[part 5 of 12: package /E40_Platform_System_SystemPackage/Components]
AUTOSAR XML (schema 4-2-1)
package /E40_Platform_System_SystemPackage/Components  (continued)
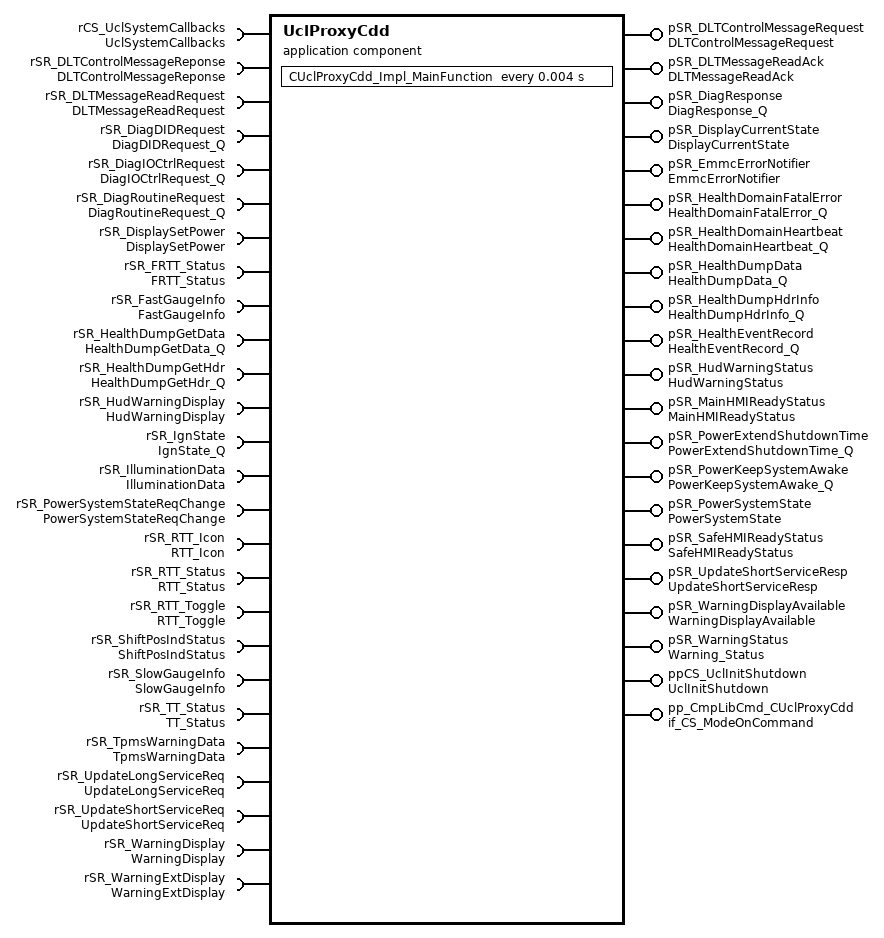
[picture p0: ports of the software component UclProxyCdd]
  application sw component type UclProxyCdd
    21 x provide port:
      pSR_DLTControlMessageRequest: nonqueued-sender-com-spec{data-element=DLTControlMessageRequestData, init-value=constant-reference=UclProxyCddDLTControlMessageRequestDataValue0}, provided-interface=DLTControlMessageRequest
      pSR_DLTMessageReadAck: nonqueued-sender-com-spec{data-element=DLTMessageReadAckData, init-value=constant-reference=UclProxyCddDLTMessageReadAckDataValue0}, provided-interface=DLTMessageReadAck
      pSR_DiagResponse: queued-sender-com-spec=DiagResponseData, provided-interface=DiagResponse_Q
      pSR_DisplayCurrentState: nonqueued-sender-com-spec{data-element=DisplayCurrentStateData, init-value=constant-reference=UclProxyCddDisplayCurrentStateDataValue0}, provided-interface=DisplayCurrentState
      pSR_EmmcErrorNotifier: nonqueued-sender-com-spec{data-element=EmmcErrorNotifierData, init-value=constant-reference=UclProxyCddEmmcErrorNotifierDataValue0}, provided-interface=EmmcErrorNotifier
      pSR_HealthDomainFatalError: queued-sender-com-spec=HealthDomainFatalErrorData, provided-interface=HealthDomainFatalError_Q
      pSR_HealthDomainHeartbeat: queued-sender-com-spec=HealthDomainHeartbeatData, provided-interface=HealthDomainHeartbeat_Q
      pSR_HealthDumpData: queued-sender-com-spec=HealthDumpDataData, provided-interface=HealthDumpData_Q
      pSR_HealthDumpHdrInfo: queued-sender-com-spec=HealthDumpHdrInfoData, provided-interface=HealthDumpHdrInfo_Q
      pSR_HealthEventRecord: queued-sender-com-spec=HealthEventRecordData, provided-interface=HealthEventRecord_Q
      pSR_HudWarningStatus: nonqueued-sender-com-spec{data-element=HudWarningStatusData, init-value=constant-reference=UclProxyCddHudWarningStatusDataValue0}, provided-interface=HudWarningStatus
      pSR_MainHMIReadyStatus: queued-sender-com-spec=MainHMIReadyStatusData, provided-interface=MainHMIReadyStatus
      pSR_PowerExtendShutdownTime: queued-sender-com-spec=PowerExtendShutdownTimeData, provided-interface=PowerExtendShutdownTime_Q
      pSR_PowerKeepSystemAwake: queued-sender-com-spec=PowerKeepSystemAwakeData, provided-interface=PowerKeepSystemAwake_Q
      pSR_PowerSystemState: nonqueued-sender-com-spec{data-element=PowerSystemStateData, init-value=constant-reference=UclProxyCddPowerSystemStateDataValue0}, provided-interface=PowerSystemState
      pSR_SafeHMIReadyStatus: queued-sender-com-spec=SafeHMIReadyStatusData, provided-interface=SafeHMIReadyStatus
      pSR_UpdateShortServiceResp: queued-sender-com-spec=UpdateShortServiceRespData, provided-interface=UpdateShortServiceResp
      pSR_WarningDisplayAvailable: nonqueued-sender-com-spec{data-element=WarningDisplayAvailableData, init-value=constant-reference=UclProxyCddWarningDisplayAvailableDataValue0}, provided-interface=WarningDisplayAvailable
      pSR_WarningStatus: nonqueued-sender-com-spec{data-element=WarningStatusData, init-value=constant-reference=UclProxyCddWarningStatusDataValue0}, provided-interface=Warning_Status
      ppCS_UclInitShutdown: provided-com-specs=[{operation=Impl_Initialize, queue-length=1}, {operation=Impl_Shutdown, queue-length=1}], provided-interface=UclInitShutdown
      pp_CmpLibCmd_CUclProxyCdd: server-com-spec{operation=Impl_OnCommand, queue-length=1}, provided-interface=if_CS_ModeOnCommand
    26 x require port:
      rCS_UclSystemCallbacks: required-interface=UclSystemCallbacks
      rSR_DLTControlMessageReponse: nonqueued-receiver-com-spec{data-element=DLTControlMessageReponseData, init-value=constant-reference=UclProxyCddDLTControlMessageReponseDataValue0}, required-interface=DLTControlMessageReponse
      rSR_DLTMessageReadRequest: nonqueued-receiver-com-spec{data-element=DLTMessageReadRequestData, init-value=constant-reference=UclProxyCddDLTMessageReadRequestDataValue0}, required-interface=DLTMessageReadRequest
      rSR_DiagDIDRequest: queued-receiver-com-spec{data-element=DiagDIDRequestData, queue-length=2}, required-interface=DiagDIDRequest_Q
      rSR_DiagIOCtrlRequest: queued-receiver-com-spec{data-element=DiagIOCtrlRequestData, queue-length=2}, required-interface=DiagIOCtrlRequest_Q
      rSR_DiagRoutineRequest: queued-receiver-com-spec{data-element=DiagRoutineRequestData, queue-length=2}, required-interface=DiagRoutineRequest_Q
      rSR_DisplaySetPower: nonqueued-receiver-com-spec{data-element=DisplaySetPower/DisplaySetPowerData, init-value=constant-reference=UclProxyCddDisplaySetPowerDataValue0}, required-interface=DisplaySetPower
      rSR_FRTT_Status: nonqueued-receiver-com-spec{data-element=FRTT_StatusData, init-value=constant-reference=UclProxyCddFRTT_StatusDataValue0}, required-interface=FRTT_Status
      rSR_FastGaugeInfo: nonqueued-receiver-com-spec{data-element=FastGaugeInfoData, init-value=constant-reference=UclProxyCddFastGaugeInfoDataValue0}, required-interface=FastGaugeInfo
      rSR_HealthDumpGetData: queued-receiver-com-spec{data-element=HealthDumpGetDataData, queue-length=1}, required-interface=HealthDumpGetData_Q
      rSR_HealthDumpGetHdr: queued-receiver-com-spec{data-element=HealthDumpGetHdrData, queue-length=1}, required-interface=HealthDumpGetHdr_Q
      rSR_HudWarningDisplay: nonqueued-receiver-com-spec{data-element=HudWarningDisplayData, init-value=constant-reference=UclProxyCddHudWarningDisplayDataValue0}, required-interface=HudWarningDisplay
      rSR_IgnState: queued-receiver-com-spec{data-element=IgnStateData, queue-length=5}, required-interface=IgnState_Q
      rSR_IlluminationData: nonqueued-receiver-com-spec{data-element=IlluminationDataData, init-value=constant-reference=UclProxyCddIlluminationDataDataValue0}, required-interface=IlluminationData
      rSR_PowerSystemStateReqChange: nonqueued-receiver-com-spec{data-element=PowerSystemStateReqChangeData, init-value=constant-reference=UclProxyCddPowerSystemStateReqChangeDataValue0}, required-interface=PowerSystemStateReqChange
      rSR_RTT_Icon: nonqueued-receiver-com-spec{data-element=RTT_IconData, init-value=constant-reference=UclProxyCddRTT_IconDataValue0}, required-interface=RTT_Icon
      rSR_RTT_Status: nonqueued-receiver-com-spec{data-element=RTT_StatusData, init-value=constant-reference=UclProxyCddRTT_StatusDataValue0}, required-interface=RTT_Status
      rSR_RTT_Toggle: nonqueued-receiver-com-spec{data-element=RTT_ToggleData, init-value=constant-reference=UclProxyCddRTT_ToggleDataValue0}, required-interface=RTT_Toggle
      rSR_ShiftPosIndStatus: nonqueued-receiver-com-spec{data-element=ShiftPosIndStatusData, init-value=constant-reference=UclProxyCddShiftPosIndStatusDataValue0}, required-interface=ShiftPosIndStatus
      rSR_SlowGaugeInfo: nonqueued-receiver-com-spec{data-element=SlowGaugeInfoData, init-value=constant-reference=UclProxyCddSlowGaugeInfoDataValue0}, required-interface=SlowGaugeInfo
      rSR_TT_Status: nonqueued-receiver-com-spec{data-element=TT_StatusData, init-value=constant-reference=UclProxyCddTT_StatusDataValue0}, required-interface=TT_Status
      rSR_TpmsWarningData: nonqueued-receiver-com-spec{data-element=TpmsWarningDataData, init-value=constant-reference=UclProxyCddTpmsWarningDataDataValue0}, required-interface=TpmsWarningData
      rSR_UpdateLongServiceReq: queued-receiver-com-spec{data-element=UpdateLongServiceReqData, queue-length=2}, required-interface=UpdateLongServiceReq
      rSR_UpdateShortServiceReq: queued-receiver-com-spec{data-element=UpdateShortServiceReqData, queue-length=2}, required-interface=UpdateShortServiceReq
      rSR_WarningDisplay: nonqueued-receiver-com-spec{data-element=WarningDisplayData, init-value=constant-reference=UclProxyCddWarningDisplayDataValue0}, required-interface=WarningDisplay
      rSR_WarningExtDisplay: nonqueued-receiver-com-spec{data-element=WarningExtDisplayData, init-value=constant-reference=UclProxyCddWarningExtDisplayDataValue0}, required-interface=WarningExtDisplay
    behavior IB_UclProxyCdd
      operation invoked event OIE_ppCS_UclInitShutdown_CUclProxyCdd_Impl_InitializeTrigByImpl_Initialize: start-on-event=CUclProxyCdd_Impl_Initialize, operation=ppCS_UclInitShutdown.Impl_Initialize
      timing event TECUclProxyCdd_Impl_MainFunction: start-on-event=CUclProxyCdd_Impl_MainFunction, period=0.004
      operation invoked event OIE_pp_CmpLibCmd_CUclProxyCdd_CUclProxyCdd_Impl_OnCommandTrigByImpl_OnCommand: start-on-event=CUclProxyCdd_Impl_OnCommand, operation=pp_CmpLibCmd_CUclProxyCdd.Impl_OnCommand
      operation invoked event OIE_ppCS_UclInitShutdown_CUclProxyCdd_Impl_ShutdownTrigByImpl_Shutdown: start-on-event=CUclProxyCdd_Impl_Shutdown, operation=ppCS_UclInitShutdown.Impl_Shutdown
      22 x data received event:
        DREOnDre_DLTControlMessageReponseTrigByDLTControlMessageReponseData: start-on-event=OnDre_DLTControlMessageReponse, data=rSR_DLTControlMessageReponse.DLTControlMessageReponseData
        DREOnDre_DLTMessageReadRequestTrigByDLTMessageReadRequestData: start-on-event=OnDre_DLTMessageReadRequest, data=rSR_DLTMessageReadRequest.DLTMessageReadRequestData
        DREOnDre_DiagDIDRequestTrigByDiagDIDRequestData: start-on-event=OnDre_DiagDIDRequest, data=rSR_DiagDIDRequest.DiagDIDRequestData
        DREOnDre_DiagIOCtrlRequestTrigByDiagIOCtrlRequestData: start-on-event=OnDre_DiagIOCtrlRequest, data=rSR_DiagIOCtrlRequest.DiagIOCtrlRequestData
        DREOnDre_DiagRoutineRequestTrigByDiagRoutineRequestData: start-on-event=OnDre_DiagRoutineRequest, data=rSR_DiagRoutineRequest.DiagRoutineRequestData
        DREOnDre_DisplaySetPowerTrigByDisplaySetPowerData: start-on-event=OnDre_DisplaySetPower, data=rSR_DisplaySetPower.DisplaySetPowerData
        DREOnDre_FRTT_StatusTrigByFRTT_StatusData: start-on-event=OnDre_FRTT_Status, data=rSR_FRTT_Status.FRTT_StatusData
        DREOnDre_FastGaugeInfoTrigByFastGaugeInfoData: start-on-event=OnDre_FastGaugeInfo, data=rSR_FastGaugeInfo.FastGaugeInfoData
        DREOnDre_HealthDumpGetDataTrigByHealthDumpGetDataData: start-on-event=OnDre_HealthDumpGetData, data=rSR_HealthDumpGetData.HealthDumpGetDataData
        DREOnDre_HealthDumpGetHdrTrigByHealthDumpGetHdrData: start-on-event=OnDre_HealthDumpGetHdr, data=rSR_HealthDumpGetHdr.HealthDumpGetHdrData
        DREOnDre_IlluminationDataTrigByIlluminationDataData: start-on-event=OnDre_IlluminationData, data=rSR_IlluminationData.IlluminationDataData
        DREOnDre_PowerSystemStateReqChangeTrigByPowerSystemStateReqChangeData: start-on-event=OnDre_PowerSystemStateReqChange, data=rSR_PowerSystemStateReqChange.PowerSystemStateReqChangeData
        DREOnDre_RTT_IconTrigByRTT_IconData: start-on-event=OnDre_RTT_Icon, data=rSR_RTT_Icon.RTT_IconData
        DREOnDre_RTT_StatusTrigByRTT_StatusData: start-on-event=OnDre_RTT_Status, data=rSR_RTT_Status.RTT_StatusData
        DREOnDre_RTT_ToggleTrigByRTT_ToggleData: start-on-event=OnDre_RTT_Toggle, data=rSR_RTT_Toggle.RTT_ToggleData
        DREOnDre_ShiftPosIndStatusTrigByShiftPosIndStatusData: start-on-event=OnDre_ShiftPosIndStatus, data=rSR_ShiftPosIndStatus.ShiftPosIndStatusData
        DREOnDre_SlowGaugeInfoTrigBySlowGaugeInfoData: start-on-event=OnDre_SlowGaugeInfo, data=rSR_SlowGaugeInfo.SlowGaugeInfoData
        DREOnDre_TT_StatusTrigByTT_StatusData: start-on-event=OnDre_TT_Status, data=rSR_TT_Status.TT_StatusData
        DREOnDre_UpdateLongServiceReqTrigByUpdateLongServiceReqData: start-on-event=OnDre_UpdateLongServiceReq, data=rSR_UpdateLongServiceReq.UpdateLongServiceReqData
        DREOnDre_UpdateShortServiceReqTrigByUpdateShortServiceReqData: start-on-event=OnDre_UpdateShortServiceReq, data=rSR_UpdateShortServiceReq.UpdateShortServiceReqData
        DREOnDre_WarningDisplayTrigByWarningDisplayData: start-on-event=OnDre_WarningDisplay, data=rSR_WarningDisplay.WarningDisplayData
        DREOnDre_WarningExtDisplayTrigByWarningExtDisplayData: start-on-event=OnDre_WarningExtDisplay, data=rSR_WarningExtDisplay.WarningExtDisplayData
      port-api-options:
        enable-take-address=false, indirect-api=false, port=pSR_DLTControlMessageRequest
        enable-take-address=false, indirect-api=false, port=pSR_DLTMessageReadAck
        enable-take-address=false, indirect-api=false, port=pSR_DiagResponse
        enable-take-address=false, indirect-api=false, port=pSR_DisplayCurrentState
        enable-take-address=false, indirect-api=false, port=pSR_EmmcErrorNotifier
        enable-take-address=false, indirect-api=false, port=pSR_HealthDomainFatalError
        enable-take-address=false, indirect-api=false, port=pSR_HealthDomainHeartbeat
        enable-take-address=false, indirect-api=false, port=pSR_HealthDumpData
        enable-take-address=false, indirect-api=false, port=pSR_HealthDumpHdrInfo
        enable-take-address=false, indirect-api=false, port=pSR_HealthEventRecord
        enable-take-address=false, indirect-api=false, port=pSR_HudWarningStatus
        enable-take-address=false, indirect-api=false, port=pSR_MainHMIReadyStatus
        enable-take-address=false, indirect-api=false, port=pSR_PowerExtendShutdownTime
        enable-take-address=false, indirect-api=false, port=pSR_PowerKeepSystemAwake
        enable-take-address=false, indirect-api=false, port=pSR_PowerSystemState
        enable-take-address=false, indirect-api=false, port=pSR_SafeHMIReadyStatus
        enable-take-address=false, indirect-api=false, port=pSR_UpdateShortServiceResp
        enable-take-address=false, indirect-api=false, port=pSR_WarningDisplayAvailable
        enable-take-address=false, indirect-api=false, port=pSR_WarningStatus
        enable-take-address=false, indirect-api=false, port=ppCS_UclInitShutdown
        enable-take-address=false, indirect-api=false, port=pp_CmpLibCmd_CUclProxyCdd
        enable-take-address=false, indirect-api=false, port=rCS_UclSystemCallbacks
        enable-take-address=false, indirect-api=false, port=rSR_DLTControlMessageReponse
        enable-take-address=false, indirect-api=false, port=rSR_DLTMessageReadRequest
        enable-take-address=false, indirect-api=false, port=rSR_DiagDIDRequest
        enable-take-address=false, indirect-api=false, port=rSR_DiagIOCtrlRequest
        enable-take-address=false, indirect-api=false, port=rSR_DiagRoutineRequest
        enable-take-address=false, indirect-api=false, port=rSR_DisplaySetPower
        enable-take-address=false, indirect-api=false, port=rSR_FRTT_Status
        enable-take-address=false, indirect-api=false, port=rSR_FastGaugeInfo
        enable-take-address=false, indirect-api=false, port=rSR_HealthDumpGetData
        enable-take-address=false, indirect-api=false, port=rSR_HealthDumpGetHdr
        enable-take-address=false, indirect-api=false, port=rSR_HudWarningDisplay
        enable-take-address=false, indirect-api=false, port=rSR_IgnState
        enable-take-address=false, indirect-api=false, port=rSR_IlluminationData
        enable-take-address=false, indirect-api=false, port=rSR_PowerSystemStateReqChange
        enable-take-address=false, indirect-api=false, port=rSR_RTT_Icon
        enable-take-address=false, indirect-api=false, port=rSR_RTT_Status
        enable-take-address=false, indirect-api=false, port=rSR_RTT_Toggle
        enable-take-address=false, indirect-api=false, port=rSR_ShiftPosIndStatus
        enable-take-address=false, indirect-api=false, port=rSR_SlowGaugeInfo
        enable-take-address=false, indirect-api=false, port=rSR_TT_Status
        enable-take-address=false, indirect-api=false, port=rSR_TpmsWarningData
        enable-take-address=false, indirect-api=false, port=rSR_UpdateLongServiceReq
        enable-take-address=false, indirect-api=false, port=rSR_UpdateShortServiceReq
        enable-take-address=false, indirect-api=false, port=rSR_WarningDisplay
        enable-take-address=false, indirect-api=false, port=rSR_WarningExtDisplay
      26 x runnable, all with can-be-invoked-concurrently=true:
        CUclProxyCdd_Impl_Initialize
        CUclProxyCdd_Impl_MainFunction
          data-receive-point-by-arguments:
            25 x access:
              DRA_rSR_DLTControlMessageReponse_DLTControlMessageReponseData: accessed-variable=rSR_DLTControlMessageReponse.DLTControlMessageReponseData
              DRA_rSR_DLTMessageReadRequest_DLTMessageReadRequestData: accessed-variable=rSR_DLTMessageReadRequest.DLTMessageReadRequestData
              DRP_rSR_DiagDIDRequest_DiagDIDRequestData: accessed-variable=rSR_DiagDIDRequest.DiagDIDRequestData
              DRP_rSR_DiagIOCtrlRequest_DiagIOCtrlRequestData: accessed-variable=rSR_DiagIOCtrlRequest.DiagIOCtrlRequestData
              DRP_rSR_DiagRoutineRequest_DiagRoutineRequestData: accessed-variable=rSR_DiagRoutineRequest.DiagRoutineRequestData
              DRA_rSR_DisplaySetPower_DisplaySetPowerData: accessed-variable=rSR_DisplaySetPower.DisplaySetPowerData
              DRA_rSR_FRTT_Status_FRTT_StatusData: accessed-variable=rSR_FRTT_Status.FRTT_StatusData
              DRA_rSR_FastGaugeInfo_FastGaugeInfoData: accessed-variable=rSR_FastGaugeInfo.FastGaugeInfoData
              DRP_rSR_HealthDumpGetData_HealthDumpGetDataData: accessed-variable=rSR_HealthDumpGetData.HealthDumpGetDataData
              DRP_rSR_HealthDumpGetHdr_HealthDumpGetHdrData: accessed-variable=rSR_HealthDumpGetHdr.HealthDumpGetHdrData
              DRA_rSR_HudWarningDisplay_HudWarningDisplayData: accessed-variable=rSR_HudWarningDisplay.HudWarningDisplayData
              DRP_rSR_IgnState_IgnStateData: accessed-variable=rSR_IgnState.IgnStateData
              DRA_rSR_IlluminationData_IlluminationDataData: accessed-variable=rSR_IlluminationData.IlluminationDataData
              DRA_rSR_PowerSystemStateReqChange_PowerSystemStateReqChangeData: accessed-variable=rSR_PowerSystemStateReqChange.PowerSystemStateReqChangeData
              DRA_rSR_RTT_Icon_RTT_IconData: accessed-variable=rSR_RTT_Icon.RTT_IconData
              DRA_rSR_RTT_Status_RTT_StatusData: accessed-variable=rSR_RTT_Status.RTT_StatusData
              DRA_rSR_RTT_Toggle_RTT_ToggleData: accessed-variable=rSR_RTT_Toggle.RTT_ToggleData
              DRA_rSR_ShiftPosIndStatus_ShiftPosIndStatusData: accessed-variable=rSR_ShiftPosIndStatus.ShiftPosIndStatusData
              DRA_rSR_SlowGaugeInfo_SlowGaugeInfoData: accessed-variable=rSR_SlowGaugeInfo.SlowGaugeInfoData
              DRA_rSR_TT_Status_TT_StatusData: accessed-variable=rSR_TT_Status.TT_StatusData
              DRA_rSR_TpmsWarningData_TpmsWarningDataData: accessed-variable=rSR_TpmsWarningData.TpmsWarningDataData
              DRP_rSR_UpdateLongServiceReq_UpdateLongServiceReqData: accessed-variable=rSR_UpdateLongServiceReq.UpdateLongServiceReqData
              DRP_rSR_UpdateShortServiceReq_UpdateShortServiceReqData: accessed-variable=rSR_UpdateShortServiceReq.UpdateShortServiceReqData
              DRA_rSR_WarningDisplay_WarningDisplayData: accessed-variable=rSR_WarningDisplay.WarningDisplayData
              DRA_rSR_WarningExtDisplay_WarningExtDisplayData: accessed-variable=rSR_WarningExtDisplay.WarningExtDisplayData
          data-send-points:
            19 x access:
              DWA_pSR_DLTControlMessageRequest_DLTControlMessageRequestData: accessed-variable=pSR_DLTControlMessageRequest.DLTControlMessageRequestData
              DWA_pSR_DLTMessageReadAck_DLTMessageReadAckData: accessed-variable=pSR_DLTMessageReadAck.DLTMessageReadAckData
              DSP_pSR_DiagResponse_DiagResponseData: accessed-variable=pSR_DiagResponse.DiagResponseData
              DWA_pSR_DisplayCurrentState_DisplayCurrentStateData: accessed-variable=pSR_DisplayCurrentState.DisplayCurrentStateData
              DWA_pSR_EmmcErrorNotifier_EmmcErrorNotifierData: accessed-variable=pSR_EmmcErrorNotifier.EmmcErrorNotifierData
              DSP_pSR_HealthDomainFatalError_HealthDomainFatalErrorData: accessed-variable=pSR_HealthDomainFatalError.HealthDomainFatalErrorData
              DSP_pSR_HealthDomainHeartbeat_HealthDomainHeartbeatData: accessed-variable=pSR_HealthDomainHeartbeat.HealthDomainHeartbeatData
              DSP_pSR_HealthDumpData_HealthDumpDataData: accessed-variable=pSR_HealthDumpData.HealthDumpDataData
              DSP_pSR_HealthDumpHdrInfo_HealthDumpHdrInfoData: accessed-variable=pSR_HealthDumpHdrInfo.HealthDumpHdrInfoData
              DSP_pSR_HealthEventRecord_HealthEventRecordData: accessed-variable=pSR_HealthEventRecord.HealthEventRecordData
              DWA_pSR_HudWarningStatus_HudWarningStatusData: accessed-variable=pSR_HudWarningStatus.HudWarningStatusData
              DSP_pSR_MainHMIReadyStatus_MainHMIReadyStatusData: accessed-variable=pSR_MainHMIReadyStatus.MainHMIReadyStatusData
              DSP_pSR_PowerExtendShutdownTime_PowerExtendShutdownTimeData: accessed-variable=pSR_PowerExtendShutdownTime.PowerExtendShutdownTimeData
              DSP_pSR_PowerKeepSystemAwake_PowerKeepSystemAwakeData: accessed-variable=pSR_PowerKeepSystemAwake.PowerKeepSystemAwakeData
              DWA_pSR_PowerSystemState_PowerSystemStateData: accessed-variable=pSR_PowerSystemState.PowerSystemStateData
              DSP_pSR_SafeHMIReadyStatus_SafeHMIReadyStatusData: accessed-variable=pSR_SafeHMIReadyStatus.SafeHMIReadyStatusData
              DSP_pSR_UpdateShortServiceResp_UpdateShortServiceRespData: accessed-variable=pSR_UpdateShortServiceResp.UpdateShortServiceRespData
              DWA_pSR_WarningDisplayAvailable_WarningDisplayAvailableData: accessed-variable=pSR_WarningDisplayAvailable.WarningDisplayAvailableData
              DWA_pSR_WarningStatus_WarningStatusData: accessed-variable=pSR_WarningStatus.WarningStatusData
          sync call OA_rCS_UclSystemCallbacks_ErrorNotification: operation=rCS_UclSystemCallbacks.ErrorNotification, timeout=0.0
          sync call OA_rCS_UclSystemCallbacks_LinkStatusChanged: operation=rCS_UclSystemCallbacks.LinkStatusChanged, timeout=0.0
        CUclProxyCdd_Impl_OnCommand
        CUclProxyCdd_Impl_Shutdown
        OnDre_DLTControlMessageReponse
          data-receive-point-by-arguments:
            25 x access:
              DRA_rSR_DLTControlMessageReponse_DLTControlMessageReponseData: accessed-variable=rSR_DLTControlMessageReponse.DLTControlMessageReponseData
              DRA_rSR_DLTMessageReadRequest_DLTMessageReadRequestData: accessed-variable=rSR_DLTMessageReadRequest.DLTMessageReadRequestData
              DRP_rSR_DiagDIDRequest_DiagDIDRequestData: accessed-variable=rSR_DiagDIDRequest.DiagDIDRequestData
              DRP_rSR_DiagIOCtrlRequest_DiagIOCtrlRequestData: accessed-variable=rSR_DiagIOCtrlRequest.DiagIOCtrlRequestData
              DRP_rSR_DiagRoutineRequest_DiagRoutineRequestData: accessed-variable=rSR_DiagRoutineRequest.DiagRoutineRequestData
              DRA_rSR_DisplaySetPower_DisplaySetPowerData: accessed-variable=rSR_DisplaySetPower.DisplaySetPowerData
              DRA_rSR_FRTT_Status_FRTT_StatusData: accessed-variable=rSR_FRTT_Status.FRTT_StatusData
              DRA_rSR_FastGaugeInfo_FastGaugeInfoData: accessed-variable=rSR_FastGaugeInfo.FastGaugeInfoData
              DRP_rSR_HealthDumpGetData_HealthDumpGetDataData: accessed-variable=rSR_HealthDumpGetData.HealthDumpGetDataData
              DRP_rSR_HealthDumpGetHdr_HealthDumpGetHdrData: accessed-variable=rSR_HealthDumpGetHdr.HealthDumpGetHdrData
              DRA_rSR_HudWarningDisplay_HudWarningDisplayData: accessed-variable=rSR_HudWarningDisplay.HudWarningDisplayData
              DRP_rSR_IgnState_IgnStateData: accessed-variable=rSR_IgnState.IgnStateData
              DRA_rSR_IlluminationData_IlluminationDataData: accessed-variable=rSR_IlluminationData.IlluminationDataData
              DRA_rSR_PowerSystemStateReqChange_PowerSystemStateReqChangeData: accessed-variable=rSR_PowerSystemStateReqChange.PowerSystemStateReqChangeData
              DRA_rSR_RTT_Icon_RTT_IconData: accessed-variable=rSR_RTT_Icon.RTT_IconData
              DRA_rSR_RTT_Status_RTT_StatusData: accessed-variable=rSR_RTT_Status.RTT_StatusData
              DRA_rSR_RTT_Toggle_RTT_ToggleData: accessed-variable=rSR_RTT_Toggle.RTT_ToggleData
              DRA_rSR_ShiftPosIndStatus_ShiftPosIndStatusData: accessed-variable=rSR_ShiftPosIndStatus.ShiftPosIndStatusData
              DRA_rSR_SlowGaugeInfo_SlowGaugeInfoData: accessed-variable=rSR_SlowGaugeInfo.SlowGaugeInfoData
              DRA_rSR_TT_Status_TT_StatusData: accessed-variable=rSR_TT_Status.TT_StatusData
              DRA_rSR_TpmsWarningData_TpmsWarningDataData: accessed-variable=rSR_TpmsWarningData.TpmsWarningDataData
              DRP_rSR_UpdateLongServiceReq_UpdateLongServiceReqData: accessed-variable=rSR_UpdateLongServiceReq.UpdateLongServiceReqData
              DRP_rSR_UpdateShortServiceReq_UpdateShortServiceReqData: accessed-variable=rSR_UpdateShortServiceReq.UpdateShortServiceReqData
              DRA_rSR_WarningDisplay_WarningDisplayData: accessed-variable=rSR_WarningDisplay.WarningDisplayData
              DRA_rSR_WarningExtDisplay_WarningExtDisplayData: accessed-variable=rSR_WarningExtDisplay.WarningExtDisplayData
          data-send-points:
            19 x access:
              DWA_pSR_DLTControlMessageRequest_DLTControlMessageRequestData: accessed-variable=pSR_DLTControlMessageRequest.DLTControlMessageRequestData
              DWA_pSR_DLTMessageReadAck_DLTMessageReadAckData: accessed-variable=pSR_DLTMessageReadAck.DLTMessageReadAckData
              DSP_pSR_DiagResponse_DiagResponseData: accessed-variable=pSR_DiagResponse.DiagResponseData
              DWA_pSR_DisplayCurrentState_DisplayCurrentStateData: accessed-variable=pSR_DisplayCurrentState.DisplayCurrentStateData
              DWA_pSR_EmmcErrorNotifier_EmmcErrorNotifierData: accessed-variable=pSR_EmmcErrorNotifier.EmmcErrorNotifierData
              DSP_pSR_HealthDomainFatalError_HealthDomainFatalErrorData: accessed-variable=pSR_HealthDomainFatalError.HealthDomainFatalErrorData
              DSP_pSR_HealthDomainHeartbeat_HealthDomainHeartbeatData: accessed-variable=pSR_HealthDomainHeartbeat.HealthDomainHeartbeatData
              DSP_pSR_HealthDumpData_HealthDumpDataData: accessed-variable=pSR_HealthDumpData.HealthDumpDataData
              DSP_pSR_HealthDumpHdrInfo_HealthDumpHdrInfoData: accessed-variable=pSR_HealthDumpHdrInfo.HealthDumpHdrInfoData
              DSP_pSR_HealthEventRecord_HealthEventRecordData: accessed-variable=pSR_HealthEventRecord.HealthEventRecordData
              DWA_pSR_HudWarningStatus_HudWarningStatusData: accessed-variable=pSR_HudWarningStatus.HudWarningStatusData
              DSP_pSR_MainHMIReadyStatus_MainHMIReadyStatusData: accessed-variable=pSR_MainHMIReadyStatus.MainHMIReadyStatusData
              DSP_pSR_PowerExtendShutdownTime_PowerExtendShutdownTimeData: accessed-variable=pSR_PowerExtendShutdownTime.PowerExtendShutdownTimeData
              DSP_pSR_PowerKeepSystemAwake_PowerKeepSystemAwakeData: accessed-variable=pSR_PowerKeepSystemAwake.PowerKeepSystemAwakeData
              DWA_pSR_PowerSystemState_PowerSystemStateData: accessed-variable=pSR_PowerSystemState.PowerSystemStateData
              DSP_pSR_SafeHMIReadyStatus_SafeHMIReadyStatusData: accessed-variable=pSR_SafeHMIReadyStatus.SafeHMIReadyStatusData
              DSP_pSR_UpdateShortServiceResp_UpdateShortServiceRespData: accessed-variable=pSR_UpdateShortServiceResp.UpdateShortServiceRespData
              DWA_pSR_WarningDisplayAvailable_WarningDisplayAvailableData: accessed-variable=pSR_WarningDisplayAvailable.WarningDisplayAvailableData
              DWA_pSR_WarningStatus_WarningStatusData: accessed-variable=pSR_WarningStatus.WarningStatusData
          sync call OA_rCS_UclSystemCallbacks_ErrorNotification: operation=rCS_UclSystemCallbacks.ErrorNotification, timeout=0.0
          sync call OA_rCS_UclSystemCallbacks_LinkStatusChanged: operation=rCS_UclSystemCallbacks.LinkStatusChanged, timeout=0.0
        OnDre_DLTMessageReadRequest
          data-receive-point-by-arguments:
            25 x access:
              DRA_rSR_DLTControlMessageReponse_DLTControlMessageReponseData: accessed-variable=rSR_DLTControlMessageReponse.DLTControlMessageReponseData
              DRA_rSR_DLTMessageReadRequest_DLTMessageReadRequestData: accessed-variable=rSR_DLTMessageReadRequest.DLTMessageReadRequestData
              DRP_rSR_DiagDIDRequest_DiagDIDRequestData: accessed-variable=rSR_DiagDIDRequest.DiagDIDRequestData
              DRP_rSR_DiagIOCtrlRequest_DiagIOCtrlRequestData: accessed-variable=rSR_DiagIOCtrlRequest.DiagIOCtrlRequestData
              DRP_rSR_DiagRoutineRequest_DiagRoutineRequestData: accessed-variable=rSR_DiagRoutineRequest.DiagRoutineRequestData
              DRA_rSR_DisplaySetPower_DisplaySetPowerData: accessed-variable=rSR_DisplaySetPower.DisplaySetPowerData
              DRA_rSR_FRTT_Status_FRTT_StatusData: accessed-variable=rSR_FRTT_Status.FRTT_StatusData
              DRA_rSR_FastGaugeInfo_FastGaugeInfoData: accessed-variable=rSR_FastGaugeInfo.FastGaugeInfoData
              DRP_rSR_HealthDumpGetData_HealthDumpGetDataData: accessed-variable=rSR_HealthDumpGetData.HealthDumpGetDataData
              DRP_rSR_HealthDumpGetHdr_HealthDumpGetHdrData: accessed-variable=rSR_HealthDumpGetHdr.HealthDumpGetHdrData
              DRA_rSR_HudWarningDisplay_HudWarningDisplayData: accessed-variable=rSR_HudWarningDisplay.HudWarningDisplayData
              DRP_rSR_IgnState_IgnStateData: accessed-variable=rSR_IgnState.IgnStateData
              DRA_rSR_IlluminationData_IlluminationDataData: accessed-variable=rSR_IlluminationData.IlluminationDataData
              DRA_rSR_PowerSystemStateReqChange_PowerSystemStateReqChangeData: accessed-variable=rSR_PowerSystemStateReqChange.PowerSystemStateReqChangeData
              DRA_rSR_RTT_Icon_RTT_IconData: accessed-variable=rSR_RTT_Icon.RTT_IconData
              DRA_rSR_RTT_Status_RTT_StatusData: accessed-variable=rSR_RTT_Status.RTT_StatusData
              DRA_rSR_RTT_Toggle_RTT_ToggleData: accessed-variable=rSR_RTT_Toggle.RTT_ToggleData
              DRA_rSR_ShiftPosIndStatus_ShiftPosIndStatusData: accessed-variable=rSR_ShiftPosIndStatus.ShiftPosIndStatusData
              DRA_rSR_SlowGaugeInfo_SlowGaugeInfoData: accessed-variable=rSR_SlowGaugeInfo.SlowGaugeInfoData
              DRA_rSR_TT_Status_TT_StatusData: accessed-variable=rSR_TT_Status.TT_StatusData
              DRA_rSR_TpmsWarningData_TpmsWarningDataData: accessed-variable=rSR_TpmsWarningData.TpmsWarningDataData
              DRP_rSR_UpdateLongServiceReq_UpdateLongServiceReqData: accessed-variable=rSR_UpdateLongServiceReq.UpdateLongServiceReqData
              DRP_rSR_UpdateShortServiceReq_UpdateShortServiceReqData: accessed-variable=rSR_UpdateShortServiceReq.UpdateShortServiceReqData
              DRA_rSR_WarningDisplay_WarningDisplayData: accessed-variable=rSR_WarningDisplay.WarningDisplayData
              DRA_rSR_WarningExtDisplay_WarningExtDisplayData: accessed-variable=rSR_WarningExtDisplay.WarningExtDisplayData
          data-send-points:
            19 x access:
              DWA_pSR_DLTControlMessageRequest_DLTControlMessageRequestData: accessed-variable=pSR_DLTControlMessageRequest.DLTControlMessageRequestData
              DWA_pSR_DLTMessageReadAck_DLTMessageReadAckData: accessed-variable=pSR_DLTMessageReadAck.DLTMessageReadAckData
              DSP_pSR_DiagResponse_DiagResponseData: accessed-variable=pSR_DiagResponse.DiagResponseData
              DWA_pSR_DisplayCurrentState_DisplayCurrentStateData: accessed-variable=pSR_DisplayCurrentState.DisplayCurrentStateData
              DWA_pSR_EmmcErrorNotifier_EmmcErrorNotifierData: accessed-variable=pSR_EmmcErrorNotifier.EmmcErrorNotifierData
              DSP_pSR_HealthDomainFatalError_HealthDomainFatalErrorData: accessed-variable=pSR_HealthDomainFatalError.HealthDomainFatalErrorData
              DSP_pSR_HealthDomainHeartbeat_HealthDomainHeartbeatData: accessed-variable=pSR_HealthDomainHeartbeat.HealthDomainHeartbeatData
              DSP_pSR_HealthDumpData_HealthDumpDataData: accessed-variable=pSR_HealthDumpData.HealthDumpDataData
              DSP_pSR_HealthDumpHdrInfo_HealthDumpHdrInfoData: accessed-variable=pSR_HealthDumpHdrInfo.HealthDumpHdrInfoData
              DSP_pSR_HealthEventRecord_HealthEventRecordData: accessed-variable=pSR_HealthEventRecord.HealthEventRecordData
              DWA_pSR_HudWarningStatus_HudWarningStatusData: accessed-variable=pSR_HudWarningStatus.HudWarningStatusData
              DSP_pSR_MainHMIReadyStatus_MainHMIReadyStatusData: accessed-variable=pSR_MainHMIReadyStatus.MainHMIReadyStatusData
              DSP_pSR_PowerExtendShutdownTime_PowerExtendShutdownTimeData: accessed-variable=pSR_PowerExtendShutdownTime.PowerExtendShutdownTimeData
              DSP_pSR_PowerKeepSystemAwake_PowerKeepSystemAwakeData: accessed-variable=pSR_PowerKeepSystemAwake.PowerKeepSystemAwakeData
              DWA_pSR_PowerSystemState_PowerSystemStateData: accessed-variable=pSR_PowerSystemState.PowerSystemStateData
              DSP_pSR_SafeHMIReadyStatus_SafeHMIReadyStatusData: accessed-variable=pSR_SafeHMIReadyStatus.SafeHMIReadyStatusData
              DSP_pSR_UpdateShortServiceResp_UpdateShortServiceRespData: accessed-variable=pSR_UpdateShortServiceResp.UpdateShortServiceRespData
              DWA_pSR_WarningDisplayAvailable_WarningDisplayAvailableData: accessed-variable=pSR_WarningDisplayAvailable.WarningDisplayAvailableData
              DWA_pSR_WarningStatus_WarningStatusData: accessed-variable=pSR_WarningStatus.WarningStatusData
          sync call OA_rCS_UclSystemCallbacks_ErrorNotification: operation=rCS_UclSystemCallbacks.ErrorNotification, timeout=0.0
          sync call OA_rCS_UclSystemCallbacks_LinkStatusChanged: operation=rCS_UclSystemCallbacks.LinkStatusChanged, timeout=0.0
        OnDre_DiagDIDRequest
          data-receive-point-by-arguments:
            25 x access:
              DRA_rSR_DLTControlMessageReponse_DLTControlMessageReponseData: accessed-variable=rSR_DLTControlMessageReponse.DLTControlMessageReponseData
              DRA_rSR_DLTMessageReadRequest_DLTMessageReadRequestData: accessed-variable=rSR_DLTMessageReadRequest.DLTMessageReadRequestData
              DRP_rSR_DiagDIDRequest_DiagDIDRequestData: accessed-variable=rSR_DiagDIDRequest.DiagDIDRequestData
              DRP_rSR_DiagIOCtrlRequest_DiagIOCtrlRequestData: accessed-variable=rSR_DiagIOCtrlRequest.DiagIOCtrlRequestData
              DRP_rSR_DiagRoutineRequest_DiagRoutineRequestData: accessed-variable=rSR_DiagRoutineRequest.DiagRoutineRequestData
              DRA_rSR_DisplaySetPower_DisplaySetPowerData: accessed-variable=rSR_DisplaySetPower.DisplaySetPowerData
              DRA_rSR_FRTT_Status_FRTT_StatusData: accessed-variable=rSR_FRTT_Status.FRTT_StatusData
              DRA_rSR_FastGaugeInfo_FastGaugeInfoData: accessed-variable=rSR_FastGaugeInfo.FastGaugeInfoData
              DRP_rSR_HealthDumpGetData_HealthDumpGetDataData: accessed-variable=rSR_HealthDumpGetData.HealthDumpGetDataData
              DRP_rSR_HealthDumpGetHdr_HealthDumpGetHdrData: accessed-variable=rSR_HealthDumpGetHdr.HealthDumpGetHdrData
              DRA_rSR_HudWarningDisplay_HudWarningDisplayData: accessed-variable=rSR_HudWarningDisplay.HudWarningDisplayData
              DRP_rSR_IgnState_IgnStateData: accessed-variable=rSR_IgnState.IgnStateData
              DRA_rSR_IlluminationData_IlluminationDataData: accessed-variable=rSR_IlluminationData.IlluminationDataData
              DRA_rSR_PowerSystemStateReqChange_PowerSystemStateReqChangeData: accessed-variable=rSR_PowerSystemStateReqChange.PowerSystemStateReqChangeData
              DRA_rSR_RTT_Icon_RTT_IconData: accessed-variable=rSR_RTT_Icon.RTT_IconData
              DRA_rSR_RTT_Status_RTT_StatusData: accessed-variable=rSR_RTT_Status.RTT_StatusData
              DRA_rSR_RTT_Toggle_RTT_ToggleData: accessed-variable=rSR_RTT_Toggle.RTT_ToggleData
              DRA_rSR_ShiftPosIndStatus_ShiftPosIndStatusData: accessed-variable=rSR_ShiftPosIndStatus.ShiftPosIndStatusData
              DRA_rSR_SlowGaugeInfo_SlowGaugeInfoData: accessed-variable=rSR_SlowGaugeInfo.SlowGaugeInfoData
              DRA_rSR_TT_Status_TT_StatusData: accessed-variable=rSR_TT_Status.TT_StatusData
              DRA_rSR_TpmsWarningData_TpmsWarningDataData: accessed-variable=rSR_TpmsWarningData.TpmsWarningDataData
              DRP_rSR_UpdateLongServiceReq_UpdateLongServiceReqData: accessed-variable=rSR_UpdateLongServiceReq.UpdateLongServiceReqData
              DRP_rSR_UpdateShortServiceReq_UpdateShortServiceReqData: accessed-variable=rSR_UpdateShortServiceReq.UpdateShortServiceReqData
              DRA_rSR_WarningDisplay_WarningDisplayData: accessed-variable=rSR_WarningDisplay.WarningDisplayData
              DRA_rSR_WarningExtDisplay_WarningExtDisplayData: accessed-variable=rSR_WarningExtDisplay.WarningExtDisplayData
          data-send-points:
            19 x access:
              DWA_pSR_DLTControlMessageRequest_DLTControlMessageRequestData: accessed-variable=pSR_DLTControlMessageRequest.DLTControlMessageRequestData
              DWA_pSR_DLTMessageReadAck_DLTMessageReadAckData: accessed-variable=pSR_DLTMessageReadAck.DLTMessageReadAckData
              DSP_pSR_DiagResponse_DiagResponseData: accessed-variable=pSR_DiagResponse.DiagResponseData
              DWA_pSR_DisplayCurrentState_DisplayCurrentStateData: accessed-variable=pSR_DisplayCurrentState.DisplayCurrentStateData
              DWA_pSR_EmmcErrorNotifier_EmmcErrorNotifierData: accessed-variable=pSR_EmmcErrorNotifier.EmmcErrorNotifierData
              DSP_pSR_HealthDomainFatalError_HealthDomainFatalErrorData: accessed-variable=pSR_HealthDomainFatalError.HealthDomainFatalErrorData
              DSP_pSR_HealthDomainHeartbeat_HealthDomainHeartbeatData: accessed-variable=pSR_HealthDomainHeartbeat.HealthDomainHeartbeatData
              DSP_pSR_HealthDumpData_HealthDumpDataData: accessed-variable=pSR_HealthDumpData.HealthDumpDataData
              DSP_pSR_HealthDumpHdrInfo_HealthDumpHdrInfoData: accessed-variable=pSR_HealthDumpHdrInfo.HealthDumpHdrInfoData
              DSP_pSR_HealthEventRecord_HealthEventRecordData: accessed-variable=pSR_HealthEventRecord.HealthEventRecordData
              DWA_pSR_HudWarningStatus_HudWarningStatusData: accessed-variable=pSR_HudWarningStatus.HudWarningStatusData
              DSP_pSR_MainHMIReadyStatus_MainHMIReadyStatusData: accessed-variable=pSR_MainHMIReadyStatus.MainHMIReadyStatusData
              DSP_pSR_PowerExtendShutdownTime_PowerExtendShutdownTimeData: accessed-variable=pSR_PowerExtendShutdownTime.PowerExtendShutdownTimeData
              DSP_pSR_PowerKeepSystemAwake_PowerKeepSystemAwakeData: accessed-variable=pSR_PowerKeepSystemAwake.PowerKeepSystemAwakeData
              DWA_pSR_PowerSystemState_PowerSystemStateData: accessed-variable=pSR_PowerSystemState.PowerSystemStateData
              DSP_pSR_SafeHMIReadyStatus_SafeHMIReadyStatusData: accessed-variable=pSR_SafeHMIReadyStatus.SafeHMIReadyStatusData
              DSP_pSR_UpdateShortServiceResp_UpdateShortServiceRespData: accessed-variable=pSR_UpdateShortServiceResp.UpdateShortServiceRespData
              DWA_pSR_WarningDisplayAvailable_WarningDisplayAvailableData: accessed-variable=pSR_WarningDisplayAvailable.WarningDisplayAvailableData
              DWA_pSR_WarningStatus_WarningStatusData: accessed-variable=pSR_WarningStatus.WarningStatusData
          sync call OA_rCS_UclSystemCallbacks_ErrorNotification: operation=rCS_UclSystemCallbacks.ErrorNotification, timeout=0.0
          sync call OA_rCS_UclSystemCallbacks_LinkStatusChanged: operation=rCS_UclSystemCallbacks.LinkStatusChanged, timeout=0.0
        OnDre_DiagIOCtrlRequest
          data-receive-point-by-arguments:
            25 x access:
              DRA_rSR_DLTControlMessageReponse_DLTControlMessageReponseData: accessed-variable=rSR_DLTControlMessageReponse.DLTControlMessageReponseData
              DRA_rSR_DLTMessageReadRequest_DLTMessageReadRequestData: accessed-variable=rSR_DLTMessageReadRequest.DLTMessageReadRequestData
              DRP_rSR_DiagDIDRequest_DiagDIDRequestData: accessed-variable=rSR_DiagDIDRequest.DiagDIDRequestData
              DRP_rSR_DiagIOCtrlRequest_DiagIOCtrlRequestData: accessed-variable=rSR_DiagIOCtrlRequest.DiagIOCtrlRequestData
              DRP_rSR_DiagRoutineRequest_DiagRoutineRequestData: accessed-variable=rSR_DiagRoutineRequest.DiagRoutineRequestData
              DRA_rSR_DisplaySetPower_DisplaySetPowerData: accessed-variable=rSR_DisplaySetPower.DisplaySetPowerData
              DRA_rSR_FRTT_Status_FRTT_StatusData: accessed-variable=rSR_FRTT_Status.FRTT_StatusData
              DRA_rSR_FastGaugeInfo_FastGaugeInfoData: accessed-variable=rSR_FastGaugeInfo.FastGaugeInfoData
              DRP_rSR_HealthDumpGetData_HealthDumpGetDataData: accessed-variable=rSR_HealthDumpGetData.HealthDumpGetDataData
              DRP_rSR_HealthDumpGetHdr_HealthDumpGetHdrData: accessed-variable=rSR_HealthDumpGetHdr.HealthDumpGetHdrData
              DRA_rSR_HudWarningDisplay_HudWarningDisplayData: accessed-variable=rSR_HudWarningDisplay.HudWarningDisplayData
              DRP_rSR_IgnState_IgnStateData: accessed-variable=rSR_IgnState.IgnStateData
              DRA_rSR_IlluminationData_IlluminationDataData: accessed-variable=rSR_IlluminationData.IlluminationDataData
              DRA_rSR_PowerSystemStateReqChange_PowerSystemStateReqChangeData: accessed-variable=rSR_PowerSystemStateReqChange.PowerSystemStateReqChangeData
              DRA_rSR_RTT_Icon_RTT_IconData: accessed-variable=rSR_RTT_Icon.RTT_IconData
              DRA_rSR_RTT_Status_RTT_StatusData: accessed-variable=rSR_RTT_Status.RTT_StatusData
              DRA_rSR_RTT_Toggle_RTT_ToggleData: accessed-variable=rSR_RTT_Toggle.RTT_ToggleData
              DRA_rSR_ShiftPosIndStatus_ShiftPosIndStatusData: accessed-variable=rSR_ShiftPosIndStatus.ShiftPosIndStatusData
              DRA_rSR_SlowGaugeInfo_SlowGaugeInfoData: accessed-variable=rSR_SlowGaugeInfo.SlowGaugeInfoData
              DRA_rSR_TT_Status_TT_StatusData: accessed-variable=rSR_TT_Status.TT_StatusData
              DRA_rSR_TpmsWarningData_TpmsWarningDataData: accessed-variable=rSR_TpmsWarningData.TpmsWarningDataData
              DRP_rSR_UpdateLongServiceReq_UpdateLongServiceReqData: accessed-variable=rSR_UpdateLongServiceReq.UpdateLongServiceReqData
              DRP_rSR_UpdateShortServiceReq_UpdateShortServiceReqData: accessed-variable=rSR_UpdateShortServiceReq.UpdateShortServiceReqData
              DRA_rSR_WarningDisplay_WarningDisplayData: accessed-variable=rSR_WarningDisplay.WarningDisplayData
              DRA_rSR_WarningExtDisplay_WarningExtDisplayData: accessed-variable=rSR_WarningExtDisplay.WarningExtDisplayData
          data-send-points:
            19 x access:
              DWA_pSR_DLTControlMessageRequest_DLTControlMessageRequestData: accessed-variable=pSR_DLTControlMessageRequest.DLTControlMessageRequestData
              DWA_pSR_DLTMessageReadAck_DLTMessageReadAckData: accessed-variable=pSR_DLTMessageReadAck.DLTMessageReadAckData
              DSP_pSR_DiagResponse_DiagResponseData: accessed-variable=pSR_DiagResponse.DiagResponseData
              DWA_pSR_DisplayCurrentState_DisplayCurrentStateData: accessed-variable=pSR_DisplayCurrentState.DisplayCurrentStateData
              DWA_pSR_EmmcErrorNotifier_EmmcErrorNotifierData: accessed-variable=pSR_EmmcErrorNotifier.EmmcErrorNotifierData
              DSP_pSR_HealthDomainFatalError_HealthDomainFatalErrorData: accessed-variable=pSR_HealthDomainFatalError.HealthDomainFatalErrorData
              DSP_pSR_HealthDomainHeartbeat_HealthDomainHeartbeatData: accessed-variable=pSR_HealthDomainHeartbeat.HealthDomainHeartbeatData
              DSP_pSR_HealthDumpData_HealthDumpDataData: accessed-variable=pSR_HealthDumpData.HealthDumpDataData
              DSP_pSR_HealthDumpHdrInfo_HealthDumpHdrInfoData: accessed-variable=pSR_HealthDumpHdrInfo.HealthDumpHdrInfoData
              DSP_pSR_HealthEventRecord_HealthEventRecordData: accessed-variable=pSR_HealthEventRecord.HealthEventRecordData
              DWA_pSR_HudWarningStatus_HudWarningStatusData: accessed-variable=pSR_HudWarningStatus.HudWarningStatusData
              DSP_pSR_MainHMIReadyStatus_MainHMIReadyStatusData: accessed-variable=pSR_MainHMIReadyStatus.MainHMIReadyStatusData
              DSP_pSR_PowerExtendShutdownTime_PowerExtendShutdownTimeData: accessed-variable=pSR_PowerExtendShutdownTime.PowerExtendShutdownTimeData
              DSP_pSR_PowerKeepSystemAwake_PowerKeepSystemAwakeData: accessed-variable=pSR_PowerKeepSystemAwake.PowerKeepSystemAwakeData
              DWA_pSR_PowerSystemState_PowerSystemStateData: accessed-variable=pSR_PowerSystemState.PowerSystemStateData
              DSP_pSR_SafeHMIReadyStatus_SafeHMIReadyStatusData: accessed-variable=pSR_SafeHMIReadyStatus.SafeHMIReadyStatusData
              DSP_pSR_UpdateShortServiceResp_UpdateShortServiceRespData: accessed-variable=pSR_UpdateShortServiceResp.UpdateShortServiceRespData
              DWA_pSR_WarningDisplayAvailable_WarningDisplayAvailableData: accessed-variable=pSR_WarningDisplayAvailable.WarningDisplayAvailableData
              DWA_pSR_WarningStatus_WarningStatusData: accessed-variable=pSR_WarningStatus.WarningStatusData
          sync call OA_rCS_UclSystemCallbacks_ErrorNotification: operation=rCS_UclSystemCallbacks.ErrorNotification, timeout=0.0
          sync call OA_rCS_UclSystemCallbacks_LinkStatusChanged: operation=rCS_UclSystemCallbacks.LinkStatusChanged, timeout=0.0
        OnDre_DiagRoutineRequest
          data-receive-point-by-arguments:
            25 x access:
              DRA_rSR_DLTControlMessageReponse_DLTControlMessageReponseData: accessed-variable=rSR_DLTControlMessageReponse.DLTControlMessageReponseData
              DRA_rSR_DLTMessageReadRequest_DLTMessageReadRequestData: accessed-variable=rSR_DLTMessageReadRequest.DLTMessageReadRequestData
              DRP_rSR_DiagDIDRequest_DiagDIDRequestData: accessed-variable=rSR_DiagDIDRequest.DiagDIDRequestData
              DRP_rSR_DiagIOCtrlRequest_DiagIOCtrlRequestData: accessed-variable=rSR_DiagIOCtrlRequest.DiagIOCtrlRequestData
              DRP_rSR_DiagRoutineRequest_DiagRoutineRequestData: accessed-variable=rSR_DiagRoutineRequest.DiagRoutineRequestData
              DRA_rSR_DisplaySetPower_DisplaySetPowerData: accessed-variable=rSR_DisplaySetPower.DisplaySetPowerData
              DRA_rSR_FRTT_Status_FRTT_StatusData: accessed-variable=rSR_FRTT_Status.FRTT_StatusData
              DRA_rSR_FastGaugeInfo_FastGaugeInfoData: accessed-variable=rSR_FastGaugeInfo.FastGaugeInfoData
              DRP_rSR_HealthDumpGetData_HealthDumpGetDataData: accessed-variable=rSR_HealthDumpGetData.HealthDumpGetDataData
              DRP_rSR_HealthDumpGetHdr_HealthDumpGetHdrData: accessed-variable=rSR_HealthDumpGetHdr.HealthDumpGetHdrData
              DRA_rSR_HudWarningDisplay_HudWarningDisplayData: accessed-variable=rSR_HudWarningDisplay.HudWarningDisplayData
              DRP_rSR_IgnState_IgnStateData: accessed-variable=rSR_IgnState.IgnStateData
              DRA_rSR_IlluminationData_IlluminationDataData: accessed-variable=rSR_IlluminationData.IlluminationDataData
              DRA_rSR_PowerSystemStateReqChange_PowerSystemStateReqChangeData: accessed-variable=rSR_PowerSystemStateReqChange.PowerSystemStateReqChangeData
              DRA_rSR_RTT_Icon_RTT_IconData: accessed-variable=rSR_RTT_Icon.RTT_IconData
              DRA_rSR_RTT_Status_RTT_StatusData: accessed-variable=rSR_RTT_Status.RTT_StatusData
              DRA_rSR_RTT_Toggle_RTT_ToggleData: accessed-variable=rSR_RTT_Toggle.RTT_ToggleData
              DRA_rSR_ShiftPosIndStatus_ShiftPosIndStatusData: accessed-variable=rSR_ShiftPosIndStatus.ShiftPosIndStatusData
              DRA_rSR_SlowGaugeInfo_SlowGaugeInfoData: accessed-variable=rSR_SlowGaugeInfo.SlowGaugeInfoData
              DRA_rSR_TT_Status_TT_StatusData: accessed-variable=rSR_TT_Status.TT_StatusData
              DRA_rSR_TpmsWarningData_TpmsWarningDataData: accessed-variable=rSR_TpmsWarningData.TpmsWarningDataData
              DRP_rSR_UpdateLongServiceReq_UpdateLongServiceReqData: accessed-variable=rSR_UpdateLongServiceReq.UpdateLongServiceReqData
              DRP_rSR_UpdateShortServiceReq_UpdateShortServiceReqData: accessed-variable=rSR_UpdateShortServiceReq.UpdateShortServiceReqData
              DRA_rSR_WarningDisplay_WarningDisplayData: accessed-variable=rSR_WarningDisplay.WarningDisplayData
              DRA_rSR_WarningExtDisplay_WarningExtDisplayData: accessed-variable=rSR_WarningExtDisplay.WarningExtDisplayData
          data-send-points:
            19 x access:
              DWA_pSR_DLTControlMessageRequest_DLTControlMessageRequestData: accessed-variable=pSR_DLTControlMessageRequest.DLTControlMessageRequestData
              DWA_pSR_DLTMessageReadAck_DLTMessageReadAckData: accessed-variable=pSR_DLTMessageReadAck.DLTMessageReadAckData
              DSP_pSR_DiagResponse_DiagResponseData: accessed-variable=pSR_DiagResponse.DiagResponseData
              DWA_pSR_DisplayCurrentState_DisplayCurrentStateData: accessed-variable=pSR_DisplayCurrentState.DisplayCurrentStateData
              DWA_pSR_EmmcErrorNotifier_EmmcErrorNotifierData: accessed-variable=pSR_EmmcErrorNotifier.EmmcErrorNotifierData
              DSP_pSR_HealthDomainFatalError_HealthDomainFatalErrorData: accessed-variable=pSR_HealthDomainFatalError.HealthDomainFatalErrorData
              DSP_pSR_HealthDomainHeartbeat_HealthDomainHeartbeatData: accessed-variable=pSR_HealthDomainHeartbeat.HealthDomainHeartbeatData
              DSP_pSR_HealthDumpData_HealthDumpDataData: accessed-variable=pSR_HealthDumpData.HealthDumpDataData
              DSP_pSR_HealthDumpHdrInfo_HealthDumpHdrInfoData: accessed-variable=pSR_HealthDumpHdrInfo.HealthDumpHdrInfoData
              DSP_pSR_HealthEventRecord_HealthEventRecordData: accessed-variable=pSR_HealthEventRecord.HealthEventRecordData
              DWA_pSR_HudWarningStatus_HudWarningStatusData: accessed-variable=pSR_HudWarningStatus.HudWarningStatusData
              DSP_pSR_MainHMIReadyStatus_MainHMIReadyStatusData: accessed-variable=pSR_MainHMIReadyStatus.MainHMIReadyStatusData
              DSP_pSR_PowerExtendShutdownTime_PowerExtendShutdownTimeData: accessed-variable=pSR_PowerExtendShutdownTime.PowerExtendShutdownTimeData
              DSP_pSR_PowerKeepSystemAwake_PowerKeepSystemAwakeData: accessed-variable=pSR_PowerKeepSystemAwake.PowerKeepSystemAwakeData
              DWA_pSR_PowerSystemState_PowerSystemStateData: accessed-variable=pSR_PowerSystemState.PowerSystemStateData
              DSP_pSR_SafeHMIReadyStatus_SafeHMIReadyStatusData: accessed-variable=pSR_SafeHMIReadyStatus.SafeHMIReadyStatusData
              DSP_pSR_UpdateShortServiceResp_UpdateShortServiceRespData: accessed-variable=pSR_UpdateShortServiceResp.UpdateShortServiceRespData
              DWA_pSR_WarningDisplayAvailable_WarningDisplayAvailableData: accessed-variable=pSR_WarningDisplayAvailable.WarningDisplayAvailableData
              DWA_pSR_WarningStatus_WarningStatusData: accessed-variable=pSR_WarningStatus.WarningStatusData
          sync call OA_rCS_UclSystemCallbacks_ErrorNotification: operation=rCS_UclSystemCallbacks.ErrorNotification, timeout=0.0
          sync call OA_rCS_UclSystemCallbacks_LinkStatusChanged: operation=rCS_UclSystemCallbacks.LinkStatusChanged, timeout=0.0
        OnDre_DisplaySetPower
          data-receive-point-by-arguments:
            25 x access:
              DRA_rSR_DLTControlMessageReponse_DLTControlMessageReponseData: accessed-variable=rSR_DLTControlMessageReponse.DLTControlMessageReponseData
              DRA_rSR_DLTMessageReadRequest_DLTMessageReadRequestData: accessed-variable=rSR_DLTMessageReadRequest.DLTMessageReadRequestData
              DRP_rSR_DiagDIDRequest_DiagDIDRequestData: accessed-variable=rSR_DiagDIDRequest.DiagDIDRequestData
              DRP_rSR_DiagIOCtrlRequest_DiagIOCtrlRequestData: accessed-variable=rSR_DiagIOCtrlRequest.DiagIOCtrlRequestData
              DRP_rSR_DiagRoutineRequest_DiagRoutineRequestData: accessed-variable=rSR_DiagRoutineRequest.DiagRoutineRequestData
              DRA_rSR_DisplaySetPower_DisplaySetPowerData: accessed-variable=rSR_DisplaySetPower.DisplaySetPowerData
              DRA_rSR_FRTT_Status_FRTT_StatusData: accessed-variable=rSR_FRTT_Status.FRTT_StatusData
              DRA_rSR_FastGaugeInfo_FastGaugeInfoData: accessed-variable=rSR_FastGaugeInfo.FastGaugeInfoData
              DRP_rSR_HealthDumpGetData_HealthDumpGetDataData: accessed-variable=rSR_HealthDumpGetData.HealthDumpGetDataData
              DRP_rSR_HealthDumpGetHdr_HealthDumpGetHdrData: accessed-variable=rSR_HealthDumpGetHdr.HealthDumpGetHdrData
              DRA_rSR_HudWarningDisplay_HudWarningDisplayData: accessed-variable=rSR_HudWarningDisplay.HudWarningDisplayData
              DRP_rSR_IgnState_IgnStateData: accessed-variable=rSR_IgnState.IgnStateData
              DRA_rSR_IlluminationData_IlluminationDataData: accessed-variable=rSR_IlluminationData.IlluminationDataData
              DRA_rSR_PowerSystemStateReqChange_PowerSystemStateReqChangeData: accessed-variable=rSR_PowerSystemStateReqChange.PowerSystemStateReqChangeData
              DRA_rSR_RTT_Icon_RTT_IconData: accessed-variable=rSR_RTT_Icon.RTT_IconData
              DRA_rSR_RTT_Status_RTT_StatusData: accessed-variable=rSR_RTT_Status.RTT_StatusData
              DRA_rSR_RTT_Toggle_RTT_ToggleData: accessed-variable=rSR_RTT_Toggle.RTT_ToggleData
              DRA_rSR_ShiftPosIndStatus_ShiftPosIndStatusData: accessed-variable=rSR_ShiftPosIndStatus.ShiftPosIndStatusData
              DRA_rSR_SlowGaugeInfo_SlowGaugeInfoData: accessed-variable=rSR_SlowGaugeInfo.SlowGaugeInfoData
              DRA_rSR_TT_Status_TT_StatusData: accessed-variable=rSR_TT_Status.TT_StatusData
              DRA_rSR_TpmsWarningData_TpmsWarningDataData: accessed-variable=rSR_TpmsWarningData.TpmsWarningDataData
              DRP_rSR_UpdateLongServiceReq_UpdateLongServiceReqData: accessed-variable=rSR_UpdateLongServiceReq.UpdateLongServiceReqData
              DRP_rSR_UpdateShortServiceReq_UpdateShortServiceReqData: accessed-variable=rSR_UpdateShortServiceReq.UpdateShortServiceReqData
              DRA_rSR_WarningDisplay_WarningDisplayData: accessed-variable=rSR_WarningDisplay.WarningDisplayData
              DRA_rSR_WarningExtDisplay_WarningExtDisplayData: accessed-variable=rSR_WarningExtDisplay.WarningExtDisplayData
          data-send-points:
            19 x access:
              DWA_pSR_DLTControlMessageRequest_DLTControlMessageRequestData: accessed-variable=pSR_DLTControlMessageRequest.DLTControlMessageRequestData
              DWA_pSR_DLTMessageReadAck_DLTMessageReadAckData: accessed-variable=pSR_DLTMessageReadAck.DLTMessageReadAckData
              DSP_pSR_DiagResponse_DiagResponseData: accessed-variable=pSR_DiagResponse.DiagResponseData
              DWA_pSR_DisplayCurrentState_DisplayCurrentStateData: accessed-variable=pSR_DisplayCurrentState.DisplayCurrentStateData
              DWA_pSR_EmmcErrorNotifier_EmmcErrorNotifierData: accessed-variable=pSR_EmmcErrorNotifier.EmmcErrorNotifierData
              DSP_pSR_HealthDomainFatalError_HealthDomainFatalErrorData: accessed-variable=pSR_HealthDomainFatalError.HealthDomainFatalErrorData
              DSP_pSR_HealthDomainHeartbeat_HealthDomainHeartbeatData: accessed-variable=pSR_HealthDomainHeartbeat.HealthDomainHeartbeatData
              DSP_pSR_HealthDumpData_HealthDumpDataData: accessed-variable=pSR_HealthDumpData.HealthDumpDataData
              DSP_pSR_HealthDumpHdrInfo_HealthDumpHdrInfoData: accessed-variable=pSR_HealthDumpHdrInfo.HealthDumpHdrInfoData
              DSP_pSR_HealthEventRecord_HealthEventRecordData: accessed-variable=pSR_HealthEventRecord.HealthEventRecordData
              DWA_pSR_HudWarningStatus_HudWarningStatusData: accessed-variable=pSR_HudWarningStatus.HudWarningStatusData
              DSP_pSR_MainHMIReadyStatus_MainHMIReadyStatusData: accessed-variable=pSR_MainHMIReadyStatus.MainHMIReadyStatusData
              DSP_pSR_PowerExtendShutdownTime_PowerExtendShutdownTimeData: accessed-variable=pSR_PowerExtendShutdownTime.PowerExtendShutdownTimeData
              DSP_pSR_PowerKeepSystemAwake_PowerKeepSystemAwakeData: accessed-variable=pSR_PowerKeepSystemAwake.PowerKeepSystemAwakeData
              DWA_pSR_PowerSystemState_PowerSystemStateData: accessed-variable=pSR_PowerSystemState.PowerSystemStateData
              DSP_pSR_SafeHMIReadyStatus_SafeHMIReadyStatusData: accessed-variable=pSR_SafeHMIReadyStatus.SafeHMIReadyStatusData
              DSP_pSR_UpdateShortServiceResp_UpdateShortServiceRespData: accessed-variable=pSR_UpdateShortServiceResp.UpdateShortServiceRespData
              DWA_pSR_WarningDisplayAvailable_WarningDisplayAvailableData: accessed-variable=pSR_WarningDisplayAvailable.WarningDisplayAvailableData
              DWA_pSR_WarningStatus_WarningStatusData: accessed-variable=pSR_WarningStatus.WarningStatusData
          sync call OA_rCS_UclSystemCallbacks_ErrorNotification: operation=rCS_UclSystemCallbacks.ErrorNotification, timeout=0.0
          sync call OA_rCS_UclSystemCallbacks_LinkStatusChanged: operation=rCS_UclSystemCallbacks.LinkStatusChanged, timeout=0.0
        OnDre_FRTT_Status
          data-receive-point-by-arguments:
            25 x access:
              DRA_rSR_DLTControlMessageReponse_DLTControlMessageReponseData: accessed-variable=rSR_DLTControlMessageReponse.DLTControlMessageReponseData
              DRA_rSR_DLTMessageReadRequest_DLTMessageReadRequestData: accessed-variable=rSR_DLTMessageReadRequest.DLTMessageReadRequestData
              DRP_rSR_DiagDIDRequest_DiagDIDRequestData: accessed-variable=rSR_DiagDIDRequest.DiagDIDRequestData
              DRP_rSR_DiagIOCtrlRequest_DiagIOCtrlRequestData: accessed-variable=rSR_DiagIOCtrlRequest.DiagIOCtrlRequestData
              DRP_rSR_DiagRoutineRequest_DiagRoutineRequestData: accessed-variable=rSR_DiagRoutineRequest.DiagRoutineRequestData
              DRA_rSR_DisplaySetPower_DisplaySetPowerData: accessed-variable=rSR_DisplaySetPower.DisplaySetPowerData
              DRA_rSR_FRTT_Status_FRTT_StatusData: accessed-variable=rSR_FRTT_Status.FRTT_StatusData
              DRA_rSR_FastGaugeInfo_FastGaugeInfoData: accessed-variable=rSR_FastGaugeInfo.FastGaugeInfoData
              DRP_rSR_HealthDumpGetData_HealthDumpGetDataData: accessed-variable=rSR_HealthDumpGetData.HealthDumpGetDataData
              DRP_rSR_HealthDumpGetHdr_HealthDumpGetHdrData: accessed-variable=rSR_HealthDumpGetHdr.HealthDumpGetHdrData
              DRA_rSR_HudWarningDisplay_HudWarningDisplayData: accessed-variable=rSR_HudWarningDisplay.HudWarningDisplayData
              DRP_rSR_IgnState_IgnStateData: accessed-variable=rSR_IgnState.IgnStateData
              DRA_rSR_IlluminationData_IlluminationDataData: accessed-variable=rSR_IlluminationData.IlluminationDataData
              DRA_rSR_PowerSystemStateReqChange_PowerSystemStateReqChangeData: accessed-variable=rSR_PowerSystemStateReqChange.PowerSystemStateReqChangeData
              DRA_rSR_RTT_Icon_RTT_IconData: accessed-variable=rSR_RTT_Icon.RTT_IconData
              DRA_rSR_RTT_Status_RTT_StatusData: accessed-variable=rSR_RTT_Status.RTT_StatusData
              DRA_rSR_RTT_Toggle_RTT_ToggleData: accessed-variable=rSR_RTT_Toggle.RTT_ToggleData
              DRA_rSR_ShiftPosIndStatus_ShiftPosIndStatusData: accessed-variable=rSR_ShiftPosIndStatus.ShiftPosIndStatusData
              DRA_rSR_SlowGaugeInfo_SlowGaugeInfoData: accessed-variable=rSR_SlowGaugeInfo.SlowGaugeInfoData
              DRA_rSR_TT_Status_TT_StatusData: accessed-variable=rSR_TT_Status.TT_StatusData
              DRA_rSR_TpmsWarningData_TpmsWarningDataData: accessed-variable=rSR_TpmsWarningData.TpmsWarningDataData
              DRP_rSR_UpdateLongServiceReq_UpdateLongServiceReqData: accessed-variable=rSR_UpdateLongServiceReq.UpdateLongServiceReqData
              DRP_rSR_UpdateShortServiceReq_UpdateShortServiceReqData: accessed-variable=rSR_UpdateShortServiceReq.UpdateShortServiceReqData
              DRA_rSR_WarningDisplay_WarningDisplayData: accessed-variable=rSR_WarningDisplay.WarningDisplayData
              DRA_rSR_WarningExtDisplay_WarningExtDisplayData: accessed-variable=rSR_WarningExtDisplay.WarningExtDisplayData
          data-send-points:
            19 x access:
              DWA_pSR_DLTControlMessageRequest_DLTControlMessageRequestData: accessed-variable=pSR_DLTControlMessageRequest.DLTControlMessageRequestData
              DWA_pSR_DLTMessageReadAck_DLTMessageReadAckData: accessed-variable=pSR_DLTMessageReadAck.DLTMessageReadAckData
              DSP_pSR_DiagResponse_DiagResponseData: accessed-variable=pSR_DiagResponse.DiagResponseData
              DWA_pSR_DisplayCurrentState_DisplayCurrentStateData: accessed-variable=pSR_DisplayCurrentState.DisplayCurrentStateData
              DWA_pSR_EmmcErrorNotifier_EmmcErrorNotifierData: accessed-variable=pSR_EmmcErrorNotifier.EmmcErrorNotifierData
              DSP_pSR_HealthDomainFatalError_HealthDomainFatalErrorData: accessed-variable=pSR_HealthDomainFatalError.HealthDomainFatalErrorData
              DSP_pSR_HealthDomainHeartbeat_HealthDomainHeartbeatData: accessed-variable=pSR_HealthDomainHeartbeat.HealthDomainHeartbeatData
              DSP_pSR_HealthDumpData_HealthDumpDataData: accessed-variable=pSR_HealthDumpData.HealthDumpDataData
              DSP_pSR_HealthDumpHdrInfo_HealthDumpHdrInfoData: accessed-variable=pSR_HealthDumpHdrInfo.HealthDumpHdrInfoData
              DSP_pSR_HealthEventRecord_HealthEventRecordData: accessed-variable=pSR_HealthEventRecord.HealthEventRecordData
              DWA_pSR_HudWarningStatus_HudWarningStatusData: accessed-variable=pSR_HudWarningStatus.HudWarningStatusData
              DSP_pSR_MainHMIReadyStatus_MainHMIReadyStatusData: accessed-variable=pSR_MainHMIReadyStatus.MainHMIReadyStatusData
              DSP_pSR_PowerExtendShutdownTime_PowerExtendShutdownTimeData: accessed-variable=pSR_PowerExtendShutdownTime.PowerExtendShutdownTimeData
              DSP_pSR_PowerKeepSystemAwake_PowerKeepSystemAwakeData: accessed-variable=pSR_PowerKeepSystemAwake.PowerKeepSystemAwakeData
              DWA_pSR_PowerSystemState_PowerSystemStateData: accessed-variable=pSR_PowerSystemState.PowerSystemStateData
              DSP_pSR_SafeHMIReadyStatus_SafeHMIReadyStatusData: accessed-variable=pSR_SafeHMIReadyStatus.SafeHMIReadyStatusData
              DSP_pSR_UpdateShortServiceResp_UpdateShortServiceRespData: accessed-variable=pSR_UpdateShortServiceResp.UpdateShortServiceRespData
              DWA_pSR_WarningDisplayAvailable_WarningDisplayAvailableData: accessed-variable=pSR_WarningDisplayAvailable.WarningDisplayAvailableData
              DWA_pSR_WarningStatus_WarningStatusData: accessed-variable=pSR_WarningStatus.WarningStatusData
          sync call OA_rCS_UclSystemCallbacks_ErrorNotification: operation=rCS_UclSystemCallbacks.ErrorNotification, timeout=0.0
          sync call OA_rCS_UclSystemCallbacks_LinkStatusChanged: operation=rCS_UclSystemCallbacks.LinkStatusChanged, timeout=0.0
        OnDre_FastGaugeInfo
          data-receive-point-by-arguments:
            25 x access:
              DRA_rSR_DLTControlMessageReponse_DLTControlMessageReponseData: accessed-variable=rSR_DLTControlMessageReponse.DLTControlMessageReponseData
              DRA_rSR_DLTMessageReadRequest_DLTMessageReadRequestData: accessed-variable=rSR_DLTMessageReadRequest.DLTMessageReadRequestData
              DRP_rSR_DiagDIDRequest_DiagDIDRequestData: accessed-variable=rSR_DiagDIDRequest.DiagDIDRequestData
              DRP_rSR_DiagIOCtrlRequest_DiagIOCtrlRequestData: accessed-variable=rSR_DiagIOCtrlRequest.DiagIOCtrlRequestData
              DRP_rSR_DiagRoutineRequest_DiagRoutineRequestData: accessed-variable=rSR_DiagRoutineRequest.DiagRoutineRequestData
              DRA_rSR_DisplaySetPower_DisplaySetPowerData: accessed-variable=rSR_DisplaySetPower.DisplaySetPowerData
              DRA_rSR_FRTT_Status_FRTT_StatusData: accessed-variable=rSR_FRTT_Status.FRTT_StatusData
              DRA_rSR_FastGaugeInfo_FastGaugeInfoData: accessed-variable=rSR_FastGaugeInfo.FastGaugeInfoData
              DRP_rSR_HealthDumpGetData_HealthDumpGetDataData: accessed-variable=rSR_HealthDumpGetData.HealthDumpGetDataData
              DRP_rSR_HealthDumpGetHdr_HealthDumpGetHdrData: accessed-variable=rSR_HealthDumpGetHdr.HealthDumpGetHdrData
              DRA_rSR_HudWarningDisplay_HudWarningDisplayData: accessed-variable=rSR_HudWarningDisplay.HudWarningDisplayData
              DRP_rSR_IgnState_IgnStateData: accessed-variable=rSR_IgnState.IgnStateData
              DRA_rSR_IlluminationData_IlluminationDataData: accessed-variable=rSR_IlluminationData.IlluminationDataData
              DRA_rSR_PowerSystemStateReqChange_PowerSystemStateReqChangeData: accessed-variable=rSR_PowerSystemStateReqChange.PowerSystemStateReqChangeData
              DRA_rSR_RTT_Icon_RTT_IconData: accessed-variable=rSR_RTT_Icon.RTT_IconData
              DRA_rSR_RTT_Status_RTT_StatusData: accessed-variable=rSR_RTT_Status.RTT_StatusData
              DRA_rSR_RTT_Toggle_RTT_ToggleData: accessed-variable=rSR_RTT_Toggle.RTT_ToggleData
              DRA_rSR_ShiftPosIndStatus_ShiftPosIndStatusData: accessed-variable=rSR_ShiftPosIndStatus.ShiftPosIndStatusData
              DRA_rSR_SlowGaugeInfo_SlowGaugeInfoData: accessed-variable=rSR_SlowGaugeInfo.SlowGaugeInfoData
              DRA_rSR_TT_Status_TT_StatusData: accessed-variable=rSR_TT_Status.TT_StatusData
              DRA_rSR_TpmsWarningData_TpmsWarningDataData: accessed-variable=rSR_TpmsWarningData.TpmsWarningDataData
              DRP_rSR_UpdateLongServiceReq_UpdateLongServiceReqData: accessed-variable=rSR_UpdateLongServiceReq.UpdateLongServiceReqData
              DRP_rSR_UpdateShortServiceReq_UpdateShortServiceReqData: accessed-variable=rSR_UpdateShortServiceReq.UpdateShortServiceReqData
              DRA_rSR_WarningDisplay_WarningDisplayData: accessed-variable=rSR_WarningDisplay.WarningDisplayData
              DRA_rSR_WarningExtDisplay_WarningExtDisplayData: accessed-variable=rSR_WarningExtDisplay.WarningExtDisplayData
          data-send-points:
            19 x access:
              DWA_pSR_DLTControlMessageRequest_DLTControlMessageRequestData: accessed-variable=pSR_DLTControlMessageRequest.DLTControlMessageRequestData
              DWA_pSR_DLTMessageReadAck_DLTMessageReadAckData: accessed-variable=pSR_DLTMessageReadAck.DLTMessageReadAckData
              DSP_pSR_DiagResponse_DiagResponseData: accessed-variable=pSR_DiagResponse.DiagResponseData
              DWA_pSR_DisplayCurrentState_DisplayCurrentStateData: accessed-variable=pSR_DisplayCurrentState.DisplayCurrentStateData
              DWA_pSR_EmmcErrorNotifier_EmmcErrorNotifierData: accessed-variable=pSR_EmmcErrorNotifier.EmmcErrorNotifierData
              DSP_pSR_HealthDomainFatalError_HealthDomainFatalErrorData: accessed-variable=pSR_HealthDomainFatalError.HealthDomainFatalErrorData
              DSP_pSR_HealthDomainHeartbeat_HealthDomainHeartbeatData: accessed-variable=pSR_HealthDomainHeartbeat.HealthDomainHeartbeatData
              DSP_pSR_HealthDumpData_HealthDumpDataData: accessed-variable=pSR_HealthDumpData.HealthDumpDataData
              DSP_pSR_HealthDumpHdrInfo_HealthDumpHdrInfoData: accessed-variable=pSR_HealthDumpHdrInfo.HealthDumpHdrInfoData
              DSP_pSR_HealthEventRecord_HealthEventRecordData: accessed-variable=pSR_HealthEventRecord.HealthEventRecordData
              DWA_pSR_HudWarningStatus_HudWarningStatusData: accessed-variable=pSR_HudWarningStatus.HudWarningStatusData
              DSP_pSR_MainHMIReadyStatus_MainHMIReadyStatusData: accessed-variable=pSR_MainHMIReadyStatus.MainHMIReadyStatusData
              DSP_pSR_PowerExtendShutdownTime_PowerExtendShutdownTimeData: accessed-variable=pSR_PowerExtendShutdownTime.PowerExtendShutdownTimeData
              DSP_pSR_PowerKeepSystemAwake_PowerKeepSystemAwakeData: accessed-variable=pSR_PowerKeepSystemAwake.PowerKeepSystemAwakeData
              DWA_pSR_PowerSystemState_PowerSystemStateData: accessed-variable=pSR_PowerSystemState.PowerSystemStateData
              DSP_pSR_SafeHMIReadyStatus_SafeHMIReadyStatusData: accessed-variable=pSR_SafeHMIReadyStatus.SafeHMIReadyStatusData
              DSP_pSR_UpdateShortServiceResp_UpdateShortServiceRespData: accessed-variable=pSR_UpdateShortServiceResp.UpdateShortServiceRespData
              DWA_pSR_WarningDisplayAvailable_WarningDisplayAvailableData: accessed-variable=pSR_WarningDisplayAvailable.WarningDisplayAvailableData
              DWA_pSR_WarningStatus_WarningStatusData: accessed-variable=pSR_WarningStatus.WarningStatusData
          sync call OA_rCS_UclSystemCallbacks_ErrorNotification: operation=rCS_UclSystemCallbacks.ErrorNotification, timeout=0.0
          sync call OA_rCS_UclSystemCallbacks_LinkStatusChanged: operation=rCS_UclSystemCallbacks.LinkStatusChanged, timeout=0.0
        OnDre_HealthDumpGetData
          data-receive-point-by-arguments:
            25 x access:
              DRA_rSR_DLTControlMessageReponse_DLTControlMessageReponseData: accessed-variable=rSR_DLTControlMessageReponse.DLTControlMessageReponseData
              DRA_rSR_DLTMessageReadRequest_DLTMessageReadRequestData: accessed-variable=rSR_DLTMessageReadRequest.DLTMessageReadRequestData
              DRP_rSR_DiagDIDRequest_DiagDIDRequestData: accessed-variable=rSR_DiagDIDRequest.DiagDIDRequestData
              DRP_rSR_DiagIOCtrlRequest_DiagIOCtrlRequestData: accessed-variable=rSR_DiagIOCtrlRequest.DiagIOCtrlRequestData
              DRP_rSR_DiagRoutineRequest_DiagRoutineRequestData: accessed-variable=rSR_DiagRoutineRequest.DiagRoutineRequestData
              DRA_rSR_DisplaySetPower_DisplaySetPowerData: accessed-variable=rSR_DisplaySetPower.DisplaySetPowerData
              DRA_rSR_FRTT_Status_FRTT_StatusData: accessed-variable=rSR_FRTT_Status.FRTT_StatusData
              DRA_rSR_FastGaugeInfo_FastGaugeInfoData: accessed-variable=rSR_FastGaugeInfo.FastGaugeInfoData
              DRP_rSR_HealthDumpGetData_HealthDumpGetDataData: accessed-variable=rSR_HealthDumpGetData.HealthDumpGetDataData
              DRP_rSR_HealthDumpGetHdr_HealthDumpGetHdrData: accessed-variable=rSR_HealthDumpGetHdr.HealthDumpGetHdrData
              DRA_rSR_HudWarningDisplay_HudWarningDisplayData: accessed-variable=rSR_HudWarningDisplay.HudWarningDisplayData
              DRP_rSR_IgnState_IgnStateData: accessed-variable=rSR_IgnState.IgnStateData
              DRA_rSR_IlluminationData_IlluminationDataData: accessed-variable=rSR_IlluminationData.IlluminationDataData
              DRA_rSR_PowerSystemStateReqChange_PowerSystemStateReqChangeData: accessed-variable=rSR_PowerSystemStateReqChange.PowerSystemStateReqChangeData
              DRA_rSR_RTT_Icon_RTT_IconData: accessed-variable=rSR_RTT_Icon.RTT_IconData
              DRA_rSR_RTT_Status_RTT_StatusData: accessed-variable=rSR_RTT_Status.RTT_StatusData
              DRA_rSR_RTT_Toggle_RTT_ToggleData: accessed-variable=rSR_RTT_Toggle.RTT_ToggleData
              DRA_rSR_ShiftPosIndStatus_ShiftPosIndStatusData: accessed-variable=rSR_ShiftPosIndStatus.ShiftPosIndStatusData
              DRA_rSR_SlowGaugeInfo_SlowGaugeInfoData: accessed-variable=rSR_SlowGaugeInfo.SlowGaugeInfoData
              DRA_rSR_TT_Status_TT_StatusData: accessed-variable=rSR_TT_Status.TT_StatusData
              DRA_rSR_TpmsWarningData_TpmsWarningDataData: accessed-variable=rSR_TpmsWarningData.TpmsWarningDataData
              DRP_rSR_UpdateLongServiceReq_UpdateLongServiceReqData: accessed-variable=rSR_UpdateLongServiceReq.UpdateLongServiceReqData
              DRP_rSR_UpdateShortServiceReq_UpdateShortServiceReqData: accessed-variable=rSR_UpdateShortServiceReq.UpdateShortServiceReqData
              DRA_rSR_WarningDisplay_WarningDisplayData: accessed-variable=rSR_WarningDisplay.WarningDisplayData
              DRA_rSR_WarningExtDisplay_WarningExtDisplayData: accessed-variable=rSR_WarningExtDisplay.WarningExtDisplayData
          data-send-points:
            19 x access:
              DWA_pSR_DLTControlMessageRequest_DLTControlMessageRequestData: accessed-variable=pSR_DLTControlMessageRequest.DLTControlMessageRequestData
              DWA_pSR_DLTMessageReadAck_DLTMessageReadAckData: accessed-variable=pSR_DLTMessageReadAck.DLTMessageReadAckData
              DSP_pSR_DiagResponse_DiagResponseData: accessed-variable=pSR_DiagResponse.DiagResponseData
              DWA_pSR_DisplayCurrentState_DisplayCurrentStateData: accessed-variable=pSR_DisplayCurrentState.DisplayCurrentStateData
              DWA_pSR_EmmcErrorNotifier_EmmcErrorNotifierData: accessed-variable=pSR_EmmcErrorNotifier.EmmcErrorNotifierData
              DSP_pSR_HealthDomainFatalError_HealthDomainFatalErrorData: accessed-variable=pSR_HealthDomainFatalError.HealthDomainFatalErrorData
              DSP_pSR_HealthDomainHeartbeat_HealthDomainHeartbeatData: accessed-variable=pSR_HealthDomainHeartbeat.HealthDomainHeartbeatData
              DSP_pSR_HealthDumpData_HealthDumpDataData: accessed-variable=pSR_HealthDumpData.HealthDumpDataData
              DSP_pSR_HealthDumpHdrInfo_HealthDumpHdrInfoData: accessed-variable=pSR_HealthDumpHdrInfo.HealthDumpHdrInfoData
              DSP_pSR_HealthEventRecord_HealthEventRecordData: accessed-variable=pSR_HealthEventRecord.HealthEventRecordData
              DWA_pSR_HudWarningStatus_HudWarningStatusData: accessed-variable=pSR_HudWarningStatus.HudWarningStatusData
              DSP_pSR_MainHMIReadyStatus_MainHMIReadyStatusData: accessed-variable=pSR_MainHMIReadyStatus.MainHMIReadyStatusData
              DSP_pSR_PowerExtendShutdownTime_PowerExtendShutdownTimeData: accessed-variable=pSR_PowerExtendShutdownTime.PowerExtendShutdownTimeData
              DSP_pSR_PowerKeepSystemAwake_PowerKeepSystemAwakeData: accessed-variable=pSR_PowerKeepSystemAwake.PowerKeepSystemAwakeData
              DWA_pSR_PowerSystemState_PowerSystemStateData: accessed-variable=pSR_PowerSystemState.PowerSystemStateData
              DSP_pSR_SafeHMIReadyStatus_SafeHMIReadyStatusData: accessed-variable=pSR_SafeHMIReadyStatus.SafeHMIReadyStatusData
              DSP_pSR_UpdateShortServiceResp_UpdateShortServiceRespData: accessed-variable=pSR_UpdateShortServiceResp.UpdateShortServiceRespData
              DWA_pSR_WarningDisplayAvailable_WarningDisplayAvailableData: accessed-variable=pSR_WarningDisplayAvailable.WarningDisplayAvailableData
              DWA_pSR_WarningStatus_WarningStatusData: accessed-variable=pSR_WarningStatus.WarningStatusData
          sync call OA_rCS_UclSystemCallbacks_ErrorNotification: operation=rCS_UclSystemCallbacks.ErrorNotification, timeout=0.0
          sync call OA_rCS_UclSystemCallbacks_LinkStatusChanged: operation=rCS_UclSystemCallbacks.LinkStatusChanged, timeout=0.0
        OnDre_HealthDumpGetHdr
          data-receive-point-by-arguments:
            25 x access:
              DRA_rSR_DLTControlMessageReponse_DLTControlMessageReponseData: accessed-variable=rSR_DLTControlMessageReponse.DLTControlMessageReponseData
              DRA_rSR_DLTMessageReadRequest_DLTMessageReadRequestData: accessed-variable=rSR_DLTMessageReadRequest.DLTMessageReadRequestData
              DRP_rSR_DiagDIDRequest_DiagDIDRequestData: accessed-variable=rSR_DiagDIDRequest.DiagDIDRequestData
              DRP_rSR_DiagIOCtrlRequest_DiagIOCtrlRequestData: accessed-variable=rSR_DiagIOCtrlRequest.DiagIOCtrlRequestData
              DRP_rSR_DiagRoutineRequest_DiagRoutineRequestData: accessed-variable=rSR_DiagRoutineRequest.DiagRoutineRequestData
              DRA_rSR_DisplaySetPower_DisplaySetPowerData: accessed-variable=rSR_DisplaySetPower.DisplaySetPowerData
              DRA_rSR_FRTT_Status_FRTT_StatusData: accessed-variable=rSR_FRTT_Status.FRTT_StatusData
              DRA_rSR_FastGaugeInfo_FastGaugeInfoData: accessed-variable=rSR_FastGaugeInfo.FastGaugeInfoData
              DRP_rSR_HealthDumpGetData_HealthDumpGetDataData: accessed-variable=rSR_HealthDumpGetData.HealthDumpGetDataData
              DRP_rSR_HealthDumpGetHdr_HealthDumpGetHdrData: accessed-variable=rSR_HealthDumpGetHdr.HealthDumpGetHdrData
              DRA_rSR_HudWarningDisplay_HudWarningDisplayData: accessed-variable=rSR_HudWarningDisplay.HudWarningDisplayData
              DRP_rSR_IgnState_IgnStateData: accessed-variable=rSR_IgnState.IgnStateData
              DRA_rSR_IlluminationData_IlluminationDataData: accessed-variable=rSR_IlluminationData.IlluminationDataData
              DRA_rSR_PowerSystemStateReqChange_PowerSystemStateReqChangeData: accessed-variable=rSR_PowerSystemStateReqChange.PowerSystemStateReqChangeData
              DRA_rSR_RTT_Icon_RTT_IconData: accessed-variable=rSR_RTT_Icon.RTT_IconData
              DRA_rSR_RTT_Status_RTT_StatusData: accessed-variable=rSR_RTT_Status.RTT_StatusData
              DRA_rSR_RTT_Toggle_RTT_ToggleData: accessed-variable=rSR_RTT_Toggle.RTT_ToggleData
              DRA_rSR_ShiftPosIndStatus_ShiftPosIndStatusData: accessed-variable=rSR_ShiftPosIndStatus.ShiftPosIndStatusData
              DRA_rSR_SlowGaugeInfo_SlowGaugeInfoData: accessed-variable=rSR_SlowGaugeInfo.SlowGaugeInfoData
              DRA_rSR_TT_Status_TT_StatusData: accessed-variable=rSR_TT_Status.TT_StatusData
              DRA_rSR_TpmsWarningData_TpmsWarningDataData: accessed-variable=rSR_TpmsWarningData.TpmsWarningDataData
              DRP_rSR_UpdateLongServiceReq_UpdateLongServiceReqData: accessed-variable=rSR_UpdateLongServiceReq.UpdateLongServiceReqData
              DRP_rSR_UpdateShortServiceReq_UpdateShortServiceReqData: accessed-variable=rSR_UpdateShortServiceReq.UpdateShortServiceReqData
              DRA_rSR_WarningDisplay_WarningDisplayData: accessed-variable=rSR_WarningDisplay.WarningDisplayData
              DRA_rSR_WarningExtDisplay_WarningExtDisplayData: accessed-variable=rSR_WarningExtDisplay.WarningExtDisplayData
          data-send-points:
            19 x access:
              DWA_pSR_DLTControlMessageRequest_DLTControlMessageRequestData: accessed-variable=pSR_DLTControlMessageRequest.DLTControlMessageRequestData
              DWA_pSR_DLTMessageReadAck_DLTMessageReadAckData: accessed-variable=pSR_DLTMessageReadAck.DLTMessageReadAckData
              DSP_pSR_DiagResponse_DiagResponseData: accessed-variable=pSR_DiagResponse.DiagResponseData
              DWA_pSR_DisplayCurrentState_DisplayCurrentStateData: accessed-variable=pSR_DisplayCurrentState.DisplayCurrentStateData
              DWA_pSR_EmmcErrorNotifier_EmmcErrorNotifierData: accessed-variable=pSR_EmmcErrorNotifier.EmmcErrorNotifierData
              DSP_pSR_HealthDomainFatalError_HealthDomainFatalErrorData: accessed-variable=pSR_HealthDomainFatalError.HealthDomainFatalErrorData
              DSP_pSR_HealthDomainHeartbeat_HealthDomainHeartbeatData: accessed-variable=pSR_HealthDomainHeartbeat.HealthDomainHeartbeatData
              DSP_pSR_HealthDumpData_HealthDumpDataData: accessed-variable=pSR_HealthDumpData.HealthDumpDataData
              DSP_pSR_HealthDumpHdrInfo_HealthDumpHdrInfoData: accessed-variable=pSR_HealthDumpHdrInfo.HealthDumpHdrInfoData
              DSP_pSR_HealthEventRecord_HealthEventRecordData: accessed-variable=pSR_HealthEventRecord.HealthEventRecordData
              DWA_pSR_HudWarningStatus_HudWarningStatusData: accessed-variable=pSR_HudWarningStatus.HudWarningStatusData
              DSP_pSR_MainHMIReadyStatus_MainHMIReadyStatusData: accessed-variable=pSR_MainHMIReadyStatus.MainHMIReadyStatusData
              DSP_pSR_PowerExtendShutdownTime_PowerExtendShutdownTimeData: accessed-variable=pSR_PowerExtendShutdownTime.PowerExtendShutdownTimeData
              DSP_pSR_PowerKeepSystemAwake_PowerKeepSystemAwakeData: accessed-variable=pSR_PowerKeepSystemAwake.PowerKeepSystemAwakeData
              DWA_pSR_PowerSystemState_PowerSystemStateData: accessed-variable=pSR_PowerSystemState.PowerSystemStateData
              DSP_pSR_SafeHMIReadyStatus_SafeHMIReadyStatusData: accessed-variable=pSR_SafeHMIReadyStatus.SafeHMIReadyStatusData
              DSP_pSR_UpdateShortServiceResp_UpdateShortServiceRespData: accessed-variable=pSR_UpdateShortServiceResp.UpdateShortServiceRespData
              DWA_pSR_WarningDisplayAvailable_WarningDisplayAvailableData: accessed-variable=pSR_WarningDisplayAvailable.WarningDisplayAvailableData
              DWA_pSR_WarningStatus_WarningStatusData: accessed-variable=pSR_WarningStatus.WarningStatusData
          sync call OA_rCS_UclSystemCallbacks_ErrorNotification: operation=rCS_UclSystemCallbacks.ErrorNotification, timeout=0.0
          sync call OA_rCS_UclSystemCallbacks_LinkStatusChanged: operation=rCS_UclSystemCallbacks.LinkStatusChanged, timeout=0.0
        OnDre_IlluminationData
          data-receive-point-by-arguments:
            25 x access:
              DRA_rSR_DLTControlMessageReponse_DLTControlMessageReponseData: accessed-variable=rSR_DLTControlMessageReponse.DLTControlMessageReponseData
              DRA_rSR_DLTMessageReadRequest_DLTMessageReadRequestData: accessed-variable=rSR_DLTMessageReadRequest.DLTMessageReadRequestData
              DRP_rSR_DiagDIDRequest_DiagDIDRequestData: accessed-variable=rSR_DiagDIDRequest.DiagDIDRequestData
              DRP_rSR_DiagIOCtrlRequest_DiagIOCtrlRequestData: accessed-variable=rSR_DiagIOCtrlRequest.DiagIOCtrlRequestData
              DRP_rSR_DiagRoutineRequest_DiagRoutineRequestData: accessed-variable=rSR_DiagRoutineRequest.DiagRoutineRequestData
              DRA_rSR_DisplaySetPower_DisplaySetPowerData: accessed-variable=rSR_DisplaySetPower.DisplaySetPowerData
              DRA_rSR_FRTT_Status_FRTT_StatusData: accessed-variable=rSR_FRTT_Status.FRTT_StatusData
              DRA_rSR_FastGaugeInfo_FastGaugeInfoData: accessed-variable=rSR_FastGaugeInfo.FastGaugeInfoData
              DRP_rSR_HealthDumpGetData_HealthDumpGetDataData: accessed-variable=rSR_HealthDumpGetData.HealthDumpGetDataData
              DRP_rSR_HealthDumpGetHdr_HealthDumpGetHdrData: accessed-variable=rSR_HealthDumpGetHdr.HealthDumpGetHdrData
              DRA_rSR_HudWarningDisplay_HudWarningDisplayData: accessed-variable=rSR_HudWarningDisplay.HudWarningDisplayData
              DRP_rSR_IgnState_IgnStateData: accessed-variable=rSR_IgnState.IgnStateData
              DRA_rSR_IlluminationData_IlluminationDataData: accessed-variable=rSR_IlluminationData.IlluminationDataData
              DRA_rSR_PowerSystemStateReqChange_PowerSystemStateReqChangeData: accessed-variable=rSR_PowerSystemStateReqChange.PowerSystemStateReqChangeData
              DRA_rSR_RTT_Icon_RTT_IconData: accessed-variable=rSR_RTT_Icon.RTT_IconData
              DRA_rSR_RTT_Status_RTT_StatusData: accessed-variable=rSR_RTT_Status.RTT_StatusData
              DRA_rSR_RTT_Toggle_RTT_ToggleData: accessed-variable=rSR_RTT_Toggle.RTT_ToggleData
              DRA_rSR_ShiftPosIndStatus_ShiftPosIndStatusData: accessed-variable=rSR_ShiftPosIndStatus.ShiftPosIndStatusData
              DRA_rSR_SlowGaugeInfo_SlowGaugeInfoData: accessed-variable=rSR_SlowGaugeInfo.SlowGaugeInfoData
              DRA_rSR_TT_Status_TT_StatusData: accessed-variable=rSR_TT_Status.TT_StatusData
              DRA_rSR_TpmsWarningData_TpmsWarningDataData: accessed-variable=rSR_TpmsWarningData.TpmsWarningDataData
              DRP_rSR_UpdateLongServiceReq_UpdateLongServiceReqData: accessed-variable=rSR_UpdateLongServiceReq.UpdateLongServiceReqData
              DRP_rSR_UpdateShortServiceReq_UpdateShortServiceReqData: accessed-variable=rSR_UpdateShortServiceReq.UpdateShortServiceReqData
              DRA_rSR_WarningDisplay_WarningDisplayData: accessed-variable=rSR_WarningDisplay.WarningDisplayData
              DRA_rSR_WarningExtDisplay_WarningExtDisplayData: accessed-variable=rSR_WarningExtDisplay.WarningExtDisplayData
          data-send-points:
            19 x access:
              DWA_pSR_DLTControlMessageRequest_DLTControlMessageRequestData: accessed-variable=pSR_DLTControlMessageRequest.DLTControlMessageRequestData
              DWA_pSR_DLTMessageReadAck_DLTMessageReadAckData: accessed-variable=pSR_DLTMessageReadAck.DLTMessageReadAckData
              DSP_pSR_DiagResponse_DiagResponseData: accessed-variable=pSR_DiagResponse.DiagResponseData
              DWA_pSR_DisplayCurrentState_DisplayCurrentStateData: accessed-variable=pSR_DisplayCurrentState.DisplayCurrentStateData
              DWA_pSR_EmmcErrorNotifier_EmmcErrorNotifierData: accessed-variable=pSR_EmmcErrorNotifier.EmmcErrorNotifierData
              DSP_pSR_HealthDomainFatalError_HealthDomainFatalErrorData: accessed-variable=pSR_HealthDomainFatalError.HealthDomainFatalErrorData
              DSP_pSR_HealthDomainHeartbeat_HealthDomainHeartbeatData: accessed-variable=pSR_HealthDomainHeartbeat.HealthDomainHeartbeatData
              DSP_pSR_HealthDumpData_HealthDumpDataData: accessed-variable=pSR_HealthDumpData.HealthDumpDataData
              DSP_pSR_HealthDumpHdrInfo_HealthDumpHdrInfoData: accessed-variable=pSR_HealthDumpHdrInfo.HealthDumpHdrInfoData
              DSP_pSR_HealthEventRecord_HealthEventRecordData: accessed-variable=pSR_HealthEventRecord.HealthEventRecordData
              DWA_pSR_HudWarningStatus_HudWarningStatusData: accessed-variable=pSR_HudWarningStatus.HudWarningStatusData
              DSP_pSR_MainHMIReadyStatus_MainHMIReadyStatusData: accessed-variable=pSR_MainHMIReadyStatus.MainHMIReadyStatusData
              DSP_pSR_PowerExtendShutdownTime_PowerExtendShutdownTimeData: accessed-variable=pSR_PowerExtendShutdownTime.PowerExtendShutdownTimeData
              DSP_pSR_PowerKeepSystemAwake_PowerKeepSystemAwakeData: accessed-variable=pSR_PowerKeepSystemAwake.PowerKeepSystemAwakeData
              DWA_pSR_PowerSystemState_PowerSystemStateData: accessed-variable=pSR_PowerSystemState.PowerSystemStateData
              DSP_pSR_SafeHMIReadyStatus_SafeHMIReadyStatusData: accessed-variable=pSR_SafeHMIReadyStatus.SafeHMIReadyStatusData
              DSP_pSR_UpdateShortServiceResp_UpdateShortServiceRespData: accessed-variable=pSR_UpdateShortServiceResp.UpdateShortServiceRespData
              DWA_pSR_WarningDisplayAvailable_WarningDisplayAvailableData: accessed-variable=pSR_WarningDisplayAvailable.WarningDisplayAvailableData
              DWA_pSR_WarningStatus_WarningStatusData: accessed-variable=pSR_WarningStatus.WarningStatusData
          sync call OA_rCS_UclSystemCallbacks_ErrorNotification: operation=rCS_UclSystemCallbacks.ErrorNotification, timeout=0.0
          sync call OA_rCS_UclSystemCallbacks_LinkStatusChanged: operation=rCS_UclSystemCallbacks.LinkStatusChanged, timeout=0.0
        OnDre_PowerSystemStateReqChange
          data-receive-point-by-arguments:
            25 x access:
              DRA_rSR_DLTControlMessageReponse_DLTControlMessageReponseData: accessed-variable=rSR_DLTControlMessageReponse.DLTControlMessageReponseData
              DRA_rSR_DLTMessageReadRequest_DLTMessageReadRequestData: accessed-variable=rSR_DLTMessageReadRequest.DLTMessageReadRequestData
              DRP_rSR_DiagDIDRequest_DiagDIDRequestData: accessed-variable=rSR_DiagDIDRequest.DiagDIDRequestData
              DRP_rSR_DiagIOCtrlRequest_DiagIOCtrlRequestData: accessed-variable=rSR_DiagIOCtrlRequest.DiagIOCtrlRequestData
              DRP_rSR_DiagRoutineRequest_DiagRoutineRequestData: accessed-variable=rSR_DiagRoutineRequest.DiagRoutineRequestData
              DRA_rSR_DisplaySetPower_DisplaySetPowerData: accessed-variable=rSR_DisplaySetPower.DisplaySetPowerData
              DRA_rSR_FRTT_Status_FRTT_StatusData: accessed-variable=rSR_FRTT_Status.FRTT_StatusData
              DRA_rSR_FastGaugeInfo_FastGaugeInfoData: accessed-variable=rSR_FastGaugeInfo.FastGaugeInfoData
              DRP_rSR_HealthDumpGetData_HealthDumpGetDataData: accessed-variable=rSR_HealthDumpGetData.HealthDumpGetDataData
              DRP_rSR_HealthDumpGetHdr_HealthDumpGetHdrData: accessed-variable=rSR_HealthDumpGetHdr.HealthDumpGetHdrData
              DRA_rSR_HudWarningDisplay_HudWarningDisplayData: accessed-variable=rSR_HudWarningDisplay.HudWarningDisplayData
              DRP_rSR_IgnState_IgnStateData: accessed-variable=rSR_IgnState.IgnStateData
              DRA_rSR_IlluminationData_IlluminationDataData: accessed-variable=rSR_IlluminationData.IlluminationDataData
              DRA_rSR_PowerSystemStateReqChange_PowerSystemStateReqChangeData: accessed-variable=rSR_PowerSystemStateReqChange.PowerSystemStateReqChangeData
              DRA_rSR_RTT_Icon_RTT_IconData: accessed-variable=rSR_RTT_Icon.RTT_IconData
              DRA_rSR_RTT_Status_RTT_StatusData: accessed-variable=rSR_RTT_Status.RTT_StatusData
              DRA_rSR_RTT_Toggle_RTT_ToggleData: accessed-variable=rSR_RTT_Toggle.RTT_ToggleData
              DRA_rSR_ShiftPosIndStatus_ShiftPosIndStatusData: accessed-variable=rSR_ShiftPosIndStatus.ShiftPosIndStatusData
              DRA_rSR_SlowGaugeInfo_SlowGaugeInfoData: accessed-variable=rSR_SlowGaugeInfo.SlowGaugeInfoData
              DRA_rSR_TT_Status_TT_StatusData: accessed-variable=rSR_TT_Status.TT_StatusData
              DRA_rSR_TpmsWarningData_TpmsWarningDataData: accessed-variable=rSR_TpmsWarningData.TpmsWarningDataData
              DRP_rSR_UpdateLongServiceReq_UpdateLongServiceReqData: accessed-variable=rSR_UpdateLongServiceReq.UpdateLongServiceReqData
              DRP_rSR_UpdateShortServiceReq_UpdateShortServiceReqData: accessed-variable=rSR_UpdateShortServiceReq.UpdateShortServiceReqData
              DRA_rSR_WarningDisplay_WarningDisplayData: accessed-variable=rSR_WarningDisplay.WarningDisplayData
              DRA_rSR_WarningExtDisplay_WarningExtDisplayData: accessed-variable=rSR_WarningExtDisplay.WarningExtDisplayData
          data-send-points:
            19 x access:
              DWA_pSR_DLTControlMessageRequest_DLTControlMessageRequestData: accessed-variable=pSR_DLTControlMessageRequest.DLTControlMessageRequestData
              DWA_pSR_DLTMessageReadAck_DLTMessageReadAckData: accessed-variable=pSR_DLTMessageReadAck.DLTMessageReadAckData
              DSP_pSR_DiagResponse_DiagResponseData: accessed-variable=pSR_DiagResponse.DiagResponseData
              DWA_pSR_DisplayCurrentState_DisplayCurrentStateData: accessed-variable=pSR_DisplayCurrentState.DisplayCurrentStateData
              DWA_pSR_EmmcErrorNotifier_EmmcErrorNotifierData: accessed-variable=pSR_EmmcErrorNotifier.EmmcErrorNotifierData
              DSP_pSR_HealthDomainFatalError_HealthDomainFatalErrorData: accessed-variable=pSR_HealthDomainFatalError.HealthDomainFatalErrorData
              DSP_pSR_HealthDomainHeartbeat_HealthDomainHeartbeatData: accessed-variable=pSR_HealthDomainHeartbeat.HealthDomainHeartbeatData
              DSP_pSR_HealthDumpData_HealthDumpDataData: accessed-variable=pSR_HealthDumpData.HealthDumpDataData
              DSP_pSR_HealthDumpHdrInfo_HealthDumpHdrInfoData: accessed-variable=pSR_HealthDumpHdrInfo.HealthDumpHdrInfoData
              DSP_pSR_HealthEventRecord_HealthEventRecordData: accessed-variable=pSR_HealthEventRecord.HealthEventRecordData
              DWA_pSR_HudWarningStatus_HudWarningStatusData: accessed-variable=pSR_HudWarningStatus.HudWarningStatusData
              DSP_pSR_MainHMIReadyStatus_MainHMIReadyStatusData: accessed-variable=pSR_MainHMIReadyStatus.MainHMIReadyStatusData
              DSP_pSR_PowerExtendShutdownTime_PowerExtendShutdownTimeData: accessed-variable=pSR_PowerExtendShutdownTime.PowerExtendShutdownTimeData
              DSP_pSR_PowerKeepSystemAwake_PowerKeepSystemAwakeData: accessed-variable=pSR_PowerKeepSystemAwake.PowerKeepSystemAwakeData
              DWA_pSR_PowerSystemState_PowerSystemStateData: accessed-variable=pSR_PowerSystemState.PowerSystemStateData
              DSP_pSR_SafeHMIReadyStatus_SafeHMIReadyStatusData: accessed-variable=pSR_SafeHMIReadyStatus.SafeHMIReadyStatusData
              DSP_pSR_UpdateShortServiceResp_UpdateShortServiceRespData: accessed-variable=pSR_UpdateShortServiceResp.UpdateShortServiceRespData
              DWA_pSR_WarningDisplayAvailable_WarningDisplayAvailableData: accessed-variable=pSR_WarningDisplayAvailable.WarningDisplayAvailableData
              DWA_pSR_WarningStatus_WarningStatusData: accessed-variable=pSR_WarningStatus.WarningStatusData
          sync call OA_rCS_UclSystemCallbacks_ErrorNotification: operation=rCS_UclSystemCallbacks.ErrorNotification, timeout=0.0
          sync call OA_rCS_UclSystemCallbacks_LinkStatusChanged: operation=rCS_UclSystemCallbacks.LinkStatusChanged, timeout=0.0
        OnDre_RTT_Icon
          data-receive-point-by-arguments:
            25 x access:
              DRA_rSR_DLTControlMessageReponse_DLTControlMessageReponseData: accessed-variable=rSR_DLTControlMessageReponse.DLTControlMessageReponseData
              DRA_rSR_DLTMessageReadRequest_DLTMessageReadRequestData: accessed-variable=rSR_DLTMessageReadRequest.DLTMessageReadRequestData
              DRP_rSR_DiagDIDRequest_DiagDIDRequestData: accessed-variable=rSR_DiagDIDRequest.DiagDIDRequestData
              DRP_rSR_DiagIOCtrlRequest_DiagIOCtrlRequestData: accessed-variable=rSR_DiagIOCtrlRequest.DiagIOCtrlRequestData
              DRP_rSR_DiagRoutineRequest_DiagRoutineRequestData: accessed-variable=rSR_DiagRoutineRequest.DiagRoutineRequestData
              DRA_rSR_DisplaySetPower_DisplaySetPowerData: accessed-variable=rSR_DisplaySetPower.DisplaySetPowerData
              DRA_rSR_FRTT_Status_FRTT_StatusData: accessed-variable=rSR_FRTT_Status.FRTT_StatusData
              DRA_rSR_FastGaugeInfo_FastGaugeInfoData: accessed-variable=rSR_FastGaugeInfo.FastGaugeInfoData
              DRP_rSR_HealthDumpGetData_HealthDumpGetDataData: accessed-variable=rSR_HealthDumpGetData.HealthDumpGetDataData
              DRP_rSR_HealthDumpGetHdr_HealthDumpGetHdrData: accessed-variable=rSR_HealthDumpGetHdr.HealthDumpGetHdrData
              DRA_rSR_HudWarningDisplay_HudWarningDisplayData: accessed-variable=rSR_HudWarningDisplay.HudWarningDisplayData
              DRP_rSR_IgnState_IgnStateData: accessed-variable=rSR_IgnState.IgnStateData
              DRA_rSR_IlluminationData_IlluminationDataData: accessed-variable=rSR_IlluminationData.IlluminationDataData
              DRA_rSR_PowerSystemStateReqChange_PowerSystemStateReqChangeData: accessed-variable=rSR_PowerSystemStateReqChange.PowerSystemStateReqChangeData
              DRA_rSR_RTT_Icon_RTT_IconData: accessed-variable=rSR_RTT_Icon.RTT_IconData
              DRA_rSR_RTT_Status_RTT_StatusData: accessed-variable=rSR_RTT_Status.RTT_StatusData
              DRA_rSR_RTT_Toggle_RTT_ToggleData: accessed-variable=rSR_RTT_Toggle.RTT_ToggleData
              DRA_rSR_ShiftPosIndStatus_ShiftPosIndStatusData: accessed-variable=rSR_ShiftPosIndStatus.ShiftPosIndStatusData
              DRA_rSR_SlowGaugeInfo_SlowGaugeInfoData: accessed-variable=rSR_SlowGaugeInfo.SlowGaugeInfoData
              DRA_rSR_TT_Status_TT_StatusData: accessed-variable=rSR_TT_Status.TT_StatusData
              DRA_rSR_TpmsWarningData_TpmsWarningDataData: accessed-variable=rSR_TpmsWarningData.TpmsWarningDataData
              DRP_rSR_UpdateLongServiceReq_UpdateLongServiceReqData: accessed-variable=rSR_UpdateLongServiceReq.UpdateLongServiceReqData
              DRP_rSR_UpdateShortServiceReq_UpdateShortServiceReqData: accessed-variable=rSR_UpdateShortServiceReq.UpdateShortServiceReqData
              DRA_rSR_WarningDisplay_WarningDisplayData: accessed-variable=rSR_WarningDisplay.WarningDisplayData
              DRA_rSR_WarningExtDisplay_WarningExtDisplayData: accessed-variable=rSR_WarningExtDisplay.WarningExtDisplayData
          data-send-points:
            19 x access:
              DWA_pSR_DLTControlMessageRequest_DLTControlMessageRequestData: accessed-variable=pSR_DLTControlMessageRequest.DLTControlMessageRequestData
              DWA_pSR_DLTMessageReadAck_DLTMessageReadAckData: accessed-variable=pSR_DLTMessageReadAck.DLTMessageReadAckData
              DSP_pSR_DiagResponse_DiagResponseData: accessed-variable=pSR_DiagResponse.DiagResponseData
              DWA_pSR_DisplayCurrentState_DisplayCurrentStateData: accessed-variable=pSR_DisplayCurrentState.DisplayCurrentStateData
              DWA_pSR_EmmcErrorNotifier_EmmcErrorNotifierData: accessed-variable=pSR_EmmcErrorNotifier.EmmcErrorNotifierData
              DSP_pSR_HealthDomainFatalError_HealthDomainFatalErrorData: accessed-variable=pSR_HealthDomainFatalError.HealthDomainFatalErrorData
              DSP_pSR_HealthDomainHeartbeat_HealthDomainHeartbeatData: accessed-variable=pSR_HealthDomainHeartbeat.HealthDomainHeartbeatData
              DSP_pSR_HealthDumpData_HealthDumpDataData: accessed-variable=pSR_HealthDumpData.HealthDumpDataData
              DSP_pSR_HealthDumpHdrInfo_HealthDumpHdrInfoData: accessed-variable=pSR_HealthDumpHdrInfo.HealthDumpHdrInfoData
              DSP_pSR_HealthEventRecord_HealthEventRecordData: accessed-variable=pSR_HealthEventRecord.HealthEventRecordData
              DWA_pSR_HudWarningStatus_HudWarningStatusData: accessed-variable=pSR_HudWarningStatus.HudWarningStatusData
              DSP_pSR_MainHMIReadyStatus_MainHMIReadyStatusData: accessed-variable=pSR_MainHMIReadyStatus.MainHMIReadyStatusData
              DSP_pSR_PowerExtendShutdownTime_PowerExtendShutdownTimeData: accessed-variable=pSR_PowerExtendShutdownTime.PowerExtendShutdownTimeData
              DSP_pSR_PowerKeepSystemAwake_PowerKeepSystemAwakeData: accessed-variable=pSR_PowerKeepSystemAwake.PowerKeepSystemAwakeData
              DWA_pSR_PowerSystemState_PowerSystemStateData: accessed-variable=pSR_PowerSystemState.PowerSystemStateData
              DSP_pSR_SafeHMIReadyStatus_SafeHMIReadyStatusData: accessed-variable=pSR_SafeHMIReadyStatus.SafeHMIReadyStatusData
              DSP_pSR_UpdateShortServiceResp_UpdateShortServiceRespData: accessed-variable=pSR_UpdateShortServiceResp.UpdateShortServiceRespData
              DWA_pSR_WarningDisplayAvailable_WarningDisplayAvailableData: accessed-variable=pSR_WarningDisplayAvailable.WarningDisplayAvailableData
              DWA_pSR_WarningStatus_WarningStatusData: accessed-variable=pSR_WarningStatus.WarningStatusData
          sync call OA_rCS_UclSystemCallbacks_ErrorNotification: operation=rCS_UclSystemCallbacks.ErrorNotification, timeout=0.0
          sync call OA_rCS_UclSystemCallbacks_LinkStatusChanged: operation=rCS_UclSystemCallbacks.LinkStatusChanged, timeout=0.0
        OnDre_RTT_Status
          data-receive-point-by-arguments:
            25 x access:
              DRA_rSR_DLTControlMessageReponse_DLTControlMessageReponseData: accessed-variable=rSR_DLTControlMessageReponse.DLTControlMessageReponseData
              DRA_rSR_DLTMessageReadRequest_DLTMessageReadRequestData: accessed-variable=rSR_DLTMessageReadRequest.DLTMessageReadRequestData
              DRP_rSR_DiagDIDRequest_DiagDIDRequestData: accessed-variable=rSR_DiagDIDRequest.DiagDIDRequestData
              DRP_rSR_DiagIOCtrlRequest_DiagIOCtrlRequestData: accessed-variable=rSR_DiagIOCtrlRequest.DiagIOCtrlRequestData
              DRP_rSR_DiagRoutineRequest_DiagRoutineRequestData: accessed-variable=rSR_DiagRoutineRequest.DiagRoutineRequestData
              DRA_rSR_DisplaySetPower_DisplaySetPowerData: accessed-variable=rSR_DisplaySetPower.DisplaySetPowerData
              DRA_rSR_FRTT_Status_FRTT_StatusData: accessed-variable=rSR_FRTT_Status.FRTT_StatusData
              DRA_rSR_FastGaugeInfo_FastGaugeInfoData: accessed-variable=rSR_FastGaugeInfo.FastGaugeInfoData
              DRP_rSR_HealthDumpGetData_HealthDumpGetDataData: accessed-variable=rSR_HealthDumpGetData.HealthDumpGetDataData
              DRP_rSR_HealthDumpGetHdr_HealthDumpGetHdrData: accessed-variable=rSR_HealthDumpGetHdr.HealthDumpGetHdrData
              DRA_rSR_HudWarningDisplay_HudWarningDisplayData: accessed-variable=rSR_HudWarningDisplay.HudWarningDisplayData
              DRP_rSR_IgnState_IgnStateData: accessed-variable=rSR_IgnState.IgnStateData
              DRA_rSR_IlluminationData_IlluminationDataData: accessed-variable=rSR_IlluminationData.IlluminationDataData
              DRA_rSR_PowerSystemStateReqChange_PowerSystemStateReqChangeData: accessed-variable=rSR_PowerSystemStateReqChange.PowerSystemStateReqChangeData
              DRA_rSR_RTT_Icon_RTT_IconData: accessed-variable=rSR_RTT_Icon.RTT_IconData
              DRA_rSR_RTT_Status_RTT_StatusData: accessed-variable=rSR_RTT_Status.RTT_StatusData
              DRA_rSR_RTT_Toggle_RTT_ToggleData: accessed-variable=rSR_RTT_Toggle.RTT_ToggleData
              DRA_rSR_ShiftPosIndStatus_ShiftPosIndStatusData: accessed-variable=rSR_ShiftPosIndStatus.ShiftPosIndStatusData
              DRA_rSR_SlowGaugeInfo_SlowGaugeInfoData: accessed-variable=rSR_SlowGaugeInfo.SlowGaugeInfoData
              DRA_rSR_TT_Status_TT_StatusData: accessed-variable=rSR_TT_Status.TT_StatusData
              DRA_rSR_TpmsWarningData_TpmsWarningDataData: accessed-variable=rSR_TpmsWarningData.TpmsWarningDataData
              DRP_rSR_UpdateLongServiceReq_UpdateLongServiceReqData: accessed-variable=rSR_UpdateLongServiceReq.UpdateLongServiceReqData
              DRP_rSR_UpdateShortServiceReq_UpdateShortServiceReqData: accessed-variable=rSR_UpdateShortServiceReq.UpdateShortServiceReqData
              DRA_rSR_WarningDisplay_WarningDisplayData: accessed-variable=rSR_WarningDisplay.WarningDisplayData
              DRA_rSR_WarningExtDisplay_WarningExtDisplayData: accessed-variable=rSR_WarningExtDisplay.WarningExtDisplayData
          data-send-points:
            19 x access:
              DWA_pSR_DLTControlMessageRequest_DLTControlMessageRequestData: accessed-variable=pSR_DLTControlMessageRequest.DLTControlMessageRequestData
              DWA_pSR_DLTMessageReadAck_DLTMessageReadAckData: accessed-variable=pSR_DLTMessageReadAck.DLTMessageReadAckData
              DSP_pSR_DiagResponse_DiagResponseData: accessed-variable=pSR_DiagResponse.DiagResponseData
              DWA_pSR_DisplayCurrentState_DisplayCurrentStateData: accessed-variable=pSR_DisplayCurrentState.DisplayCurrentStateData
              DWA_pSR_EmmcErrorNotifier_EmmcErrorNotifierData: accessed-variable=pSR_EmmcErrorNotifier.EmmcErrorNotifierData
              DSP_pSR_HealthDomainFatalError_HealthDomainFatalErrorData: accessed-variable=pSR_HealthDomainFatalError.HealthDomainFatalErrorData
              DSP_pSR_HealthDomainHeartbeat_HealthDomainHeartbeatData: accessed-variable=pSR_HealthDomainHeartbeat.HealthDomainHeartbeatData
              DSP_pSR_HealthDumpData_HealthDumpDataData: accessed-variable=pSR_HealthDumpData.HealthDumpDataData
              DSP_pSR_HealthDumpHdrInfo_HealthDumpHdrInfoData: accessed-variable=pSR_HealthDumpHdrInfo.HealthDumpHdrInfoData
              DSP_pSR_HealthEventRecord_HealthEventRecordData: accessed-variable=pSR_HealthEventRecord.HealthEventRecordData
              DWA_pSR_HudWarningStatus_HudWarningStatusData: accessed-variable=pSR_HudWarningStatus.HudWarningStatusData
              DSP_pSR_MainHMIReadyStatus_MainHMIReadyStatusData: accessed-variable=pSR_MainHMIReadyStatus.MainHMIReadyStatusData
              DSP_pSR_PowerExtendShutdownTime_PowerExtendShutdownTimeData: accessed-variable=pSR_PowerExtendShutdownTime.PowerExtendShutdownTimeData
              DSP_pSR_PowerKeepSystemAwake_PowerKeepSystemAwakeData: accessed-variable=pSR_PowerKeepSystemAwake.PowerKeepSystemAwakeData
              DWA_pSR_PowerSystemState_PowerSystemStateData: accessed-variable=pSR_PowerSystemState.PowerSystemStateData
              DSP_pSR_SafeHMIReadyStatus_SafeHMIReadyStatusData: accessed-variable=pSR_SafeHMIReadyStatus.SafeHMIReadyStatusData
              DSP_pSR_UpdateShortServiceResp_UpdateShortServiceRespData: accessed-variable=pSR_UpdateShortServiceResp.UpdateShortServiceRespData
              DWA_pSR_WarningDisplayAvailable_WarningDisplayAvailableData: accessed-variable=pSR_WarningDisplayAvailable.WarningDisplayAvailableData
              DWA_pSR_WarningStatus_WarningStatusData: accessed-variable=pSR_WarningStatus.WarningStatusData
          sync call OA_rCS_UclSystemCallbacks_ErrorNotification: operation=rCS_UclSystemCallbacks.ErrorNotification, timeout=0.0
          sync call OA_rCS_UclSystemCallbacks_LinkStatusChanged: operation=rCS_UclSystemCallbacks.LinkStatusChanged, timeout=0.0
        OnDre_RTT_Toggle
          data-receive-point-by-arguments:
            25 x access:
              DRA_rSR_DLTControlMessageReponse_DLTControlMessageReponseData: accessed-variable=rSR_DLTControlMessageReponse.DLTControlMessageReponseData
              DRA_rSR_DLTMessageReadRequest_DLTMessageReadRequestData: accessed-variable=rSR_DLTMessageReadRequest.DLTMessageReadRequestData
              DRP_rSR_DiagDIDRequest_DiagDIDRequestData: accessed-variable=rSR_DiagDIDRequest.DiagDIDRequestData
              DRP_rSR_DiagIOCtrlRequest_DiagIOCtrlRequestData: accessed-variable=rSR_DiagIOCtrlRequest.DiagIOCtrlRequestData
              DRP_rSR_DiagRoutineRequest_DiagRoutineRequestData: accessed-variable=rSR_DiagRoutineRequest.DiagRoutineRequestData
              DRA_rSR_DisplaySetPower_DisplaySetPowerData: accessed-variable=rSR_DisplaySetPower.DisplaySetPowerData
              DRA_rSR_FRTT_Status_FRTT_StatusData: accessed-variable=rSR_FRTT_Status.FRTT_StatusData
              DRA_rSR_FastGaugeInfo_FastGaugeInfoData: accessed-variable=rSR_FastGaugeInfo.FastGaugeInfoData
              DRP_rSR_HealthDumpGetData_HealthDumpGetDataData: accessed-variable=rSR_HealthDumpGetData.HealthDumpGetDataData
              DRP_rSR_HealthDumpGetHdr_HealthDumpGetHdrData: accessed-variable=rSR_HealthDumpGetHdr.HealthDumpGetHdrData
              DRA_rSR_HudWarningDisplay_HudWarningDisplayData: accessed-variable=rSR_HudWarningDisplay.HudWarningDisplayData
              DRP_rSR_IgnState_IgnStateData: accessed-variable=rSR_IgnState.IgnStateData
              DRA_rSR_IlluminationData_IlluminationDataData: accessed-variable=rSR_IlluminationData.IlluminationDataData
              DRA_rSR_PowerSystemStateReqChange_PowerSystemStateReqChangeData: accessed-variable=rSR_PowerSystemStateReqChange.PowerSystemStateReqChangeData
              DRA_rSR_RTT_Icon_RTT_IconData: accessed-variable=rSR_RTT_Icon.RTT_IconData
              DRA_rSR_RTT_Status_RTT_StatusData: accessed-variable=rSR_RTT_Status.RTT_StatusData
              DRA_rSR_RTT_Toggle_RTT_ToggleData: accessed-variable=rSR_RTT_Toggle.RTT_ToggleData
              DRA_rSR_ShiftPosIndStatus_ShiftPosIndStatusData: accessed-variable=rSR_ShiftPosIndStatus.ShiftPosIndStatusData
              DRA_rSR_SlowGaugeInfo_SlowGaugeInfoData: accessed-variable=rSR_SlowGaugeInfo.SlowGaugeInfoData
              DRA_rSR_TT_Status_TT_StatusData: accessed-variable=rSR_TT_Status.TT_StatusData
              DRA_rSR_TpmsWarningData_TpmsWarningDataData: accessed-variable=rSR_TpmsWarningData.TpmsWarningDataData
              DRP_rSR_UpdateLongServiceReq_UpdateLongServiceReqData: accessed-variable=rSR_UpdateLongServiceReq.UpdateLongServiceReqData
              DRP_rSR_UpdateShortServiceReq_UpdateShortServiceReqData: accessed-variable=rSR_UpdateShortServiceReq.UpdateShortServiceReqData
              DRA_rSR_WarningDisplay_WarningDisplayData: accessed-variable=rSR_WarningDisplay.WarningDisplayData
              DRA_rSR_WarningExtDisplay_WarningExtDisplayData: accessed-variable=rSR_WarningExtDisplay.WarningExtDisplayData
          data-send-points:
            19 x access:
              DWA_pSR_DLTControlMessageRequest_DLTControlMessageRequestData: accessed-variable=pSR_DLTControlMessageRequest.DLTControlMessageRequestData
              DWA_pSR_DLTMessageReadAck_DLTMessageReadAckData: accessed-variable=pSR_DLTMessageReadAck.DLTMessageReadAckData
              DSP_pSR_DiagResponse_DiagResponseData: accessed-variable=pSR_DiagResponse.DiagResponseData
              DWA_pSR_DisplayCurrentState_DisplayCurrentStateData: accessed-variable=pSR_DisplayCurrentState.DisplayCurrentStateData
              DWA_pSR_EmmcErrorNotifier_EmmcErrorNotifierData: accessed-variable=pSR_EmmcErrorNotifier.EmmcErrorNotifierData
              DSP_pSR_HealthDomainFatalError_HealthDomainFatalErrorData: accessed-variable=pSR_HealthDomainFatalError.HealthDomainFatalErrorData
              DSP_pSR_HealthDomainHeartbeat_HealthDomainHeartbeatData: accessed-variable=pSR_HealthDomainHeartbeat.HealthDomainHeartbeatData
              DSP_pSR_HealthDumpData_HealthDumpDataData: accessed-variable=pSR_HealthDumpData.HealthDumpDataData
              DSP_pSR_HealthDumpHdrInfo_HealthDumpHdrInfoData: accessed-variable=pSR_HealthDumpHdrInfo.HealthDumpHdrInfoData
              DSP_pSR_HealthEventRecord_HealthEventRecordData: accessed-variable=pSR_HealthEventRecord.HealthEventRecordData
              DWA_pSR_HudWarningStatus_HudWarningStatusData: accessed-variable=pSR_HudWarningStatus.HudWarningStatusData
              DSP_pSR_MainHMIReadyStatus_MainHMIReadyStatusData: accessed-variable=pSR_MainHMIReadyStatus.MainHMIReadyStatusData
              DSP_pSR_PowerExtendShutdownTime_PowerExtendShutdownTimeData: accessed-variable=pSR_PowerExtendShutdownTime.PowerExtendShutdownTimeData
              DSP_pSR_PowerKeepSystemAwake_PowerKeepSystemAwakeData: accessed-variable=pSR_PowerKeepSystemAwake.PowerKeepSystemAwakeData
              DWA_pSR_PowerSystemState_PowerSystemStateData: accessed-variable=pSR_PowerSystemState.PowerSystemStateData
              DSP_pSR_SafeHMIReadyStatus_SafeHMIReadyStatusData: accessed-variable=pSR_SafeHMIReadyStatus.SafeHMIReadyStatusData
              DSP_pSR_UpdateShortServiceResp_UpdateShortServiceRespData: accessed-variable=pSR_UpdateShortServiceResp.UpdateShortServiceRespData
              DWA_pSR_WarningDisplayAvailable_WarningDisplayAvailableData: accessed-variable=pSR_WarningDisplayAvailable.WarningDisplayAvailableData
              DWA_pSR_WarningStatus_WarningStatusData: accessed-variable=pSR_WarningStatus.WarningStatusData
          sync call OA_rCS_UclSystemCallbacks_ErrorNotification: operation=rCS_UclSystemCallbacks.ErrorNotification, timeout=0.0
          sync call OA_rCS_UclSystemCallbacks_LinkStatusChanged: operation=rCS_UclSystemCallbacks.LinkStatusChanged, timeout=0.0
        OnDre_ShiftPosIndStatus
          data-receive-point-by-arguments:
            25 x access:
              DRA_rSR_DLTControlMessageReponse_DLTControlMessageReponseData: accessed-variable=rSR_DLTControlMessageReponse.DLTControlMessageReponseData
              DRA_rSR_DLTMessageReadRequest_DLTMessageReadRequestData: accessed-variable=rSR_DLTMessageReadRequest.DLTMessageReadRequestData
              DRP_rSR_DiagDIDRequest_DiagDIDRequestData: accessed-variable=rSR_DiagDIDRequest.DiagDIDRequestData
              DRP_rSR_DiagIOCtrlRequest_DiagIOCtrlRequestData: accessed-variable=rSR_DiagIOCtrlRequest.DiagIOCtrlRequestData
              DRP_rSR_DiagRoutineRequest_DiagRoutineRequestData: accessed-variable=rSR_DiagRoutineRequest.DiagRoutineRequestData
              DRA_rSR_DisplaySetPower_DisplaySetPowerData: accessed-variable=rSR_DisplaySetPower.DisplaySetPowerData
              DRA_rSR_FRTT_Status_FRTT_StatusData: accessed-variable=rSR_FRTT_Status.FRTT_StatusData
              DRA_rSR_FastGaugeInfo_FastGaugeInfoData: accessed-variable=rSR_FastGaugeInfo.FastGaugeInfoData
              DRP_rSR_HealthDumpGetData_HealthDumpGetDataData: accessed-variable=rSR_HealthDumpGetData.HealthDumpGetDataData
              DRP_rSR_HealthDumpGetHdr_HealthDumpGetHdrData: accessed-variable=rSR_HealthDumpGetHdr.HealthDumpGetHdrData
              DRA_rSR_HudWarningDisplay_HudWarningDisplayData: accessed-variable=rSR_HudWarningDisplay.HudWarningDisplayData
              DRP_rSR_IgnState_IgnStateData: accessed-variable=rSR_IgnState.IgnStateData
              DRA_rSR_IlluminationData_IlluminationDataData: accessed-variable=rSR_IlluminationData.IlluminationDataData
              DRA_rSR_PowerSystemStateReqChange_PowerSystemStateReqChangeData: accessed-variable=rSR_PowerSystemStateReqChange.PowerSystemStateReqChangeData
              DRA_rSR_RTT_Icon_RTT_IconData: accessed-variable=rSR_RTT_Icon.RTT_IconData
              DRA_rSR_RTT_Status_RTT_StatusData: accessed-variable=rSR_RTT_Status.RTT_StatusData
              DRA_rSR_RTT_Toggle_RTT_ToggleData: accessed-variable=rSR_RTT_Toggle.RTT_ToggleData
              DRA_rSR_ShiftPosIndStatus_ShiftPosIndStatusData: accessed-variable=rSR_ShiftPosIndStatus.ShiftPosIndStatusData
              DRA_rSR_SlowGaugeInfo_SlowGaugeInfoData: accessed-variable=rSR_SlowGaugeInfo.SlowGaugeInfoData
              DRA_rSR_TT_Status_TT_StatusData: accessed-variable=rSR_TT_Status.TT_StatusData
              DRA_rSR_TpmsWarningData_TpmsWarningDataData: accessed-variable=rSR_TpmsWarningData.TpmsWarningDataData
              DRP_rSR_UpdateLongServiceReq_UpdateLongServiceReqData: accessed-variable=rSR_UpdateLongServiceReq.UpdateLongServiceReqData
              DRP_rSR_UpdateShortServiceReq_UpdateShortServiceReqData: accessed-variable=rSR_UpdateShortServiceReq.UpdateShortServiceReqData
              DRA_rSR_WarningDisplay_WarningDisplayData: accessed-variable=rSR_WarningDisplay.WarningDisplayData
              DRA_rSR_WarningExtDisplay_WarningExtDisplayData: accessed-variable=rSR_WarningExtDisplay.WarningExtDisplayData
          data-send-points:
            19 x access:
              DWA_pSR_DLTControlMessageRequest_DLTControlMessageRequestData: accessed-variable=pSR_DLTControlMessageRequest.DLTControlMessageRequestData
              DWA_pSR_DLTMessageReadAck_DLTMessageReadAckData: accessed-variable=pSR_DLTMessageReadAck.DLTMessageReadAckData
              DSP_pSR_DiagResponse_DiagResponseData: accessed-variable=pSR_DiagResponse.DiagResponseData
              DWA_pSR_DisplayCurrentState_DisplayCurrentStateData: accessed-variable=pSR_DisplayCurrentState.DisplayCurrentStateData
              DWA_pSR_EmmcErrorNotifier_EmmcErrorNotifierData: accessed-variable=pSR_EmmcErrorNotifier.EmmcErrorNotifierData
              DSP_pSR_HealthDomainFatalError_HealthDomainFatalErrorData: accessed-variable=pSR_HealthDomainFatalError.HealthDomainFatalErrorData
              DSP_pSR_HealthDomainHeartbeat_HealthDomainHeartbeatData: accessed-variable=pSR_HealthDomainHeartbeat.HealthDomainHeartbeatData
              DSP_pSR_HealthDumpData_HealthDumpDataData: accessed-variable=pSR_HealthDumpData.HealthDumpDataData
              DSP_pSR_HealthDumpHdrInfo_HealthDumpHdrInfoData: accessed-variable=pSR_HealthDumpHdrInfo.HealthDumpHdrInfoData
              DSP_pSR_HealthEventRecord_HealthEventRecordData: accessed-variable=pSR_HealthEventRecord.HealthEventRecordData
              DWA_pSR_HudWarningStatus_HudWarningStatusData: accessed-variable=pSR_HudWarningStatus.HudWarningStatusData
              DSP_pSR_MainHMIReadyStatus_MainHMIReadyStatusData: accessed-variable=pSR_MainHMIReadyStatus.MainHMIReadyStatusData
              DSP_pSR_PowerExtendShutdownTime_PowerExtendShutdownTimeData: accessed-variable=pSR_PowerExtendShutdownTime.PowerExtendShutdownTimeData
              DSP_pSR_PowerKeepSystemAwake_PowerKeepSystemAwakeData: accessed-variable=pSR_PowerKeepSystemAwake.PowerKeepSystemAwakeData
              DWA_pSR_PowerSystemState_PowerSystemStateData: accessed-variable=pSR_PowerSystemState.PowerSystemStateData
              DSP_pSR_SafeHMIReadyStatus_SafeHMIReadyStatusData: accessed-variable=pSR_SafeHMIReadyStatus.SafeHMIReadyStatusData
              DSP_pSR_UpdateShortServiceResp_UpdateShortServiceRespData: accessed-variable=pSR_UpdateShortServiceResp.UpdateShortServiceRespData
              DWA_pSR_WarningDisplayAvailable_WarningDisplayAvailableData: accessed-variable=pSR_WarningDisplayAvailable.WarningDisplayAvailableData
              DWA_pSR_WarningStatus_WarningStatusData: accessed-variable=pSR_WarningStatus.WarningStatusData
          sync call OA_rCS_UclSystemCallbacks_ErrorNotification: operation=rCS_UclSystemCallbacks.ErrorNotification, timeout=0.0
          sync call OA_rCS_UclSystemCallbacks_LinkStatusChanged: operation=rCS_UclSystemCallbacks.LinkStatusChanged, timeout=0.0
        OnDre_SlowGaugeInfo
          data-receive-point-by-arguments:
            25 x access:
              DRA_rSR_DLTControlMessageReponse_DLTControlMessageReponseData: accessed-variable=rSR_DLTControlMessageReponse.DLTControlMessageReponseData
              DRA_rSR_DLTMessageReadRequest_DLTMessageReadRequestData: accessed-variable=rSR_DLTMessageReadRequest.DLTMessageReadRequestData
              DRP_rSR_DiagDIDRequest_DiagDIDRequestData: accessed-variable=rSR_DiagDIDRequest.DiagDIDRequestData
              DRP_rSR_DiagIOCtrlRequest_DiagIOCtrlRequestData: accessed-variable=rSR_DiagIOCtrlRequest.DiagIOCtrlRequestData
              DRP_rSR_DiagRoutineRequest_DiagRoutineRequestData: accessed-variable=rSR_DiagRoutineRequest.DiagRoutineRequestData
              DRA_rSR_DisplaySetPower_DisplaySetPowerData: accessed-variable=rSR_DisplaySetPower.DisplaySetPowerData
              DRA_rSR_FRTT_Status_FRTT_StatusData: accessed-variable=rSR_FRTT_Status.FRTT_StatusData
              DRA_rSR_FastGaugeInfo_FastGaugeInfoData: accessed-variable=rSR_FastGaugeInfo.FastGaugeInfoData
              DRP_rSR_HealthDumpGetData_HealthDumpGetDataData: accessed-variable=rSR_HealthDumpGetData.HealthDumpGetDataData
              DRP_rSR_HealthDumpGetHdr_HealthDumpGetHdrData: accessed-variable=rSR_HealthDumpGetHdr.HealthDumpGetHdrData
              DRA_rSR_HudWarningDisplay_HudWarningDisplayData: accessed-variable=rSR_HudWarningDisplay.HudWarningDisplayData
              DRP_rSR_IgnState_IgnStateData: accessed-variable=rSR_IgnState.IgnStateData
              DRA_rSR_IlluminationData_IlluminationDataData: accessed-variable=rSR_IlluminationData.IlluminationDataData
              DRA_rSR_PowerSystemStateReqChange_PowerSystemStateReqChangeData: accessed-variable=rSR_PowerSystemStateReqChange.PowerSystemStateReqChangeData
              DRA_rSR_RTT_Icon_RTT_IconData: accessed-variable=rSR_RTT_Icon.RTT_IconData
              DRA_rSR_RTT_Status_RTT_StatusData: accessed-variable=rSR_RTT_Status.RTT_StatusData
              DRA_rSR_RTT_Toggle_RTT_ToggleData: accessed-variable=rSR_RTT_Toggle.RTT_ToggleData
              DRA_rSR_ShiftPosIndStatus_ShiftPosIndStatusData: accessed-variable=rSR_ShiftPosIndStatus.ShiftPosIndStatusData
              DRA_rSR_SlowGaugeInfo_SlowGaugeInfoData: accessed-variable=rSR_SlowGaugeInfo.SlowGaugeInfoData
              DRA_rSR_TT_Status_TT_StatusData: accessed-variable=rSR_TT_Status.TT_StatusData
              DRA_rSR_TpmsWarningData_TpmsWarningDataData: accessed-variable=rSR_TpmsWarningData.TpmsWarningDataData
              DRP_rSR_UpdateLongServiceReq_UpdateLongServiceReqData: accessed-variable=rSR_UpdateLongServiceReq.UpdateLongServiceReqData
              DRP_rSR_UpdateShortServiceReq_UpdateShortServiceReqData: accessed-variable=rSR_UpdateShortServiceReq.UpdateShortServiceReqData
              DRA_rSR_WarningDisplay_WarningDisplayData: accessed-variable=rSR_WarningDisplay.WarningDisplayData
              DRA_rSR_WarningExtDisplay_WarningExtDisplayData: accessed-variable=rSR_WarningExtDisplay.WarningExtDisplayData
          data-send-points:
            19 x access:
              DWA_pSR_DLTControlMessageRequest_DLTControlMessageRequestData: accessed-variable=pSR_DLTControlMessageRequest.DLTControlMessageRequestData
              DWA_pSR_DLTMessageReadAck_DLTMessageReadAckData: accessed-variable=pSR_DLTMessageReadAck.DLTMessageReadAckData
              DSP_pSR_DiagResponse_DiagResponseData: accessed-variable=pSR_DiagResponse.DiagResponseData
              DWA_pSR_DisplayCurrentState_DisplayCurrentStateData: accessed-variable=pSR_DisplayCurrentState.DisplayCurrentStateData
              DWA_pSR_EmmcErrorNotifier_EmmcErrorNotifierData: accessed-variable=pSR_EmmcErrorNotifier.EmmcErrorNotifierData
              DSP_pSR_HealthDomainFatalError_HealthDomainFatalErrorData: accessed-variable=pSR_HealthDomainFatalError.HealthDomainFatalErrorData
              DSP_pSR_HealthDomainHeartbeat_HealthDomainHeartbeatData: accessed-variable=pSR_HealthDomainHeartbeat.HealthDomainHeartbeatData
              DSP_pSR_HealthDumpData_HealthDumpDataData: accessed-variable=pSR_HealthDumpData.HealthDumpDataData
              DSP_pSR_HealthDumpHdrInfo_HealthDumpHdrInfoData: accessed-variable=pSR_HealthDumpHdrInfo.HealthDumpHdrInfoData
              DSP_pSR_HealthEventRecord_HealthEventRecordData: accessed-variable=pSR_HealthEventRecord.HealthEventRecordData
              DWA_pSR_HudWarningStatus_HudWarningStatusData: accessed-variable=pSR_HudWarningStatus.HudWarningStatusData
              DSP_pSR_MainHMIReadyStatus_MainHMIReadyStatusData: accessed-variable=pSR_MainHMIReadyStatus.MainHMIReadyStatusData
              DSP_pSR_PowerExtendShutdownTime_PowerExtendShutdownTimeData: accessed-variable=pSR_PowerExtendShutdownTime.PowerExtendShutdownTimeData
              DSP_pSR_PowerKeepSystemAwake_PowerKeepSystemAwakeData: accessed-variable=pSR_PowerKeepSystemAwake.PowerKeepSystemAwakeData
              DWA_pSR_PowerSystemState_PowerSystemStateData: accessed-variable=pSR_PowerSystemState.PowerSystemStateData
              DSP_pSR_SafeHMIReadyStatus_SafeHMIReadyStatusData: accessed-variable=pSR_SafeHMIReadyStatus.SafeHMIReadyStatusData
              DSP_pSR_UpdateShortServiceResp_UpdateShortServiceRespData: accessed-variable=pSR_UpdateShortServiceResp.UpdateShortServiceRespData
              DWA_pSR_WarningDisplayAvailable_WarningDisplayAvailableData: accessed-variable=pSR_WarningDisplayAvailable.WarningDisplayAvailableData
              DWA_pSR_WarningStatus_WarningStatusData: accessed-variable=pSR_WarningStatus.WarningStatusData
          sync call OA_rCS_UclSystemCallbacks_ErrorNotification: operation=rCS_UclSystemCallbacks.ErrorNotification, timeout=0.0
          sync call OA_rCS_UclSystemCallbacks_LinkStatusChanged: operation=rCS_UclSystemCallbacks.LinkStatusChanged, timeout=0.0
        OnDre_TT_Status
          data-receive-point-by-arguments:
            25 x access:
              DRA_rSR_DLTControlMessageReponse_DLTControlMessageReponseData: accessed-variable=rSR_DLTControlMessageReponse.DLTControlMessageReponseData
              DRA_rSR_DLTMessageReadRequest_DLTMessageReadRequestData: accessed-variable=rSR_DLTMessageReadRequest.DLTMessageReadRequestData
              DRP_rSR_DiagDIDRequest_DiagDIDRequestData: accessed-variable=rSR_DiagDIDRequest.DiagDIDRequestData
              DRP_rSR_DiagIOCtrlRequest_DiagIOCtrlRequestData: accessed-variable=rSR_DiagIOCtrlRequest.DiagIOCtrlRequestData
              DRP_rSR_DiagRoutineRequest_DiagRoutineRequestData: accessed-variable=rSR_DiagRoutineRequest.DiagRoutineRequestData
              DRA_rSR_DisplaySetPower_DisplaySetPowerData: accessed-variable=rSR_DisplaySetPower.DisplaySetPowerData
              DRA_rSR_FRTT_Status_FRTT_StatusData: accessed-variable=rSR_FRTT_Status.FRTT_StatusData
              DRA_rSR_FastGaugeInfo_FastGaugeInfoData: accessed-variable=rSR_FastGaugeInfo.FastGaugeInfoData
              DRP_rSR_HealthDumpGetData_HealthDumpGetDataData: accessed-variable=rSR_HealthDumpGetData.HealthDumpGetDataData
              DRP_rSR_HealthDumpGetHdr_HealthDumpGetHdrData: accessed-variable=rSR_HealthDumpGetHdr.HealthDumpGetHdrData
              DRA_rSR_HudWarningDisplay_HudWarningDisplayData: accessed-variable=rSR_HudWarningDisplay.HudWarningDisplayData
              DRP_rSR_IgnState_IgnStateData: accessed-variable=rSR_IgnState.IgnStateData
              DRA_rSR_IlluminationData_IlluminationDataData: accessed-variable=rSR_IlluminationData.IlluminationDataData
              DRA_rSR_PowerSystemStateReqChange_PowerSystemStateReqChangeData: accessed-variable=rSR_PowerSystemStateReqChange.PowerSystemStateReqChangeData
              DRA_rSR_RTT_Icon_RTT_IconData: accessed-variable=rSR_RTT_Icon.RTT_IconData
              DRA_rSR_RTT_Status_RTT_StatusData: accessed-variable=rSR_RTT_Status.RTT_StatusData
              DRA_rSR_RTT_Toggle_RTT_ToggleData: accessed-variable=rSR_RTT_Toggle.RTT_ToggleData
              DRA_rSR_ShiftPosIndStatus_ShiftPosIndStatusData: accessed-variable=rSR_ShiftPosIndStatus.ShiftPosIndStatusData
              DRA_rSR_SlowGaugeInfo_SlowGaugeInfoData: accessed-variable=rSR_SlowGaugeInfo.SlowGaugeInfoData
              DRA_rSR_TT_Status_TT_StatusData: accessed-variable=rSR_TT_Status.TT_StatusData
              DRA_rSR_TpmsWarningData_TpmsWarningDataData: accessed-variable=rSR_TpmsWarningData.TpmsWarningDataData
              DRP_rSR_UpdateLongServiceReq_UpdateLongServiceReqData: accessed-variable=rSR_UpdateLongServiceReq.UpdateLongServiceReqData
              DRP_rSR_UpdateShortServiceReq_UpdateShortServiceReqData: accessed-variable=rSR_UpdateShortServiceReq.UpdateShortServiceReqData
              DRA_rSR_WarningDisplay_WarningDisplayData: accessed-variable=rSR_WarningDisplay.WarningDisplayData
              DRA_rSR_WarningExtDisplay_WarningExtDisplayData: accessed-variable=rSR_WarningExtDisplay.WarningExtDisplayData
          data-send-points:
            19 x access:
              DWA_pSR_DLTControlMessageRequest_DLTControlMessageRequestData: accessed-variable=pSR_DLTControlMessageRequest.DLTControlMessageRequestData
              DWA_pSR_DLTMessageReadAck_DLTMessageReadAckData: accessed-variable=pSR_DLTMessageReadAck.DLTMessageReadAckData
              DSP_pSR_DiagResponse_DiagResponseData: accessed-variable=pSR_DiagResponse.DiagResponseData
              DWA_pSR_DisplayCurrentState_DisplayCurrentStateData: accessed-variable=pSR_DisplayCurrentState.DisplayCurrentStateData
              DWA_pSR_EmmcErrorNotifier_EmmcErrorNotifierData: accessed-variable=pSR_EmmcErrorNotifier.EmmcErrorNotifierData
              DSP_pSR_HealthDomainFatalError_HealthDomainFatalErrorData: accessed-variable=pSR_HealthDomainFatalError.HealthDomainFatalErrorData
              DSP_pSR_HealthDomainHeartbeat_HealthDomainHeartbeatData: accessed-variable=pSR_HealthDomainHeartbeat.HealthDomainHeartbeatData
              DSP_pSR_HealthDumpData_HealthDumpDataData: accessed-variable=pSR_HealthDumpData.HealthDumpDataData
              DSP_pSR_HealthDumpHdrInfo_HealthDumpHdrInfoData: accessed-variable=pSR_HealthDumpHdrInfo.HealthDumpHdrInfoData
              DSP_pSR_HealthEventRecord_HealthEventRecordData: accessed-variable=pSR_HealthEventRecord.HealthEventRecordData
              DWA_pSR_HudWarningStatus_HudWarningStatusData: accessed-variable=pSR_HudWarningStatus.HudWarningStatusData
              DSP_pSR_MainHMIReadyStatus_MainHMIReadyStatusData: accessed-variable=pSR_MainHMIReadyStatus.MainHMIReadyStatusData
              DSP_pSR_PowerExtendShutdownTime_PowerExtendShutdownTimeData: accessed-variable=pSR_PowerExtendShutdownTime.PowerExtendShutdownTimeData
              DSP_pSR_PowerKeepSystemAwake_PowerKeepSystemAwakeData: accessed-variable=pSR_PowerKeepSystemAwake.PowerKeepSystemAwakeData
              DWA_pSR_PowerSystemState_PowerSystemStateData: accessed-variable=pSR_PowerSystemState.PowerSystemStateData
              DSP_pSR_SafeHMIReadyStatus_SafeHMIReadyStatusData: accessed-variable=pSR_SafeHMIReadyStatus.SafeHMIReadyStatusData
              DSP_pSR_UpdateShortServiceResp_UpdateShortServiceRespData: accessed-variable=pSR_UpdateShortServiceResp.UpdateShortServiceRespData
              DWA_pSR_WarningDisplayAvailable_WarningDisplayAvailableData: accessed-variable=pSR_WarningDisplayAvailable.WarningDisplayAvailableData
              DWA_pSR_WarningStatus_WarningStatusData: accessed-variable=pSR_WarningStatus.WarningStatusData
          sync call OA_rCS_UclSystemCallbacks_ErrorNotification: operation=rCS_UclSystemCallbacks.ErrorNotification, timeout=0.0
          sync call OA_rCS_UclSystemCallbacks_LinkStatusChanged: operation=rCS_UclSystemCallbacks.LinkStatusChanged, timeout=0.0
        OnDre_UpdateLongServiceReq
          data-receive-point-by-arguments:
            25 x access:
              DRA_rSR_DLTControlMessageReponse_DLTControlMessageReponseData: accessed-variable=rSR_DLTControlMessageReponse.DLTControlMessageReponseData
              DRA_rSR_DLTMessageReadRequest_DLTMessageReadRequestData: accessed-variable=rSR_DLTMessageReadRequest.DLTMessageReadRequestData
              DRP_rSR_DiagDIDRequest_DiagDIDRequestData: accessed-variable=rSR_DiagDIDRequest.DiagDIDRequestData
              DRP_rSR_DiagIOCtrlRequest_DiagIOCtrlRequestData: accessed-variable=rSR_DiagIOCtrlRequest.DiagIOCtrlRequestData
              DRP_rSR_DiagRoutineRequest_DiagRoutineRequestData: accessed-variable=rSR_DiagRoutineRequest.DiagRoutineRequestData
              DRA_rSR_DisplaySetPower_DisplaySetPowerData: accessed-variable=rSR_DisplaySetPower.DisplaySetPowerData
              DRA_rSR_FRTT_Status_FRTT_StatusData: accessed-variable=rSR_FRTT_Status.FRTT_StatusData
              DRA_rSR_FastGaugeInfo_FastGaugeInfoData: accessed-variable=rSR_FastGaugeInfo.FastGaugeInfoData
              DRP_rSR_HealthDumpGetData_HealthDumpGetDataData: accessed-variable=rSR_HealthDumpGetData.HealthDumpGetDataData
              DRP_rSR_HealthDumpGetHdr_HealthDumpGetHdrData: accessed-variable=rSR_HealthDumpGetHdr.HealthDumpGetHdrData
              DRA_rSR_HudWarningDisplay_HudWarningDisplayData: accessed-variable=rSR_HudWarningDisplay.HudWarningDisplayData
              DRP_rSR_IgnState_IgnStateData: accessed-variable=rSR_IgnState.IgnStateData
              DRA_rSR_IlluminationData_IlluminationDataData: accessed-variable=rSR_IlluminationData.IlluminationDataData
              DRA_rSR_PowerSystemStateReqChange_PowerSystemStateReqChangeData: accessed-variable=rSR_PowerSystemStateReqChange.PowerSystemStateReqChangeData
              DRA_rSR_RTT_Icon_RTT_IconData: accessed-variable=rSR_RTT_Icon.RTT_IconData
              DRA_rSR_RTT_Status_RTT_StatusData: accessed-variable=rSR_RTT_Status.RTT_StatusData
              DRA_rSR_RTT_Toggle_RTT_ToggleData: accessed-variable=rSR_RTT_Toggle.RTT_ToggleData
              DRA_rSR_ShiftPosIndStatus_ShiftPosIndStatusData: accessed-variable=rSR_ShiftPosIndStatus.ShiftPosIndStatusData
              DRA_rSR_SlowGaugeInfo_SlowGaugeInfoData: accessed-variable=rSR_SlowGaugeInfo.SlowGaugeInfoData
              DRA_rSR_TT_Status_TT_StatusData: accessed-variable=rSR_TT_Status.TT_StatusData
              DRA_rSR_TpmsWarningData_TpmsWarningDataData: accessed-variable=rSR_TpmsWarningData.TpmsWarningDataData
              DRP_rSR_UpdateLongServiceReq_UpdateLongServiceReqData: accessed-variable=rSR_UpdateLongServiceReq.UpdateLongServiceReqData
              DRP_rSR_UpdateShortServiceReq_UpdateShortServiceReqData: accessed-variable=rSR_UpdateShortServiceReq.UpdateShortServiceReqData
              DRA_rSR_WarningDisplay_WarningDisplayData: accessed-variable=rSR_WarningDisplay.WarningDisplayData
              DRA_rSR_WarningExtDisplay_WarningExtDisplayData: accessed-variable=rSR_WarningExtDisplay.WarningExtDisplayData
          data-send-points:
            19 x access:
              DWA_pSR_DLTControlMessageRequest_DLTControlMessageRequestData: accessed-variable=pSR_DLTControlMessageRequest.DLTControlMessageRequestData
              DWA_pSR_DLTMessageReadAck_DLTMessageReadAckData: accessed-variable=pSR_DLTMessageReadAck.DLTMessageReadAckData
              DSP_pSR_DiagResponse_DiagResponseData: accessed-variable=pSR_DiagResponse.DiagResponseData
              DWA_pSR_DisplayCurrentState_DisplayCurrentStateData: accessed-variable=pSR_DisplayCurrentState.DisplayCurrentStateData
              DWA_pSR_EmmcErrorNotifier_EmmcErrorNotifierData: accessed-variable=pSR_EmmcErrorNotifier.EmmcErrorNotifierData
              DSP_pSR_HealthDomainFatalError_HealthDomainFatalErrorData: accessed-variable=pSR_HealthDomainFatalError.HealthDomainFatalErrorData
              DSP_pSR_HealthDomainHeartbeat_HealthDomainHeartbeatData: accessed-variable=pSR_HealthDomainHeartbeat.HealthDomainHeartbeatData
              DSP_pSR_HealthDumpData_HealthDumpDataData: accessed-variable=pSR_HealthDumpData.HealthDumpDataData
              DSP_pSR_HealthDumpHdrInfo_HealthDumpHdrInfoData: accessed-variable=pSR_HealthDumpHdrInfo.HealthDumpHdrInfoData
              DSP_pSR_HealthEventRecord_HealthEventRecordData: accessed-variable=pSR_HealthEventRecord.HealthEventRecordData
              DWA_pSR_HudWarningStatus_HudWarningStatusData: accessed-variable=pSR_HudWarningStatus.HudWarningStatusData
              DSP_pSR_MainHMIReadyStatus_MainHMIReadyStatusData: accessed-variable=pSR_MainHMIReadyStatus.MainHMIReadyStatusData
              DSP_pSR_PowerExtendShutdownTime_PowerExtendShutdownTimeData: accessed-variable=pSR_PowerExtendShutdownTime.PowerExtendShutdownTimeData
              DSP_pSR_PowerKeepSystemAwake_PowerKeepSystemAwakeData: accessed-variable=pSR_PowerKeepSystemAwake.PowerKeepSystemAwakeData
              DWA_pSR_PowerSystemState_PowerSystemStateData: accessed-variable=pSR_PowerSystemState.PowerSystemStateData
              DSP_pSR_SafeHMIReadyStatus_SafeHMIReadyStatusData: accessed-variable=pSR_SafeHMIReadyStatus.SafeHMIReadyStatusData
              DSP_pSR_UpdateShortServiceResp_UpdateShortServiceRespData: accessed-variable=pSR_UpdateShortServiceResp.UpdateShortServiceRespData
              DWA_pSR_WarningDisplayAvailable_WarningDisplayAvailableData: accessed-variable=pSR_WarningDisplayAvailable.WarningDisplayAvailableData
              DWA_pSR_WarningStatus_WarningStatusData: accessed-variable=pSR_WarningStatus.WarningStatusData
          sync call OA_rCS_UclSystemCallbacks_ErrorNotification: operation=rCS_UclSystemCallbacks.ErrorNotification, timeout=0.0
          sync call OA_rCS_UclSystemCallbacks_LinkStatusChanged: operation=rCS_UclSystemCallbacks.LinkStatusChanged, timeout=0.0
        OnDre_UpdateShortServiceReq
          data-receive-point-by-arguments:
            25 x access:
              DRA_rSR_DLTControlMessageReponse_DLTControlMessageReponseData: accessed-variable=rSR_DLTControlMessageReponse.DLTControlMessageReponseData
              DRA_rSR_DLTMessageReadRequest_DLTMessageReadRequestData: accessed-variable=rSR_DLTMessageReadRequest.DLTMessageReadRequestData
              DRP_rSR_DiagDIDRequest_DiagDIDRequestData: accessed-variable=rSR_DiagDIDRequest.DiagDIDRequestData
              DRP_rSR_DiagIOCtrlRequest_DiagIOCtrlRequestData: accessed-variable=rSR_DiagIOCtrlRequest.DiagIOCtrlRequestData
              DRP_rSR_DiagRoutineRequest_DiagRoutineRequestData: accessed-variable=rSR_DiagRoutineRequest.DiagRoutineRequestData
              DRA_rSR_DisplaySetPower_DisplaySetPowerData: accessed-variable=rSR_DisplaySetPower.DisplaySetPowerData
              DRA_rSR_FRTT_Status_FRTT_StatusData: accessed-variable=rSR_FRTT_Status.FRTT_StatusData
              DRA_rSR_FastGaugeInfo_FastGaugeInfoData: accessed-variable=rSR_FastGaugeInfo.FastGaugeInfoData
              DRP_rSR_HealthDumpGetData_HealthDumpGetDataData: accessed-variable=rSR_HealthDumpGetData.HealthDumpGetDataData
              DRP_rSR_HealthDumpGetHdr_HealthDumpGetHdrData: accessed-variable=rSR_HealthDumpGetHdr.HealthDumpGetHdrData
              DRA_rSR_HudWarningDisplay_HudWarningDisplayData: accessed-variable=rSR_HudWarningDisplay.HudWarningDisplayData
              DRP_rSR_IgnState_IgnStateData: accessed-variable=rSR_IgnState.IgnStateData
              DRA_rSR_IlluminationData_IlluminationDataData: accessed-variable=rSR_IlluminationData.IlluminationDataData
              DRA_rSR_PowerSystemStateReqChange_PowerSystemStateReqChangeData: accessed-variable=rSR_PowerSystemStateReqChange.PowerSystemStateReqChangeData
              DRA_rSR_RTT_Icon_RTT_IconData: accessed-variable=rSR_RTT_Icon.RTT_IconData
              DRA_rSR_RTT_Status_RTT_StatusData: accessed-variable=rSR_RTT_Status.RTT_StatusData
              DRA_rSR_RTT_Toggle_RTT_ToggleData: accessed-variable=rSR_RTT_Toggle.RTT_ToggleData
              DRA_rSR_ShiftPosIndStatus_ShiftPosIndStatusData: accessed-variable=rSR_ShiftPosIndStatus.ShiftPosIndStatusData
              DRA_rSR_SlowGaugeInfo_SlowGaugeInfoData: accessed-variable=rSR_SlowGaugeInfo.SlowGaugeInfoData
              DRA_rSR_TT_Status_TT_StatusData: accessed-variable=rSR_TT_Status.TT_StatusData
              DRA_rSR_TpmsWarningData_TpmsWarningDataData: accessed-variable=rSR_TpmsWarningData.TpmsWarningDataData
              DRP_rSR_UpdateLongServiceReq_UpdateLongServiceReqData: accessed-variable=rSR_UpdateLongServiceReq.UpdateLongServiceReqData
              DRP_rSR_UpdateShortServiceReq_UpdateShortServiceReqData: accessed-variable=rSR_UpdateShortServiceReq.UpdateShortServiceReqData
              DRA_rSR_WarningDisplay_WarningDisplayData: accessed-variable=rSR_WarningDisplay.WarningDisplayData
              DRA_rSR_WarningExtDisplay_WarningExtDisplayData: accessed-variable=rSR_WarningExtDisplay.WarningExtDisplayData
          data-send-points:
            19 x access:
              DWA_pSR_DLTControlMessageRequest_DLTControlMessageRequestData: accessed-variable=pSR_DLTControlMessageRequest.DLTControlMessageRequestData
              DWA_pSR_DLTMessageReadAck_DLTMessageReadAckData: accessed-variable=pSR_DLTMessageReadAck.DLTMessageReadAckData
              DSP_pSR_DiagResponse_DiagResponseData: accessed-variable=pSR_DiagResponse.DiagResponseData
              DWA_pSR_DisplayCurrentState_DisplayCurrentStateData: accessed-variable=pSR_DisplayCurrentState.DisplayCurrentStateData
              DWA_pSR_EmmcErrorNotifier_EmmcErrorNotifierData: accessed-variable=pSR_EmmcErrorNotifier.EmmcErrorNotifierData
              DSP_pSR_HealthDomainFatalError_HealthDomainFatalErrorData: accessed-variable=pSR_HealthDomainFatalError.HealthDomainFatalErrorData
              DSP_pSR_HealthDomainHeartbeat_HealthDomainHeartbeatData: accessed-variable=pSR_HealthDomainHeartbeat.HealthDomainHeartbeatData
              DSP_pSR_HealthDumpData_HealthDumpDataData: accessed-variable=pSR_HealthDumpData.HealthDumpDataData
              DSP_pSR_HealthDumpHdrInfo_HealthDumpHdrInfoData: accessed-variable=pSR_HealthDumpHdrInfo.HealthDumpHdrInfoData
              DSP_pSR_HealthEventRecord_HealthEventRecordData: accessed-variable=pSR_HealthEventRecord.HealthEventRecordData
              DWA_pSR_HudWarningStatus_HudWarningStatusData: accessed-variable=pSR_HudWarningStatus.HudWarningStatusData
              DSP_pSR_MainHMIReadyStatus_MainHMIReadyStatusData: accessed-variable=pSR_MainHMIReadyStatus.MainHMIReadyStatusData
              DSP_pSR_PowerExtendShutdownTime_PowerExtendShutdownTimeData: accessed-variable=pSR_PowerExtendShutdownTime.PowerExtendShutdownTimeData
              DSP_pSR_PowerKeepSystemAwake_PowerKeepSystemAwakeData: accessed-variable=pSR_PowerKeepSystemAwake.PowerKeepSystemAwakeData
              DWA_pSR_PowerSystemState_PowerSystemStateData: accessed-variable=pSR_PowerSystemState.PowerSystemStateData
              DSP_pSR_SafeHMIReadyStatus_SafeHMIReadyStatusData: accessed-variable=pSR_SafeHMIReadyStatus.SafeHMIReadyStatusData
              DSP_pSR_UpdateShortServiceResp_UpdateShortServiceRespData: accessed-variable=pSR_UpdateShortServiceResp.UpdateShortServiceRespData
              DWA_pSR_WarningDisplayAvailable_WarningDisplayAvailableData: accessed-variable=pSR_WarningDisplayAvailable.WarningDisplayAvailableData
              DWA_pSR_WarningStatus_WarningStatusData: accessed-variable=pSR_WarningStatus.WarningStatusData
          sync call OA_rCS_UclSystemCallbacks_ErrorNotification: operation=rCS_UclSystemCallbacks.ErrorNotification, timeout=0.0
          sync call OA_rCS_UclSystemCallbacks_LinkStatusChanged: operation=rCS_UclSystemCallbacks.LinkStatusChanged, timeout=0.0
        OnDre_WarningDisplay
          data-receive-point-by-arguments:
            25 x access:
              DRA_rSR_DLTControlMessageReponse_DLTControlMessageReponseData: accessed-variable=rSR_DLTControlMessageReponse.DLTControlMessageReponseData
              DRA_rSR_DLTMessageReadRequest_DLTMessageReadRequestData: accessed-variable=rSR_DLTMessageReadRequest.DLTMessageReadRequestData
              DRP_rSR_DiagDIDRequest_DiagDIDRequestData: accessed-variable=rSR_DiagDIDRequest.DiagDIDRequestData
              DRP_rSR_DiagIOCtrlRequest_DiagIOCtrlRequestData: accessed-variable=rSR_DiagIOCtrlRequest.DiagIOCtrlRequestData
              DRP_rSR_DiagRoutineRequest_DiagRoutineRequestData: accessed-variable=rSR_DiagRoutineRequest.DiagRoutineRequestData
              DRA_rSR_DisplaySetPower_DisplaySetPowerData: accessed-variable=rSR_DisplaySetPower.DisplaySetPowerData
              DRA_rSR_FRTT_Status_FRTT_StatusData: accessed-variable=rSR_FRTT_Status.FRTT_StatusData
              DRA_rSR_FastGaugeInfo_FastGaugeInfoData: accessed-variable=rSR_FastGaugeInfo.FastGaugeInfoData
              DRP_rSR_HealthDumpGetData_HealthDumpGetDataData: accessed-variable=rSR_HealthDumpGetData.HealthDumpGetDataData
              DRP_rSR_HealthDumpGetHdr_HealthDumpGetHdrData: accessed-variable=rSR_HealthDumpGetHdr.HealthDumpGetHdrData
              DRA_rSR_HudWarningDisplay_HudWarningDisplayData: accessed-variable=rSR_HudWarningDisplay.HudWarningDisplayData
              DRP_rSR_IgnState_IgnStateData: accessed-variable=rSR_IgnState.IgnStateData
              DRA_rSR_IlluminationData_IlluminationDataData: accessed-variable=rSR_IlluminationData.IlluminationDataData
              DRA_rSR_PowerSystemStateReqChange_PowerSystemStateReqChangeData: accessed-variable=rSR_PowerSystemStateReqChange.PowerSystemStateReqChangeData
              DRA_rSR_RTT_Icon_RTT_IconData: accessed-variable=rSR_RTT_Icon.RTT_IconData
              DRA_rSR_RTT_Status_RTT_StatusData: accessed-variable=rSR_RTT_Status.RTT_StatusData
              DRA_rSR_RTT_Toggle_RTT_ToggleData: accessed-variable=rSR_RTT_Toggle.RTT_ToggleData
              DRA_rSR_ShiftPosIndStatus_ShiftPosIndStatusData: accessed-variable=rSR_ShiftPosIndStatus.ShiftPosIndStatusData
              DRA_rSR_SlowGaugeInfo_SlowGaugeInfoData: accessed-variable=rSR_SlowGaugeInfo.SlowGaugeInfoData
              DRA_rSR_TT_Status_TT_StatusData: accessed-variable=rSR_TT_Status.TT_StatusData
              DRA_rSR_TpmsWarningData_TpmsWarningDataData: accessed-variable=rSR_TpmsWarningData.TpmsWarningDataData
              DRP_rSR_UpdateLongServiceReq_UpdateLongServiceReqData: accessed-variable=rSR_UpdateLongServiceReq.UpdateLongServiceReqData
              DRP_rSR_UpdateShortServiceReq_UpdateShortServiceReqData: accessed-variable=rSR_UpdateShortServiceReq.UpdateShortServiceReqData
              DRA_rSR_WarningDisplay_WarningDisplayData: accessed-variable=rSR_WarningDisplay.WarningDisplayData
              DRA_rSR_WarningExtDisplay_WarningExtDisplayData: accessed-variable=rSR_WarningExtDisplay.WarningExtDisplayData
          data-send-points:
            19 x access:
              DWA_pSR_DLTControlMessageRequest_DLTControlMessageRequestData: accessed-variable=pSR_DLTControlMessageRequest.DLTControlMessageRequestData
              DWA_pSR_DLTMessageReadAck_DLTMessageReadAckData: accessed-variable=pSR_DLTMessageReadAck.DLTMessageReadAckData
              DSP_pSR_DiagResponse_DiagResponseData: accessed-variable=pSR_DiagResponse.DiagResponseData
              DWA_pSR_DisplayCurrentState_DisplayCurrentStateData: accessed-variable=pSR_DisplayCurrentState.DisplayCurrentStateData
              DWA_pSR_EmmcErrorNotifier_EmmcErrorNotifierData: accessed-variable=pSR_EmmcErrorNotifier.EmmcErrorNotifierData
              DSP_pSR_HealthDomainFatalError_HealthDomainFatalErrorData: accessed-variable=pSR_HealthDomainFatalError.HealthDomainFatalErrorData
              DSP_pSR_HealthDomainHeartbeat_HealthDomainHeartbeatData: accessed-variable=pSR_HealthDomainHeartbeat.HealthDomainHeartbeatData
              DSP_pSR_HealthDumpData_HealthDumpDataData: accessed-variable=pSR_HealthDumpData.HealthDumpDataData
              DSP_pSR_HealthDumpHdrInfo_HealthDumpHdrInfoData: accessed-variable=pSR_HealthDumpHdrInfo.HealthDumpHdrInfoData
              DSP_pSR_HealthEventRecord_HealthEventRecordData: accessed-variable=pSR_HealthEventRecord.HealthEventRecordData
              DWA_pSR_HudWarningStatus_HudWarningStatusData: accessed-variable=pSR_HudWarningStatus.HudWarningStatusData
              DSP_pSR_MainHMIReadyStatus_MainHMIReadyStatusData: accessed-variable=pSR_MainHMIReadyStatus.MainHMIReadyStatusData
              DSP_pSR_PowerExtendShutdownTime_PowerExtendShutdownTimeData: accessed-variable=pSR_PowerExtendShutdownTime.PowerExtendShutdownTimeData
              DSP_pSR_PowerKeepSystemAwake_PowerKeepSystemAwakeData: accessed-variable=pSR_PowerKeepSystemAwake.PowerKeepSystemAwakeData
              DWA_pSR_PowerSystemState_PowerSystemStateData: accessed-variable=pSR_PowerSystemState.PowerSystemStateData
              DSP_pSR_SafeHMIReadyStatus_SafeHMIReadyStatusData: accessed-variable=pSR_SafeHMIReadyStatus.SafeHMIReadyStatusData
              DSP_pSR_UpdateShortServiceResp_UpdateShortServiceRespData: accessed-variable=pSR_UpdateShortServiceResp.UpdateShortServiceRespData
              DWA_pSR_WarningDisplayAvailable_WarningDisplayAvailableData: accessed-variable=pSR_WarningDisplayAvailable.WarningDisplayAvailableData
              DWA_pSR_WarningStatus_WarningStatusData: accessed-variable=pSR_WarningStatus.WarningStatusData
          sync call OA_rCS_UclSystemCallbacks_ErrorNotification: operation=rCS_UclSystemCallbacks.ErrorNotification, timeout=0.0
          sync call OA_rCS_UclSystemCallbacks_LinkStatusChanged: operation=rCS_UclSystemCallbacks.LinkStatusChanged, timeout=0.0
        OnDre_WarningExtDisplay
          data-receive-point-by-arguments:
            25 x access:
              DRA_rSR_DLTControlMessageReponse_DLTControlMessageReponseData: accessed-variable=rSR_DLTControlMessageReponse.DLTControlMessageReponseData
              DRA_rSR_DLTMessageReadRequest_DLTMessageReadRequestData: accessed-variable=rSR_DLTMessageReadRequest.DLTMessageReadRequestData
              DRP_rSR_DiagDIDRequest_DiagDIDRequestData: accessed-variable=rSR_DiagDIDRequest.DiagDIDRequestData
              DRP_rSR_DiagIOCtrlRequest_DiagIOCtrlRequestData: accessed-variable=rSR_DiagIOCtrlRequest.DiagIOCtrlRequestData
              DRP_rSR_DiagRoutineRequest_DiagRoutineRequestData: accessed-variable=rSR_DiagRoutineRequest.DiagRoutineRequestData
              DRA_rSR_DisplaySetPower_DisplaySetPowerData: accessed-variable=rSR_DisplaySetPower.DisplaySetPowerData
              DRA_rSR_FRTT_Status_FRTT_StatusData: accessed-variable=rSR_FRTT_Status.FRTT_StatusData
              DRA_rSR_FastGaugeInfo_FastGaugeInfoData: accessed-variable=rSR_FastGaugeInfo.FastGaugeInfoData
              DRP_rSR_HealthDumpGetData_HealthDumpGetDataData: accessed-variable=rSR_HealthDumpGetData.HealthDumpGetDataData
              DRP_rSR_HealthDumpGetHdr_HealthDumpGetHdrData: accessed-variable=rSR_HealthDumpGetHdr.HealthDumpGetHdrData
              DRA_rSR_HudWarningDisplay_HudWarningDisplayData: accessed-variable=rSR_HudWarningDisplay.HudWarningDisplayData
              DRP_rSR_IgnState_IgnStateData: accessed-variable=rSR_IgnState.IgnStateData
              DRA_rSR_IlluminationData_IlluminationDataData: accessed-variable=rSR_IlluminationData.IlluminationDataData
              DRA_rSR_PowerSystemStateReqChange_PowerSystemStateReqChangeData: accessed-variable=rSR_PowerSystemStateReqChange.PowerSystemStateReqChangeData
              DRA_rSR_RTT_Icon_RTT_IconData: accessed-variable=rSR_RTT_Icon.RTT_IconData
              DRA_rSR_RTT_Status_RTT_StatusData: accessed-variable=rSR_RTT_Status.RTT_StatusData
              DRA_rSR_RTT_Toggle_RTT_ToggleData: accessed-variable=rSR_RTT_Toggle.RTT_ToggleData
              DRA_rSR_ShiftPosIndStatus_ShiftPosIndStatusData: accessed-variable=rSR_ShiftPosIndStatus.ShiftPosIndStatusData
              DRA_rSR_SlowGaugeInfo_SlowGaugeInfoData: accessed-variable=rSR_SlowGaugeInfo.SlowGaugeInfoData
              DRA_rSR_TT_Status_TT_StatusData: accessed-variable=rSR_TT_Status.TT_StatusData
              DRA_rSR_TpmsWarningData_TpmsWarningDataData: accessed-variable=rSR_TpmsWarningData.TpmsWarningDataData
              DRP_rSR_UpdateLongServiceReq_UpdateLongServiceReqData: accessed-variable=rSR_UpdateLongServiceReq.UpdateLongServiceReqData
              DRP_rSR_UpdateShortServiceReq_UpdateShortServiceReqData: accessed-variable=rSR_UpdateShortServiceReq.UpdateShortServiceReqData
              DRA_rSR_WarningDisplay_WarningDisplayData: accessed-variable=rSR_WarningDisplay.WarningDisplayData
              DRA_rSR_WarningExtDisplay_WarningExtDisplayData: accessed-variable=rSR_WarningExtDisplay.WarningExtDisplayData
          data-send-points:
            19 x access:
              DWA_pSR_DLTControlMessageRequest_DLTControlMessageRequestData: accessed-variable=pSR_DLTControlMessageRequest.DLTControlMessageRequestData
              DWA_pSR_DLTMessageReadAck_DLTMessageReadAckData: accessed-variable=pSR_DLTMessageReadAck.DLTMessageReadAckData
              DSP_pSR_DiagResponse_DiagResponseData: accessed-variable=pSR_DiagResponse.DiagResponseData
              DWA_pSR_DisplayCurrentState_DisplayCurrentStateData: accessed-variable=pSR_DisplayCurrentState.DisplayCurrentStateData
              DWA_pSR_EmmcErrorNotifier_EmmcErrorNotifierData: accessed-variable=pSR_EmmcErrorNotifier.EmmcErrorNotifierData
              DSP_pSR_HealthDomainFatalError_HealthDomainFatalErrorData: accessed-variable=pSR_HealthDomainFatalError.HealthDomainFatalErrorData
              DSP_pSR_HealthDomainHeartbeat_HealthDomainHeartbeatData: accessed-variable=pSR_HealthDomainHeartbeat.HealthDomainHeartbeatData
              DSP_pSR_HealthDumpData_HealthDumpDataData: accessed-variable=pSR_HealthDumpData.HealthDumpDataData
              DSP_pSR_HealthDumpHdrInfo_HealthDumpHdrInfoData: accessed-variable=pSR_HealthDumpHdrInfo.HealthDumpHdrInfoData
              DSP_pSR_HealthEventRecord_HealthEventRecordData: accessed-variable=pSR_HealthEventRecord.HealthEventRecordData
              DWA_pSR_HudWarningStatus_HudWarningStatusData: accessed-variable=pSR_HudWarningStatus.HudWarningStatusData
              DSP_pSR_MainHMIReadyStatus_MainHMIReadyStatusData: accessed-variable=pSR_MainHMIReadyStatus.MainHMIReadyStatusData
              DSP_pSR_PowerExtendShutdownTime_PowerExtendShutdownTimeData: accessed-variable=pSR_PowerExtendShutdownTime.PowerExtendShutdownTimeData
              DSP_pSR_PowerKeepSystemAwake_PowerKeepSystemAwakeData: accessed-variable=pSR_PowerKeepSystemAwake.PowerKeepSystemAwakeData
              DWA_pSR_PowerSystemState_PowerSystemStateData: accessed-variable=pSR_PowerSystemState.PowerSystemStateData
              DSP_pSR_SafeHMIReadyStatus_SafeHMIReadyStatusData: accessed-variable=pSR_SafeHMIReadyStatus.SafeHMIReadyStatusData
              DSP_pSR_UpdateShortServiceResp_UpdateShortServiceRespData: accessed-variable=pSR_UpdateShortServiceResp.UpdateShortServiceRespData
              DWA_pSR_WarningDisplayAvailable_WarningDisplayAvailableData: accessed-variable=pSR_WarningDisplayAvailable.WarningDisplayAvailableData
              DWA_pSR_WarningStatus_WarningStatusData: accessed-variable=pSR_WarningStatus.WarningStatusData
          sync call OA_rCS_UclSystemCallbacks_ErrorNotification: operation=rCS_UclSystemCallbacks.ErrorNotification, timeout=0.0
          sync call OA_rCS_UclSystemCallbacks_LinkStatusChanged: operation=rCS_UclSystemCallbacks.LinkStatusChanged, timeout=0.0
  25 x constant specification:
    UclProxyCddDLTControlMessageRequestDataValue0: value-spec={short-label=UclProxyCddDLTControlMessageRequestDataValue0, fields=UclProxyCddDLTControlMessageRequestDataValue_0:0}
    UclProxyCddDLTMessageReadAckDataValue0: value-spec={short-label=UclProxyCddDLTMessageReadAckDataValue0, fields=UclProxyCddDLTMessageReadAckDataValue_0:0}
    UclProxyCddDisplayCurrentStateDataValue0: value-spec={short-label=UclProxyCddDisplayCurrentStateDataValue0, fields=[UclProxyCddDisplayCurrentStateDataValue_0:0, UclProxyCddDisplayCurrentStateDataValue_1:0]}
    UclProxyCddEmmcErrorNotifierDataValue0: value-spec={short-label=UclProxyCddEmmcErrorNotifierDataValue0, fields=UclProxyCddEmmcErrorNotifierDataValue_0:0}
    UclProxyCddHudWarningStatusDataValue0: value-spec={short-label=UclProxyCddHudWarningStatusDataValue0, fields=[UclProxyCddHudWarningStatusDataValue_0:0, UclProxyCddHudWarningStatusDataValue_1:0, UclProxyCddHudWarningStatusDataValue_2:[UclProxyCdddynData0Value:0, UclProxyCdddynData1Value:0, UclProxyCdddynData2Value:0, UclProxyCdddynData3Value:0, UclProxyCdddynData4Value:0, UclProxyCdddynData5Value:0, UclProxyCdddynData6Value:0, UclProxyCdddynData7Value:0, UclProxyCdddynData8Value:0, UclProxyCdddynData9Value:0]]}
    UclProxyCddPowerSystemStateDataValue0: value-spec={short-label=UclProxyCddPowerSystemStateDataValue0, fields=[UclProxyCddPowerSystemStateDataValue_0:0, UclProxyCddPowerSystemStateDataValue_1:0]}
    UclProxyCddWarningDisplayAvailableDataValue0: value-spec={short-label=UclProxyCddWarningDisplayAvailableDataValue0, fields=UclProxyCddWarningDisplayAvailableDataValue_0:0}
    UclProxyCddWarningStatusDataValue0: value-spec={short-label=UclProxyCddWarningStatusDataValue0, fields=[UclProxyCddWarningStatusDataValue_0:0, UclProxyCddWarningStatusDataValue_1:0, UclProxyCddWarningStatusDataValue_2:[UclProxyCdddynData0Value:0, UclProxyCdddynData1Value:0, UclProxyCdddynData2Value:0, UclProxyCdddynData3Value:0, UclProxyCdddynData4Value:0, UclProxyCdddynData5Value:0, UclProxyCdddynData6Value:0, UclProxyCdddynData7Value:0, UclProxyCdddynData8Value:0, UclProxyCdddynData9Value:0]]}
    UclProxyCddDLTControlMessageReponseDataValue0: value-spec={short-label=UclProxyCddDLTControlMessageReponseDataValue0, fields=UclProxyCddDLTControlMessageReponseDataValue_0:0}
    UclProxyCddDLTMessageReadRequestDataValue0: value-spec={short-label=UclProxyCddDLTMessageReadRequestDataValue0, fields=UclProxyCddDLTMessageReadRequestDataValue_0:0}
    UclProxyCddDisplaySetPowerDataValue0: value-spec={short-label=UclProxyCddDisplaySetPowerDataValue0, fields=[UclProxyCddDisplaySetPowerDataValue_0:0, UclProxyCddDisplaySetPowerDataValue_1:0]}
    UclProxyCddFRTT_StatusDataValue0: value-spec={short-label=UclProxyCddFRTT_StatusDataValue0, fields=UclProxyCddFRTT_StatusDataValue_0:[UclProxyCddmask0Value:0, UclProxyCddmask1Value:0]}
    UclProxyCddFastGaugeInfoDataValue0: value-spec={short-label=UclProxyCddFastGaugeInfoDataValue0, fields={short-label=UclProxyCddFastGaugeInfoDataValue_0, fields=[UclProxyCddgaugeInfoValue_0:0, UclProxyCddgaugeInfoValue_1:0, UclProxyCddgaugeInfoValue_2:0, UclProxyCddgaugeInfoValue_3:0, UclProxyCddgaugeInfoValue_4:0]}}
    UclProxyCddHudWarningDisplayDataValue0: value-spec={short-label=UclProxyCddHudWarningDisplayDataValue0, fields=[UclProxyCddHudWarningDisplayDataValue_0:0, UclProxyCddHudWarningDisplayDataValue_1:0, UclProxyCddHudWarningDisplayDataValue_2:[UclProxyCdddynData0Value:0, UclProxyCdddynData1Value:0, UclProxyCdddynData2Value:0, UclProxyCdddynData3Value:0, UclProxyCdddynData4Value:0, UclProxyCdddynData5Value:0, UclProxyCdddynData6Value:0, UclProxyCdddynData7Value:0]]}
    UclProxyCddIlluminationDataDataValue0: value-spec={short-label=UclProxyCddIlluminationDataDataValue0, fields=[UclProxyCddIlluminationDataDataValue_0:0, UclProxyCddIlluminationDataDataValue_1:0, UclProxyCddIlluminationDataDataValue_2:0, UclProxyCddIlluminationDataDataValue_3:0]}
    UclProxyCddPowerSystemStateReqChangeDataValue0: value-spec={short-label=UclProxyCddPowerSystemStateReqChangeDataValue0, fields=[UclProxyCddPowerSystemStateReqChangeDataValue_0:0, UclProxyCddPowerSystemStateReqChangeDataValue_1:0]}
    UclProxyCddRTT_IconDataValue0: value-spec={short-label=UclProxyCddRTT_IconDataValue0, fields=UclProxyCddRTT_IconDataValue_0:[UclProxyCddicon0Value:0, UclProxyCddicon1Value:0]}
    UclProxyCddRTT_StatusDataValue0: value-spec={short-label=UclProxyCddRTT_StatusDataValue0, fields=UclProxyCddRTT_StatusDataValue_0:[UclProxyCddmask0Value:0, UclProxyCddmask1Value:0]}
    UclProxyCddRTT_ToggleDataValue0: value-spec={short-label=UclProxyCddRTT_ToggleDataValue0, fields=[UclProxyCddRTT_ToggleDataValue_0:0, UclProxyCddRTT_ToggleDataValue_1:0]}
    UclProxyCddShiftPosIndStatusDataValue0: value-spec={short-label=UclProxyCddShiftPosIndStatusDataValue0, fields={short-label=UclProxyCddShiftPosIndStatusDataValue_0, fields=[UclProxyCddstatusValue_0:0, UclProxyCddstatusValue_1:0, UclProxyCddstatusValue_2:0, UclProxyCddstatusValue_3:0, UclProxyCddstatusValue_4:0, UclProxyCddstatusValue_5:0]}}
    UclProxyCddSlowGaugeInfoDataValue0: value-spec={short-label=UclProxyCddSlowGaugeInfoDataValue0, fields={short-label=UclProxyCddSlowGaugeInfoDataValue_0, fields=[UclProxyCddgaugeInfoValue_0:0, UclProxyCddgaugeInfoValue_1:0, UclProxyCddgaugeInfoValue_2:0, UclProxyCddgaugeInfoValue_3:0, UclProxyCddgaugeInfoValue_4:0]}}
    UclProxyCddTT_StatusDataValue0: value-spec={short-label=UclProxyCddTT_StatusDataValue0, fields=UclProxyCddTT_StatusDataValue_0:[UclProxyCddmask0Value:0, UclProxyCddmask1Value:0, UclProxyCddmask2Value:0, UclProxyCddmask3Value:0, UclProxyCddmask4Value:0, UclProxyCddmask5Value:0, UclProxyCddmask6Value:0, UclProxyCddmask7Value:0, UclProxyCddmask8Value:0, UclProxyCddmask9Value:0, UclProxyCddmask10Value:0, UclProxyCddmask11Value:0, UclProxyCddmask12Value:0, UclProxyCddmask13Value:0, UclProxyCddmask14Value:0]}
    UclProxyCddTpmsWarningDataDataValue0: value-spec={short-label=UclProxyCddTpmsWarningDataDataValue0, fields=UclProxyCddTpmsWarningDataDataValue_0:[UclProxyCddtpmsWarndata0Value:0, UclProxyCddtpmsWarndata1Value:0, UclProxyCddtpmsWarndata2Value:0, UclProxyCddtpmsWarndata3Value:0, UclProxyCddtpmsWarndata4Value:0]}
    UclProxyCddWarningDisplayDataValue0: value-spec={short-label=UclProxyCddWarningDisplayDataValue0, fields=[UclProxyCddWarningDisplayDataValue_0:0, UclProxyCddWarningDisplayDataValue_1:0, UclProxyCddWarningDisplayDataValue_2:[UclProxyCdddynData0Value:0, UclProxyCdddynData1Value:0, UclProxyCdddynData2Value:0, UclProxyCdddynData3Value:0, UclProxyCdddynData4Value:0, UclProxyCdddynData5Value:0, UclProxyCdddynData6Value:0, UclProxyCdddynData7Value:0]]}
    UclProxyCddWarningExtDisplayDataValue0: value-spec={short-label=UclProxyCddWarningExtDisplayDataValue0, fields=[UclProxyCddWarningExtDisplayDataValue_0:0, UclProxyCddWarningExtDisplayDataValue_1:0, UclProxyCddWarningExtDisplayDataValue_2:[UclProxyCdddynData0Value:0, UclProxyCdddynData1Value:0, UclProxyCdddynData2Value:0, UclProxyCdddynData3Value:0, UclProxyCdddynData4Value:0, UclProxyCdddynData5Value:0, UclProxyCdddynData6Value:0, UclProxyCdddynData7Value:0]]}
  swc implementation IMPL_UclProxyCdd: programming-language=C, behavior=IB_UclProxyCdd
    code-descriptors:
      code CodeDescriptor
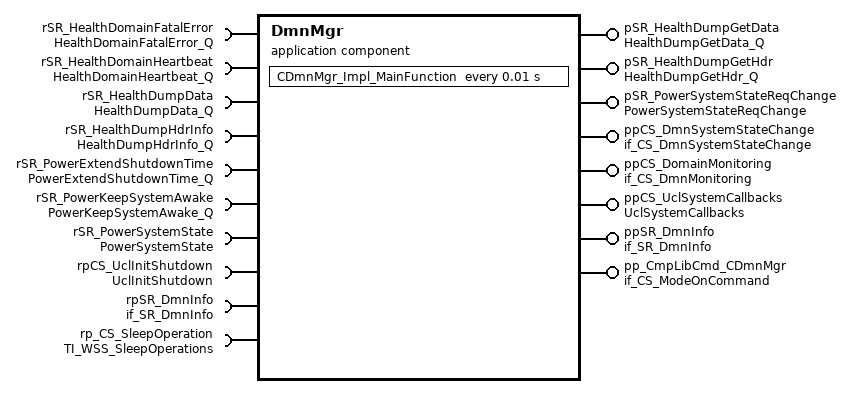
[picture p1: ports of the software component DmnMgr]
  application sw component type DmnMgr
    8 x provide port:
      pSR_HealthDumpGetData: queued-sender-com-spec=HealthDumpGetDataData, provided-interface=HealthDumpGetData_Q
      pSR_HealthDumpGetHdr: queued-sender-com-spec=HealthDumpGetHdrData, provided-interface=HealthDumpGetHdr_Q
      pSR_PowerSystemStateReqChange: nonqueued-sender-com-spec{data-element=PowerSystemStateReqChangeData, init-value=constant-reference=DmnMgrPowerSystemStateReqChangeDataValue0}, provided-interface=PowerSystemStateReqChange
      ppCS_DmnSystemStateChange: provided-interface=if_CS_DmnSystemStateChange
        provided-com-specs:
          operation=DmnSystemStateChangeReq, queue-length=1
          operation=DmnSystemStateChangeStatus, queue-length=1
      ppCS_DomainMonitoring: provided-com-specs=[{operation=StartDomainMonitoring, queue-length=1}, {operation=StopDomainMonitoring, queue-length=1}], provided-interface=if_CS_DmnMonitoring
      ppCS_UclSystemCallbacks: provided-com-specs=[{operation=ErrorNotification, queue-length=1}, {operation=LinkStatusChanged, queue-length=1}], provided-interface=UclSystemCallbacks
      ppSR_DmnInfo: nonqueued-sender-com-spec{data-element=SDmnStatus, init-value=constant-reference=DmnMgrSDmnStatusValue0}, provided-interface=if_SR_DmnInfo
      pp_CmpLibCmd_CDmnMgr: server-com-spec{operation=Impl_OnCommand, queue-length=1}, provided-interface=if_CS_ModeOnCommand
    10 x require port:
      rSR_HealthDomainFatalError: queued-receiver-com-spec{data-element=HealthDomainFatalErrorData, queue-length=2}, required-interface=HealthDomainFatalError_Q
      rSR_HealthDomainHeartbeat: queued-receiver-com-spec{data-element=HealthDomainHeartbeatData, queue-length=5}, required-interface=HealthDomainHeartbeat_Q
      rSR_HealthDumpData: queued-receiver-com-spec{data-element=HealthDumpDataData, queue-length=1}, required-interface=HealthDumpData_Q
      rSR_HealthDumpHdrInfo: queued-receiver-com-spec{data-element=HealthDumpHdrInfoData, queue-length=1}, required-interface=HealthDumpHdrInfo_Q
      rSR_PowerExtendShutdownTime: queued-receiver-com-spec{data-element=PowerExtendShutdownTimeData, queue-length=5}, required-interface=PowerExtendShutdownTime_Q
      rSR_PowerKeepSystemAwake: queued-receiver-com-spec{data-element=PowerKeepSystemAwakeData, queue-length=5}, required-interface=PowerKeepSystemAwake_Q
      rSR_PowerSystemState: nonqueued-receiver-com-spec{data-element=PowerSystemStateData, init-value=constant-reference=DmnMgrPowerSystemStateDataValue0}, required-interface=PowerSystemState
      rpCS_UclInitShutdown: required-interface=UclInitShutdown
      rpSR_DmnInfo: nonqueued-receiver-com-spec{data-element=SDmnStatus, init-value=constant-reference=DmnMgrSDmnStatusValue0}, required-interface=if_SR_DmnInfo
      rp_CS_SleepOperation: required-interface=TI_WSS_SleepOperations
    behavior IB_DmnMgr
      timing event TECDmnMgr_Impl_MainFunction: start-on-event=CDmnMgr_Impl_MainFunction, period=0.01
      5 x operation invoked event:
        OIE_pp_CmpLibCmd_CDmnMgr_CDmnMgr_Impl_OnCommandTrigByImpl_OnCommand: start-on-event=CDmnMgr_Impl_OnCommand, operation=pp_CmpLibCmd_CDmnMgr.Impl_OnCommand
        OIE_ppCS_DmnSystemStateChange_DmnMgr_DmnSystemStateChangeReqTrigByDmnSystemStateChangeReq: start-on-event=DmnMgr_DmnSystemStateChangeReq, operation=ppCS_DmnSystemStateChange.DmnSystemStateChangeReq
        OIE_ppCS_DmnSystemStateChange_DmnMgr_DmnSystemStateChangeStatusTrigByDmnSystemStateChangeStatus: start-on-event=DmnMgr_DmnSystemStateChangeStatus, operation=ppCS_DmnSystemStateChange.DmnSystemStateChangeStatus
        OIE_ppCS_UclSystemCallbacks_DmnMgr_ErrorNotificationTrigByErrorNotification: start-on-event=DmnMgr_ErrorNotification, operation=ppCS_UclSystemCallbacks.ErrorNotification
        OIE_ppCS_UclSystemCallbacks_DmnMgr_LinkStatusChangedTrigByLinkStatusChanged: start-on-event=DmnMgr_LinkStatusChanged, operation=ppCS_UclSystemCallbacks.LinkStatusChanged
      7 x data received event:
        DREDmnMgr_MonitorDmnExtendShutdownTimeTrigByPowerExtendShutdownTimeData: start-on-event=DmnMgr_MonitorDmnExtendShutdownTime, data=rSR_PowerExtendShutdownTime.PowerExtendShutdownTimeData
        DREDmnMgr_MonitorDmnHealthDumpDataTrigByHealthDumpDataData: start-on-event=DmnMgr_MonitorDmnHealthDumpData, data=rSR_HealthDumpData.HealthDumpDataData
        DREDmnMgr_MonitorDmnHealthDumpHdrInfoTrigByHealthDumpHdrInfoData: start-on-event=DmnMgr_MonitorDmnHealthDumpHdrInfo, data=rSR_HealthDumpHdrInfo.HealthDumpHdrInfoData
        DREDmnMgr_MonitorDmnHealthFatalErrorTrigByHealthDomainFatalErrorData: start-on-event=DmnMgr_MonitorDmnHealthFatalError, data=rSR_HealthDomainFatalError.HealthDomainFatalErrorData
        DREDmnMgr_MonitorDmnHeartBeatTrigByHealthDomainHeartbeatData: start-on-event=DmnMgr_MonitorDmnHeartBeat, data=rSR_HealthDomainHeartbeat.HealthDomainHeartbeatData
        DREDmnMgr_MonitorDmnKeepSystemAwakeTrigByPowerKeepSystemAwakeData: start-on-event=DmnMgr_MonitorDmnKeepSystemAwake, data=rSR_PowerKeepSystemAwake.PowerKeepSystemAwakeData
        DREDmnMgr_MonitorDmnPowerSystemStateTrigByPowerSystemStateData: start-on-event=DmnMgr_MonitorDmnPowerSystemState, data=rSR_PowerSystemState.PowerSystemStateData
      operation invoked event OIE_ppCS_DomainMonitoring_DmnMgr_StartDomainMonitoringTrigByStartDomainMonitoring: start-on-event=DmnMgr_StartDomainMonitoring, operation=ppCS_DomainMonitoring.StartDomainMonitoring
      operation invoked event OIE_ppCS_DomainMonitoring_DmnMgr_StopDomainMonitoringTrigByStopDomainMonitoring: start-on-event=DmnMgr_StopDomainMonitoring, operation=ppCS_DomainMonitoring.StopDomainMonitoring
      port-api-options:
        enable-take-address=false, indirect-api=false, port=pSR_HealthDumpGetData
        enable-take-address=false, indirect-api=false, port=pSR_HealthDumpGetHdr
        enable-take-address=false, indirect-api=false, port=pSR_PowerSystemStateReqChange
        enable-take-address=false, indirect-api=false, port=ppCS_DmnSystemStateChange
        enable-take-address=false, indirect-api=false, port=ppCS_DomainMonitoring
        enable-take-address=false, indirect-api=false, port=ppCS_UclSystemCallbacks
        enable-take-address=false, indirect-api=false, port=ppSR_DmnInfo
        enable-take-address=false, indirect-api=false, port=pp_CmpLibCmd_CDmnMgr
        enable-take-address=false, indirect-api=false, port=rSR_HealthDomainFatalError
        enable-take-address=false, indirect-api=false, port=rSR_HealthDomainHeartbeat
        enable-take-address=false, indirect-api=false, port=rSR_HealthDumpData
        enable-take-address=false, indirect-api=false, port=rSR_HealthDumpHdrInfo
        enable-take-address=false, indirect-api=false, port=rSR_PowerExtendShutdownTime
        enable-take-address=false, indirect-api=false, port=rSR_PowerKeepSystemAwake
        enable-take-address=false, indirect-api=false, port=rSR_PowerSystemState
        enable-take-address=false, indirect-api=false, port=rpCS_UclInitShutdown
        enable-take-address=false, indirect-api=false, port=rpSR_DmnInfo
        enable-take-address=false, indirect-api=false, port=DmnMgr/rp_CS_SleepOperation
      15 x runnable, all with can-be-invoked-concurrently=true:
        CDmnMgr_Impl_MainFunction
          data-receive-point-by-arguments:
            8 x access:
              DRP_rSR_HealthDomainFatalError_HealthDomainFatalErrorData: accessed-variable=rSR_HealthDomainFatalError.HealthDomainFatalErrorData
              DRP_rSR_HealthDomainHeartbeat_HealthDomainHeartbeatData: accessed-variable=rSR_HealthDomainHeartbeat.HealthDomainHeartbeatData
              DRP_rSR_HealthDumpData_HealthDumpDataData: accessed-variable=rSR_HealthDumpData.HealthDumpDataData
              DRP_rSR_HealthDumpHdrInfo_HealthDumpHdrInfoData: accessed-variable=rSR_HealthDumpHdrInfo.HealthDumpHdrInfoData
              DRP_rSR_PowerExtendShutdownTime_PowerExtendShutdownTimeData: accessed-variable=rSR_PowerExtendShutdownTime.PowerExtendShutdownTimeData
              DRP_rSR_PowerKeepSystemAwake_PowerKeepSystemAwakeData: accessed-variable=rSR_PowerKeepSystemAwake.PowerKeepSystemAwakeData
              DRA_rSR_PowerSystemState_PowerSystemStateData: accessed-variable=rSR_PowerSystemState.PowerSystemStateData
              DRA_rpSR_DmnInfo_SDmnStatus: accessed-variable=rpSR_DmnInfo.SDmnStatus
          data-send-points:
            4 x access:
              DSP_pSR_HealthDumpGetData_HealthDumpGetDataData: accessed-variable=pSR_HealthDumpGetData.HealthDumpGetDataData
              DSP_pSR_HealthDumpGetHdr_HealthDumpGetHdrData: accessed-variable=pSR_HealthDumpGetHdr.HealthDumpGetHdrData
              DWA_pSR_PowerSystemStateReqChange_PowerSystemStateReqChangeData: accessed-variable=pSR_PowerSystemStateReqChange.PowerSystemStateReqChangeData
              DWA_ppSR_DmnInfo_SDmnStatus: accessed-variable=ppSR_DmnInfo.SDmnStatus
          5 x sync call, all with timeout=0.0:
            OA_rpCS_UclInitShutdown_Impl_Shutdown: operation=rpCS_UclInitShutdown.Impl_Shutdown
            OA_rpCS_UclInitShutdown_Impl_Initialize: operation=rpCS_UclInitShutdown.Impl_Initialize
            OA_rp_CS_SleepOperation_CtrlWSS_ReadytoSleep: operation=rp_CS_SleepOperation.CtrlWSS_ReadytoSleep
            OA_rp_CS_SleepOperation_CtrlWSS_RequestSleep: operation=rp_CS_SleepOperation.CtrlWSS_RequestSleep
            OA_rp_CS_SleepOperation_CtrlWSS_CancelSleep: operation=rp_CS_SleepOperation.CtrlWSS_CancelSleep
        CDmnMgr_Impl_OnCommand
        DmnMgr_DmnSystemStateChangeReq
        DmnMgr_DmnSystemStateChangeStatus
        DmnMgr_ErrorNotification
        DmnMgr_LinkStatusChanged
        DmnMgr_MonitorDmnExtendShutdownTime
        DmnMgr_MonitorDmnHealthDumpData
        DmnMgr_MonitorDmnHealthDumpHdrInfo
        DmnMgr_MonitorDmnHealthFatalError
        DmnMgr_MonitorDmnHeartBeat
        DmnMgr_MonitorDmnKeepSystemAwake
        DmnMgr_MonitorDmnPowerSystemState
        DmnMgr_StartDomainMonitoring
        DmnMgr_StopDomainMonitoring
  constant specification DmnMgrPowerSystemStateReqChangeDataValue0: value-spec={short-label=DmnMgrPowerSystemStateReqChangeDataValue0, fields=[DmnMgrPowerSystemStateReqChangeDataValue_0:0, DmnMgrPowerSystemStateReqChangeDataValue_1:0]}
  constant specification DmnMgrSDmnStatusValue0: value-spec={short-label=DmnMgrSDmnStatusValue0, fields=[DmnMgrSDmnStatusValue_0:0, DmnMgrSDmnStatusValue_1:0, DmnMgrSDmnStatusValue_2:0, DmnMgrSDmnStatusValue_3:0, DmnMgrSDmnStatusValue_4:0, DmnMgrSDmnStatusValue_5:0]}
  constant specification DmnMgrPowerSystemStateDataValue0: value-spec={short-label=DmnMgrPowerSystemStateDataValue0, fields=[DmnMgrPowerSystemStateDataValue_0:0, DmnMgrPowerSystemStateDataValue_1:0]}
  swc implementation IMPL_DmnMgr: programming-language=C, behavior=IB_DmnMgr
    code-descriptors:
      code CodeDescriptor
